VERSION ""

NS_ :

BS_:

BU_: DTCO ICL COO11 SRR6TRightMaster_R_Master SRR6TLeftMaster_L_Master
VAL_TABLE_ ErrorBits 1 "TRUE" 0 "FALSE" ;

BO_ 3221225472 VECTOR__INDEPENDENT_SIG_MSG: 0 Vector__XXX
 SG_ SRR6T_F_Diag_Response : 0|64@1+ (1,0) [0|0] "" Vector__XXX
 SG_ UDS_BASIS : 0|8@1+ (1,0) [0|255] "-" Vector__XXX
 SG_ SRRF_Object_E2E_CRC_09 : 0|16@1+ (1,0) [0|65535] "-" Vector__XXX
 SG_ SRRF_Object_E2E_Counter_09 : 0|8@1+ (1,0) [0|255] "-" Vector__XXX
 SG_ BatchId_SRRObj_F_09 : 0|3@1+ (1,0) [0|5] "-" Vector__XXX
 SG_ LonPosition_F_17 : 0|13@1+ (0.0625,-254.9375) [-254.9375|254.9375] "m" Vector__XXX
 SG_ LonPositionStd_F_17 : 0|10@1+ (0.025,0.025) [0.025|20] "m" Vector__XXX
 SG_ LatPosition_F_17 : 0|13@1+ (0.0625,-254.9375) [-254.9375|254.9375] "m" Vector__XXX
 SG_ LatPositionStd_F_17 : 0|10@1+ (0.025,0.025) [0.025|20] "m" Vector__XXX
 SG_ LonGndVel_F_17 : 0|13@1+ (0.0625,-170) [-170|170] "m/s" Vector__XXX
 SG_ LonGndVelStd_F_17 : 0|10@1+ (0.025,0.025) [0.025|14] "m/s" Vector__XXX
 SG_ LatGndVel_F_17 : 0|13@1+ (0.0625,-170) [-170|170] "m/s" Vector__XXX
 SG_ LatGndVelStd_F_17 : 0|10@1+ (0.025,0.025) [0.025|14] "m/s" Vector__XXX
 SG_ ExistenceProbability_F_17 : 0|8@1+ (0.4,0) [0|100] "%" Vector__XXX
 SG_ Width_F_17 : 0|8@1+ (0.1,0) [0|4] "m" Vector__XXX
 SG_ Length_F_17 : 0|10@1+ (0.1,0) [0|60] "m" Vector__XXX
 SG_ HeadingAngle_F_17 : 0|8@1+ (0.02618,-3.1416) [-3.1416|3.1416] "rad" Vector__XXX
 SG_ DynamicProperty_F_17 : 0|3@1+ (1,0) [0|5] "-" Vector__XXX
 SG_ ClassMostProb_F_17 : 0|3@1+ (1,0) [0|5] "-" Vector__XXX
 SG_ ClassMostProbConf_F_17 : 0|8@1+ (0.4,0) [0|100] "%" Vector__XXX
 SG_ ClassSecMostProb_F_17 : 0|3@1+ (1,0) [0|5] "-" Vector__XXX
 SG_ ClassSecMostProbConf_F_17 : 0|8@1+ (0.4,0) [0|100] "%" Vector__XXX
 SG_ MaintenanceState_F_17 : 0|3@1+ (1,0) [0|3] "-" Vector__XXX
 SG_ YawRate_F_17 : 0|16@1+ (0.0001220703125,-3) [-3|3] "rad/s" Vector__XXX
 SG_ Occlusion_F_17 : 0|3@1+ (1,0) [0|3] "-" Vector__XXX
 SG_ TrackingId_F_17 : 0|8@1+ (1,0) [0|250] "-" Vector__XXX
 SG_ ReferencePoint_F_17 : 0|4@1+ (1,0) [0|8] "-" Vector__XXX
 SG_ RadarCrossSection_F_17 : 0|11@1+ (0.1,0) [-100|100] "dBm²" Vector__XXX
 SG_ AgeSinceCreated_F_17 : 0|10@1+ (0.01,0) [0|10] "s" Vector__XXX
 SG_ LonPosition_F_18 : 0|13@1+ (0.0625,-254.9375) [-254.9375|254.9375] "m" Vector__XXX
 SG_ LonPositionStd_F_18 : 0|10@1+ (0.025,0.025) [0.025|20] "m" Vector__XXX
 SG_ LatPosition_F_18 : 0|13@1+ (0.0625,-254.9375) [-254.9375|254.9375] "m" Vector__XXX
 SG_ LatPositionStd_F_18 : 0|10@1+ (0.025,0.025) [0.025|20] "m" Vector__XXX
 SG_ LonGndVel_F_18 : 0|13@1+ (0.0625,-170) [-170|170] "m/s" Vector__XXX
 SG_ LonGndVelStd_F_18 : 0|10@1+ (0.025,0.025) [0.025|14] "m/s" Vector__XXX
 SG_ LatGndVel_F_18 : 0|13@1+ (0.0625,-170) [-170|170] "m/s" Vector__XXX
 SG_ LatGndVelStd_F_18 : 0|10@1+ (0.025,0.025) [0.025|14] "m/s" Vector__XXX
 SG_ ExistenceProbability_F_18 : 0|8@1+ (0.4,0) [0|100] "%" Vector__XXX
 SG_ Width_F_18 : 0|8@1+ (0.1,0) [0|4] "m" Vector__XXX
 SG_ Length_F_18 : 0|10@1+ (0.1,0) [0|60] "m" Vector__XXX
 SG_ HeadingAngle_F_18 : 0|8@1+ (0.02618,-3.1416) [-3.1416|3.1416] "rad" Vector__XXX
 SG_ DynamicProperty_F_18 : 0|3@1+ (1,0) [0|5] "-" Vector__XXX
 SG_ ClassMostProb_F_18 : 0|3@1+ (1,0) [0|5] "-" Vector__XXX
 SG_ ClassMostProbConf_F_18 : 0|8@1+ (0.4,0) [0|100] "%" Vector__XXX
 SG_ ClassSecMostProb_F_18 : 0|3@1+ (1,0) [0|5] "-" Vector__XXX
 SG_ ClassSecMostProbConf_F_18 : 0|8@1+ (0.4,0) [0|100] "%" Vector__XXX
 SG_ MaintenanceState_F_18 : 0|3@1+ (1,0) [0|3] "-" Vector__XXX
 SG_ YawRate_F_18 : 0|16@1+ (0.0001220703125,-3) [-3|3] "rad/s" Vector__XXX
 SG_ Occlusion_F_18 : 0|3@1+ (1,0) [0|3] "-" Vector__XXX
 SG_ TrackingId_F_18 : 0|8@1+ (1,0) [0|250] "-" Vector__XXX
 SG_ ReferencePoint_F_18 : 0|4@1+ (1,0) [0|8] "-" Vector__XXX
 SG_ RadarCrossSection_F_18 : 0|11@1+ (0.1,0) [-100|100] "dbm²" Vector__XXX
 SG_ AgeSinceCreated_F_18 : 0|10@1+ (0.01,0) [0|10] "s" Vector__XXX

BO_ 2631566074 GW_UDSreq_FA_2SRR_FR: 8 COO11
 SG_ SRR6T_Diag_Request : 0|64@1+ (1,0) [0|0] ""  SRR6TRightMaster_R_Master,SRR6TLeftMaster_L_Master

BO_ 2564460274 GW_UDSreq_SRR_FR_UUDT: 8 COO11
 SG_ SRR6T_R_Diag_Request : 0|64@1+ (1,0) [0|0] ""  SRR6TRightMaster_R_Master

BO_ 2564485773 UDSresp_SRR2_UUDT: 8 SRR6TLeftMaster_L_Master
 SG_ UDS_BASIS : 0|8@1+ (1,0) [0|255] "-" Vector__XXX

BO_ 2631596677 UDSresp_FA_2SRR_RL: 8 SRR6TLeftMaster_L_Master
 SG_ SRR6T_R_Diag_Response : 0|64@1+ (1,0) [0|0] "" Vector__XXX

BO_ 2564485774 GW_UDSresp_SRR_UUDT_FR: 8 SRR6TRightMaster_R_Master
 SG_ SRR6T_R_Diag_Response : 0|8@1+ (1,0) [0|0] "" Vector__XXX

BO_ 2631596674 GW_UDSresp_FA_2SRR_FR: 8 SRR6TRightMaster_R_Master
 SG_ SRR6T_R_Diag_Response : 0|64@1+ (1,0) [0|0] ""  COO11

BO_ 2564460530 UDSreq_SRR_RR_UUDT: 8 COO11
 SG_ SRR6T_Diag_Request : 0|64@1+ (1,0) [0|0] ""  SRR6TRightMaster_R_Master

BO_ 2564459762 GW_UDSreq_SRR_UUDT: 8 COO11
 SG_ SRR6T_Diag_Request : 0|64@1+ (1,0) [0|0] ""  SRR6TLeftMaster_L_Master,SRR6TRightMaster_R_Master

BO_ 2565603215 SRR6T_DM1_DT_RR: 8 SRR6TRightMaster_R_Master
 SG_ DM1_DT_placeholder : 0|64@1+ (1,0) [0|1.84467440737096E+019] "" Vector__XXX

BO_ 2565603214 SRR6T_DM1_DT_FR: 8 SRR6TRightMaster_R_Master
 SG_ DM1_DT_placeholder : 0|64@1+ (1,0) [0|1.84467440737096E+019] "" Vector__XXX

BO_ 2564460018 UDSreq_SRR_RL_UUDT: 8 COO11
 SG_ SRR6T_Diag_Request : 0|64@1+ (1,0) [0|0] ""  SRR6TLeftMaster_L_Master

BO_ 2631663610 UDSreq_FCN_FA_2SRR: 8 COO11
 SG_ SRR6T_Diag_Request : 0|64@1+ (1,0) [0|0] ""  SRR6TRightMaster_R_Master,SRR6TLeftMaster_L_Master

BO_ 2564554737 UDSreq_FCN_F12SRR: 8 COO11
 SG_ SRR6T_Diag_Request : 0|64@1+ (1,0) [0|0] ""  SRR6TRightMaster_R_Master,SRR6TLeftMaster_L_Master

BO_ 2631566842 UDSreq_FA_2SRR: 8 COO11
 SG_ SRR6T_Diag_Request : 0|64@1+ (1,0) [0|0] ""  SRR6TLeftMaster_L_Master

BO_ 2631566330 UDSreq_FA_2SRR_RR: 8 COO11
 SG_ SRR6T_Diag_Request : 0|64@1+ (1,0) [0|0] ""  SRR6TRightMaster_R_Master

BO_ 2631566586 GW_UDSreq_FA_2SRR: 8 COO11
 SG_ SRR6T_Diag_Request : 0|64@1+ (1,0) [0|0] ""  SRR6TRightMaster_R_Master,SRR6TLeftMaster_L_Master

BO_ 2631596675 UDSresp_FA_2SRR_RR: 8 SRR6TRightMaster_R_Master
 SG_ SRR6T_R_Diag_Response : 0|64@1+ (1,0) [0|0] ""  COO11

BO_ 2564485772 GW_UDSresp_SRR_UUDT: 8 SRR6TLeftMaster_L_Master
 SG_ SRR6T_R_Diag_Response : 0|8@1+ (1,0) [0|0] ""  COO11

BO_ 2631596676 GW_UDSresp_FA_2SRR: 8 SRR6TLeftMaster_L_Master
 SG_ SRR6T_R_Diag_Response : 0|64@1+ (1,0) [0|0] ""  COO11

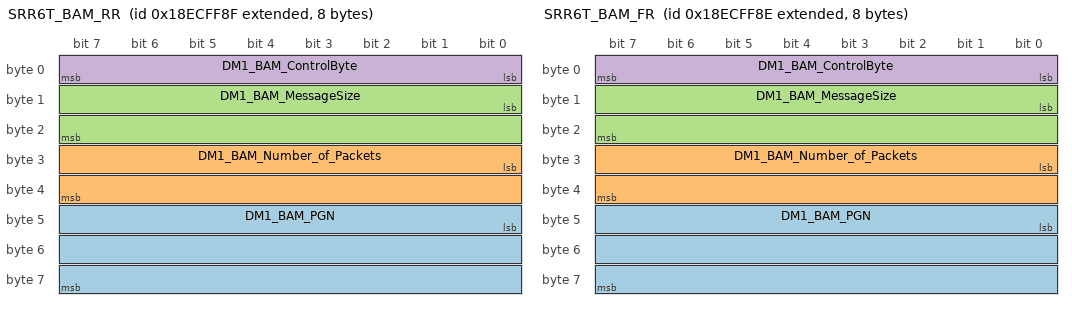
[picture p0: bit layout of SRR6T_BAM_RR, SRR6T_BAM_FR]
BO_ 2565668751 SRR6T_BAM_RR: 8 SRR6TRightMaster_R_Master
 SG_ DM1_BAM_PGN : 40|24@1+ (1,0) [0|16777215] "" Vector__XXX
 SG_ DM1_BAM_Number_of_Packets : 24|16@1+ (1,0) [0|65535] "" Vector__XXX
 SG_ DM1_BAM_MessageSize : 8|16@1+ (1,0) [0|65535] "" Vector__XXX
 SG_ DM1_BAM_ControlByte : 0|8@1+ (1,0) [0|255] "" Vector__XXX

BO_ 2565668750 SRR6T_BAM_FR: 8 SRR6TRightMaster_R_Master
 SG_ DM1_BAM_PGN : 40|24@1+ (1,0) [0|16777215] "" Vector__XXX
 SG_ DM1_BAM_Number_of_Packets : 24|16@1+ (1,0) [0|65535] "" Vector__XXX
 SG_ DM1_BAM_MessageSize : 8|16@1+ (1,0) [0|65535] "" Vector__XXX
 SG_ DM1_BAM_ControlByte : 0|8@1+ (1,0) [0|255] "" Vector__XXX

BO_ 2565603213 SRR6T_DM1_DT_RL: 8 SRR6TLeftMaster_L_Master
 SG_ DM1_DT_placeholder : 0|64@1+ (1,0) [0|1.84467440737096E+019] "" Vector__XXX

BO_ 2565603212 SRR6T_DM1_DT_FL: 8 SRR6TLeftMaster_L_Master
 SG_ DM1_DT_placeholder : 0|64@1+ (1,0) [0|1.84467440737096E+019] "" Vector__XXX

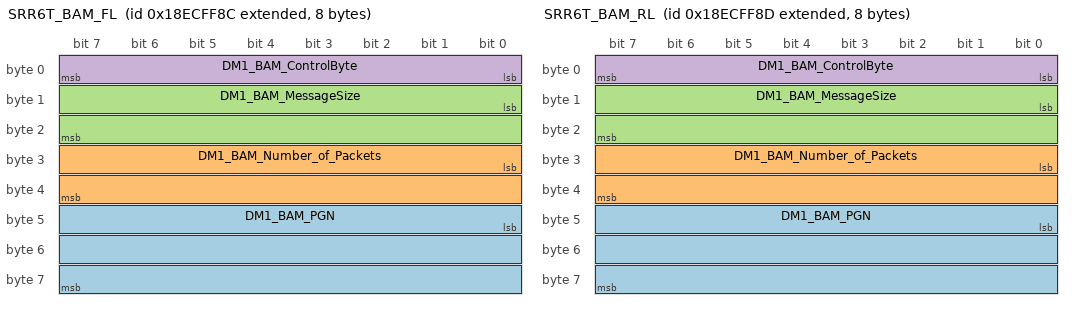
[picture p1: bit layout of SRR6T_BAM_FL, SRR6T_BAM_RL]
BO_ 2565668748 SRR6T_BAM_FL: 8 SRR6TLeftMaster_L_Master
 SG_ DM1_BAM_PGN : 40|24@1+ (1,0) [0|16777215] "" Vector__XXX
 SG_ DM1_BAM_Number_of_Packets : 24|16@1+ (1,0) [0|65535] "" Vector__XXX
 SG_ DM1_BAM_MessageSize : 8|16@1+ (1,0) [0|65535] "" Vector__XXX
 SG_ DM1_BAM_ControlByte : 0|8@1+ (1,0) [0|255] "" Vector__XXX

BO_ 2565668749 SRR6T_BAM_RL: 8 SRR6TLeftMaster_L_Master
 SG_ DM1_BAM_PGN : 40|24@1+ (1,0) [0|16777215] "" Vector__XXX
 SG_ DM1_BAM_Number_of_Packets : 24|16@1+ (1,0) [0|65535] "" Vector__XXX
 SG_ DM1_BAM_MessageSize : 8|16@1+ (1,0) [0|65535] "" Vector__XXX
 SG_ DM1_BAM_ControlByte : 0|8@1+ (1,0) [0|255] "" Vector__XXX

BO_ 2564485775 UDSresp_SRR4_UUDT: 8 SRR6TRightMaster_R_Master
 SG_ UDS_BASIS : 0|8@1+ (1,0) [0|255] "-"  COO11

BO_ 2566834829 DM1_SRR2D: 48 SRR6TLeftMaster_L_Master
 SG_ DM1_placeholder_BASE : 0|8@1+ (1,0) [0|255] "-"  COO11

BO_ 2566834831 DM1_SRR2B: 48 SRR6TRightMaster_R_Master
 SG_ DM1_placeholder_BASE : 0|8@1+ (1,0) [0|255] "-"  COO11

BO_ 2566834828 DM1_SRR2C: 48 SRR6TLeftMaster_L_Master
 SG_ DM1_placeholder_BASE : 0|8@1+ (1,0) [0|255] "-"  COO11

BO_ 2566834830 DM1_SRR2A: 48 SRR6TRightMaster_R_Master
 SG_ DM1_placeholder_BASE : 0|8@1+ (1,0) [0|255] "-"  COO11

BO_ 2564485262 UDSresp_SRR32F0: 8 SRR6TRightMaster_R_Master
 SG_ UDS_BASIS : 0|8@1+ (1,0) [0|255] "-"  COO11

BO_ 2564485374 UDSresp_SRR52F0: 8 Vector__XXX
 SG_ UDS_BASIS : 0|8@1+ (1,0) [0|255] "-"  COO11

BO_ 2564485260 UDSresp_SRR12F0: 8 SRR6TLeftMaster_L_Master
 SG_ UDS_BASIS : 0|8@1+ (1,0) [0|255] "-"  COO11

BO_ 2564485263 UDSresp_SRR42F0: 8 SRR6TRightMaster_R_Master
 SG_ UDS_BASIS : 0|8@1+ (1,0) [0|255] "-"  COO11

BO_ 2564485261 UDSresp_SRR22F0: 8 SRR6TLeftMaster_L_Master
 SG_ UDS_BASIS : 0|8@1+ (1,0) [0|255] "-"  COO11

BO_ 2564485518 UDSresp_SRR32F1: 8 SRR6TRightMaster_R_Master
 SG_ UDS_BASIS : 0|8@1+ (1,0) [0|255] "-"  COO11

BO_ 2564485630 UDSresp_SRR52F1: 8 Vector__XXX
 SG_ UDS_BASIS : 0|8@1+ (1,0) [0|255] "-"  COO11

BO_ 2564485519 UDSresp_SRR42F1: 8 SRR6TRightMaster_R_Master
 SG_ UDS_BASIS : 0|8@1+ (1,0) [0|255] "-"  COO11

BO_ 2564485517 UDSresp_SRR22F1: 8 SRR6TLeftMaster_L_Master
 SG_ UDS_BASIS : 0|8@1+ (1,0) [0|255] "-"  COO11

BO_ 2564485516 UDSresp_SRR12F1: 8 SRR6TLeftMaster_L_Master
 SG_ UDS_BASIS : 0|8@1+ (1,0) [0|255] "-"  COO11

BO_ 2564460273 UDSreq_F12SRR3: 8 COO11
 SG_ UDS_BASIS : 0|8@1+ (1,0) [0|255] "-"  SRR6TRightMaster_R_Master

BO_ 2564471025 UDSreq_F12SRR5: 8 COO11
 SG_ UDS_BASIS : 0|8@1+ (1,0) [0|255] "-" Vector__XXX

BO_ 2564460017 UDSreq_F12SRR2: 8 COO11
 SG_ UDS_BASIS : 0|8@1+ (1,0) [0|255] "-"  SRR6TLeftMaster_L_Master

BO_ 2564460529 UDSreq_F12SRR4: 8 COO11
 SG_ UDS_BASIS : 0|8@1+ (1,0) [0|255] "-"  SRR6TRightMaster_R_Master

BO_ 2564459761 UDSreq_F12SRR1: 8 COO11
 SG_ UDS_BASIS : 0|8@1+ (1,0) [0|255] "-"  SRR6TLeftMaster_L_Master

BO_ 2564460016 UDSreq_F02SRR2: 8 COO11
 SG_ UDS_BASIS : 0|8@1+ (1,0) [0|255] "-"  SRR6TLeftMaster_L_Master

BO_ 2564460272 UDSreq_F02SRR3: 8 COO11
 SG_ UDS_BASIS : 0|8@1+ (1,0) [0|255] "-"  SRR6TRightMaster_R_Master

BO_ 2564460528 UDSreq_F02SRR4: 8 COO11
 SG_ UDS_BASIS : 0|8@1+ (1,0) [0|255] "-"  SRR6TRightMaster_R_Master

BO_ 2564488944 UDSreq_F02SRR5: 8 COO11
 SG_ UDS_BASIS : 0|8@1+ (1,0) [0|255] "-" Vector__XXX

BO_ 2564459760 UDSreq_F02SRR1: 8 COO11
 SG_ UDS_BASIS : 0|8@1+ (1,0) [0|255] "-"  SRR6TLeftMaster_L_Master

BO_ 2564554736 UDSreqFCN_F0_TO_ALL: 8 COO11
 SG_ UDS_FCNF0_TO_ALL : 0|8@1+ (1,0) [0|255] "-"  SRR6TRightMaster_R_Master,SRR6TLeftMaster_L_Master

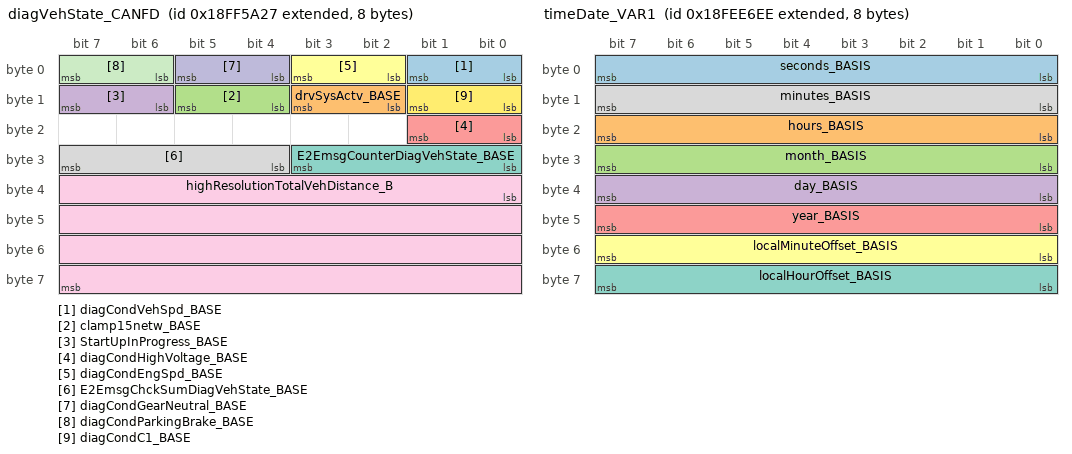
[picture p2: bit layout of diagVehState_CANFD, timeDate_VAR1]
BO_ 2566871591 diagVehState_CANFD: 8 COO11
 SG_ diagCondVehSpd_BASE : 0|2@1+ (1,0) [0|0] "-"  SRR6TLeftMaster_L_Master,SRR6TRightMaster_R_Master
 SG_ drvSysActv_BASE : 10|2@1+ (1,0) [0|0] "-"  SRR6TLeftMaster_L_Master,SRR6TRightMaster_R_Master
 SG_ clamp15netw_BASE : 12|2@1+ (1,0) [0|0] "-"  SRR6TLeftMaster_L_Master,SRR6TRightMaster_R_Master
 SG_ StartUpInProgress_BASE : 14|2@1+ (1,0) [0|3] "-"  SRR6TLeftMaster_L_Master,SRR6TRightMaster_R_Master
 SG_ diagCondHighVoltage_BASE : 16|2@1+ (1,0) [0|0] "-"  SRR6TLeftMaster_L_Master,SRR6TRightMaster_R_Master
 SG_ diagCondEngSpd_BASE : 2|2@1+ (1,0) [0|0] "-"  SRR6TLeftMaster_L_Master,SRR6TRightMaster_R_Master
 SG_ E2EmsgCounterDiagVehState_BASE : 24|4@1+ (1,0) [0|15] "count"  SRR6TLeftMaster_L_Master,SRR6TRightMaster_R_Master
 SG_ E2EmsgChckSumDiagVehState_BASE : 28|4@1+ (1,0) [0|15] "count"  SRR6TLeftMaster_L_Master,SRR6TRightMaster_R_Master
 SG_ highResolutionTotalVehDistance_B : 32|32@1+ (0.005,0) [0|21055406] "km"  SRR6TLeftMaster_L_Master,SRR6TRightMaster_R_Master
 SG_ diagCondGearNeutral_BASE : 4|2@1+ (1,0) [0|0] "-"  SRR6TLeftMaster_L_Master,SRR6TRightMaster_R_Master
 SG_ diagCondParkingBrake_BASE : 6|2@1+ (1,0) [0|0] "-"  SRR6TLeftMaster_L_Master,SRR6TRightMaster_R_Master
 SG_ diagCondC1_BASE : 8|2@1+ (1,0) [0|3] "-"  SRR6TLeftMaster_L_Master,SRR6TRightMaster_R_Master

BO_ 2566842094 timeDate_VAR1: 8 DTCO
 SG_ seconds_BASIS : 0|8@1+ (0.25,0) [0|62.5] "s"  SRR6TLeftMaster_L_Master,SRR6TRightMaster_R_Master
 SG_ hours_BASIS : 16|8@1+ (1,0) [0|250] "h"  SRR6TLeftMaster_L_Master,SRR6TRightMaster_R_Master
 SG_ month_BASIS : 24|8@1+ (1,0) [0|250] "month"  SRR6TLeftMaster_L_Master,SRR6TRightMaster_R_Master
 SG_ day_BASIS : 32|8@1+ (0.25,0) [0|62.5] "day"  SRR6TLeftMaster_L_Master,SRR6TRightMaster_R_Master
 SG_ year_BASIS : 40|8@1+ (1,1985) [1985|2235] "year"  SRR6TLeftMaster_L_Master,SRR6TRightMaster_R_Master
 SG_ localMinuteOffset_BASIS : 48|8@1+ (1,-125) [-125|125] "min"  SRR6TLeftMaster_L_Master,SRR6TRightMaster_R_Master
 SG_ localHourOffset_BASIS : 56|8@1+ (1,-125) [-125|125] "h"  SRR6TLeftMaster_L_Master,SRR6TRightMaster_R_Master
 SG_ minutes_BASIS : 8|8@1+ (1,0) [0|250] "min"  SRR6TLeftMaster_L_Master,SRR6TRightMaster_R_Master

BO_ 2600402983 NM: 8 COO11
 SG_ NM_SNI : 0|8@1+ (1,0) [0|255] "-" Vector__XXX
 SG_ NM_CBV_Res2 : 10|1@1+ (1,0) [0|1] "-"  SRR6TRightMaster_R_Master,SRR6TLeftMaster_L_Master
 SG_ NM_CBV_Res3 : 11|1@1+ (1,0) [0|1] "-"  SRR6TRightMaster_R_Master,SRR6TLeftMaster_L_Master
 SG_ NM_ActiveWakeupBit : 12|1@1+ (1,0) [0|0] "-"  SRR6TRightMaster_R_Master,SRR6TLeftMaster_L_Master
 SG_ NM_CBV_Res5 : 13|1@1+ (1,0) [0|1] "-"  SRR6TRightMaster_R_Master,SRR6TLeftMaster_L_Master
 SG_ NM_CRI : 14|1@1+ (1,0) [0|0] "-"  SRR6TRightMaster_R_Master,SRR6TLeftMaster_L_Master
 SG_ NM_CBV_Res7 : 15|1@1+ (1,0) [0|1] "-"  SRR6TRightMaster_R_Master,SRR6TLeftMaster_L_Master
 SG_ NM_State : 16|6@1+ (1,0) [0|0] "-"  SRR6TRightMaster_R_Master,SRR6TLeftMaster_L_Master
 SG_ NM_CarWakeup : 22|1@1+ (1,0) [0|0] "-"  SRR6TRightMaster_R_Master,SRR6TLeftMaster_L_Master
 SG_ NM_CC : 23|1@1+ (1,0) [0|0] "-"  SRR6TRightMaster_R_Master,SRR6TLeftMaster_L_Master
 SG_ NM_activeClamp15 : 24|1@1+ (1,0) [0|1] "-"  SRR6TRightMaster_R_Master,SRR6TLeftMaster_L_Master
 SG_ NM_activeDiag : 25|1@1+ (1,0) [0|0] "-"  SRR6TRightMaster_R_Master,SRR6TLeftMaster_L_Master
 SG_ NM_activeTmin : 26|1@1+ (1,0) [0|0] "-"  SRR6TRightMaster_R_Master,SRR6TLeftMaster_L_Master
 SG_ NM_activeCWU : 27|1@1+ (1,0) [0|0] "-"  SRR6TRightMaster_R_Master,SRR6TLeftMaster_L_Master
 SG_ NM_activeFC : 28|1@1+ (1,0) [0|0] "-"  SRR6TRightMaster_R_Master,SRR6TLeftMaster_L_Master
 SG_ NM_Res29 : 29|7@1+ (1,0) [0|127] "-"  SRR6TRightMaster_R_Master,SRR6TLeftMaster_L_Master
 SG_ NM_Res36 : 36|4@1+ (1,0) [0|15] "-"  SRR6TRightMaster_R_Master,SRR6TLeftMaster_L_Master
 SG_ nmClusterActive00 : 40|1@1+ (1,0) [0|0] "-"  SRR6TRightMaster_R_Master,SRR6TLeftMaster_L_Master
 SG_ nmClusterActive01 : 41|1@1+ (1,0) [0|0] "-"  SRR6TRightMaster_R_Master,SRR6TLeftMaster_L_Master
 SG_ nmClusterActive02 : 42|1@1+ (1,0) [0|0] "-"  SRR6TRightMaster_R_Master,SRR6TLeftMaster_L_Master
 SG_ nmClusterActive03 : 43|1@1+ (1,0) [0|0] "-"  SRR6TRightMaster_R_Master,SRR6TLeftMaster_L_Master
 SG_ nmClusterActive04 : 44|1@1+ (1,0) [0|0] "-"  SRR6TRightMaster_R_Master,SRR6TLeftMaster_L_Master
 SG_ nmClusterActive05 : 45|1@1+ (1,0) [0|0] "-"  SRR6TRightMaster_R_Master,SRR6TLeftMaster_L_Master
 SG_ nmClusterActive06 : 46|1@1+ (1,0) [0|0] "-"  SRR6TRightMaster_R_Master,SRR6TLeftMaster_L_Master
 SG_ nmClusterActive07 : 47|1@1+ (1,0) [0|0] "-"  SRR6TRightMaster_R_Master,SRR6TLeftMaster_L_Master
 SG_ nmClusterActive08 : 48|1@1+ (1,0) [0|0] "-"  SRR6TRightMaster_R_Master,SRR6TLeftMaster_L_Master
 SG_ nmClusterActive09 : 49|1@1+ (1,0) [0|0] "-"  SRR6TRightMaster_R_Master,SRR6TLeftMaster_L_Master
 SG_ nmClusterActive10 : 50|1@1+ (1,0) [0|0] "-"  SRR6TRightMaster_R_Master,SRR6TLeftMaster_L_Master
 SG_ nmClusterActive11 : 51|1@1+ (1,0) [0|0] "-"  SRR6TRightMaster_R_Master,SRR6TLeftMaster_L_Master
 SG_ nmClusterActive12 : 52|1@1+ (1,0) [0|0] "-"  SRR6TRightMaster_R_Master,SRR6TLeftMaster_L_Master
 SG_ nmClusterActive13 : 53|1@1+ (1,0) [0|0] "-"  SRR6TRightMaster_R_Master,SRR6TLeftMaster_L_Master
 SG_ nmClusterActive14 : 54|1@1+ (1,0) [0|0] "-"  SRR6TRightMaster_R_Master,SRR6TLeftMaster_L_Master
 SG_ nmClusterActive15 : 55|1@1+ (1,0) [0|0] "-"  SRR6TRightMaster_R_Master,SRR6TLeftMaster_L_Master
 SG_ nmClusterActive16 : 56|1@1+ (1,0) [0|0] "-"  SRR6TRightMaster_R_Master,SRR6TLeftMaster_L_Master
 SG_ nmClusterActive17 : 57|1@1+ (1,0) [0|0] "-"  SRR6TRightMaster_R_Master,SRR6TLeftMaster_L_Master
 SG_ nmClusterActive18 : 58|1@1+ (1,0) [0|0] "-"  SRR6TRightMaster_R_Master,SRR6TLeftMaster_L_Master
 SG_ nmClusterActive19 : 59|1@1+ (1,0) [0|0] "-"  SRR6TRightMaster_R_Master,SRR6TLeftMaster_L_Master
 SG_ nmClusterActive20 : 60|1@1+ (1,0) [0|0] "-"  SRR6TRightMaster_R_Master,SRR6TLeftMaster_L_Master
 SG_ nmClusterActive21 : 61|1@1+ (1,0) [0|0] "-"  SRR6TRightMaster_R_Master,SRR6TLeftMaster_L_Master
 SG_ nmClusterActive22 : 62|1@1+ (1,0) [0|0] "-"  SRR6TRightMaster_R_Master,SRR6TLeftMaster_L_Master
 SG_ nmClusterActive23 : 63|1@1+ (1,0) [0|0] "-"  SRR6TRightMaster_R_Master,SRR6TLeftMaster_L_Master
 SG_ NM_CBV_Res0 : 8|1@1+ (1,0) [0|1] "-"  SRR6TRightMaster_R_Master,SRR6TLeftMaster_L_Master
 SG_ NM_CBV_Res1 : 9|1@1+ (1,0) [0|1] "-"  SRR6TRightMaster_R_Master,SRR6TLeftMaster_L_Master

BO_ 2566566695 CanTSyn_CANFD_K: 8 COO11
 SG_ Type M : 0|8@1+ (1,0) [0|0] "-"  SRR6TRightMaster_R_Master,SRR6TLeftMaster_L_Master
 SG_ CRC_Sync m32 : 8|8@1+ (1,0) [0|255] "-"  SRR6TRightMaster_R_Master,SRR6TLeftMaster_L_Master
 SG_ CRC_Fup m40 : 8|8@1+ (1,0) [0|255] "-"  SRR6TRightMaster_R_Master,SRR6TLeftMaster_L_Master
 SG_ SequenceCounter_Sync m32 : 16|4@1+ (1,0) [0|15] "-"  SRR6TRightMaster_R_Master,SRR6TLeftMaster_L_Master
 SG_ SequenceCounter_Fup m40 : 16|4@1+ (1,0) [0|15] "-"  SRR6TRightMaster_R_Master,SRR6TLeftMaster_L_Master
 SG_ TimeDomain_Sync m32 : 20|4@1+ (1,0) [0|15] "-"  SRR6TRightMaster_R_Master,SRR6TLeftMaster_L_Master
 SG_ TimeDomain_Fup m40 : 20|4@1+ (1,0) [0|15] "-"  SRR6TRightMaster_R_Master,SRR6TLeftMaster_L_Master
 SG_ UserByte0_Sync m32 : 24|8@1+ (1,0) [0|255] "-"  SRR6TRightMaster_R_Master,SRR6TLeftMaster_L_Master
 SG_ OVS_Fup m40 : 24|2@1+ (1,0) [0|3] "-"  SRR6TRightMaster_R_Master,SRR6TLeftMaster_L_Master
 SG_ SGW_Fup m40 : 26|1@1+ (1,0) [0|1] "-"  SRR6TRightMaster_R_Master,SRR6TLeftMaster_L_Master
 SG_ Reserved_Fup m40 : 27|5@1+ (1,0) [0|31] "-"  SRR6TRightMaster_R_Master,SRR6TLeftMaster_L_Master
 SG_ SyncTimeSec_Sync m32 : 39|32@0+ (1,0) [0|4294967295] "s"  SRR6TRightMaster_R_Master,SRR6TLeftMaster_L_Master
 SG_ SyncTimeNSec_Fup m40 : 39|32@0+ (1,0) [0|4294967295] ""  SRR6TRightMaster_R_Master,SRR6TLeftMaster_L_Master

BO_ 2566843533 VI_5000_L_SRR2: 8 SRR6TLeftMaster_L_Master
 SG_ VehicleID_7digits_L_SRR2 : 0|56@1+ (1,0) [0|0] ""  COO11
 SG_ Delimiter_L_SRR2 : 56|8@1+ (1,0) [0|250] "ASCII '*'"  COO11

BO_ 2566843535 VI_5000_R_SRR2: 8 SRR6TRightMaster_R_Master
 SG_ VehicleID_7digits_R_SRR2 : 0|56@1+ (1,0) [0|0] ""  COO11
 SG_ Delimiter_R_SRR2 : 56|8@1+ (1,0) [0|250] "ASCII '*'"  COO11

BO_ 2399091597 SRRL_Header_SRR2: 64 SRR6TLeftMaster_L_Master
 SG_ Scan_Index_L : 304|16@1+ (1,0) [0|65535] "" Vector__XXX
 SG_ SlaveDetectionTimestampSeconds_L : 272|32@1+ (1,0) [0|4294967295] "s" Vector__XXX
 SG_ SlaveDetTimestampNanosec_L : 240|32@1+ (1,0) [0|999999999] "ns" Vector__XXX
 SG_ MasterDetectionTimestampSeconds_ : 208|32@1+ (1,0) [0|4294967295] "s" Vector__XXX
 SG_ MasterDetTimestampNanosec_L : 176|32@1+ (1,0) [0|999999999] "ns" Vector__XXX
 SG_ SRRL_Header_E2E_CRC : 0|16@1+ (1,0) [0|65535] "-"  COO11
 SG_ SRRL_Header_E2E_Counter : 16|8@1+ (1,0) [0|255] "-"  COO11
 SG_ BatchId_SRRHead_L : 24|3@1+ (1,0) [0|5] "-"  COO11
 SG_ StateMachineStatus_L : 27|4@1+ (1,0) [0|4] "-"  COO11
 SG_ BlockageMaster_L : 31|2@1+ (1,0) [0|1] "-"  COO11
 SG_ BlockageSlave_L : 33|2@1+ (1,0) [0|1] "-"  COO11
 SG_ TemperatureMaster_L : 35|8@1+ (1,-50) [-50|200] "deg celsius"  COO11
 SG_ TemperatureSlave_L : 43|8@1+ (1,-50) [-50|200] "deg celsius"  COO11
 SG_ AlignmentAngleMaster_L : 51|8@1+ (0.00136353847,-0.17180584722) [-0.17180584722|0.17180584722] "rad"  COO11
 SG_ AlignmentAngleSlave_L : 59|8@1+ (0.00136353847,-0.17180584722) [-0.17180584722|0.17180584722] "rad"  COO11
 SG_ AlignmentStatusMaster_L : 67|3@1+ (1,0) [0|3] "-"  COO11
 SG_ AlignmentStatusSlave_L : 70|3@1+ (1,0) [0|3] "-"  COO11
 SG_ AutoAlignmentActiveMaster_L : 73|2@1+ (1,0) [0|1] "-"  COO11
 SG_ AutoAlignmentActiveSlave_L : 75|2@1+ (1,0) [0|1] "-"  COO11
 SG_ ErrorBits_L : 77|32@1+ (1,0) [0|1] "-"  COO11
 SG_ ObjectTimestampSeconds_L : 109|32@1+ (1,0) [0|4294967295] "s"  COO11
 SG_ ObjectTimestampNanoseconds_L : 141|32@1+ (1,0) [0|999999999] "ns"  COO11
 SG_ CanTSynState_L : 173|3@1+ (1,0) [0|7] "-"  COO11

BO_ 2399091599 SRRR_Header_SRR2: 64 SRR6TRightMaster_R_Master
 SG_ Scan_Index_R : 304|16@1+ (1,0) [0|65535] "" Vector__XXX
 SG_ SlaveDetectionTimestampSeconds_R : 272|32@1+ (1,0) [0|4294967295] "s" Vector__XXX
 SG_ SlaveDetTimestampNanosec_R : 240|32@1+ (1,0) [0|999999999] "ns" Vector__XXX
 SG_ MasterDetectionTimestampSec_0000 : 208|32@1+ (1,0) [0|4294967295] "s" Vector__XXX
 SG_ MasterDetTimestampNanosec_R : 176|32@1+ (1,0) [0|999999999] "ns" Vector__XXX
 SG_ SRRR_Header_E2E_CRC : 0|16@1+ (1,0) [0|65535] "-"  COO11
 SG_ SRRR_Header_E2E_Counter : 16|8@1+ (1,0) [0|255] "-"  COO11
 SG_ BatchId_SRRHead_R : 24|3@1+ (1,0) [0|5] "-"  COO11
 SG_ StateMachineStatus_R : 27|4@1+ (1,0) [0|4] "-"  COO11
 SG_ BlockageMaster_R : 31|2@1+ (1,0) [0|1] "-"  COO11
 SG_ BlockageSlave_R : 33|2@1+ (1,0) [0|1] "-"  COO11
 SG_ TemperatureMaster_R : 35|8@1+ (1,-50) [-50|200] "deg celsius"  COO11
 SG_ TemperatureSlave_R : 43|8@1+ (1,-50) [-50|200] "deg celsius"  COO11
 SG_ AlignmentAngleMaster_R : 51|8@1+ (0.00136353847,-0.17180584722) [-0.17180584722|0.17180584722] "rad"  COO11
 SG_ AlignmentAngleSlave_R : 59|8@1+ (0.00136353847,-0.17180584722) [-0.17180584722|0.17180584722] "rad"  COO11
 SG_ AlignmentStatusMaster_R : 67|3@1+ (1,0) [0|3] "-"  COO11
 SG_ AlignmentStatusSlave_R : 70|3@1+ (1,0) [0|3] "-"  COO11
 SG_ AutoAlignmentActiveMaster_R : 73|2@1+ (1,0) [0|1] "-"  COO11
 SG_ AutoAlignmentActiveSlave_R : 75|2@1+ (1,0) [0|1] "-"  COO11
 SG_ ErrorBits_R : 77|32@1+ (1,0) [0|1] "-"  COO11
 SG_ ObjectTimestampSeconds_R : 109|32@1+ (1,0) [0|4294967295] "s"  COO11
 SG_ ObjectTimestampNanoseconds_R : 141|32@1+ (1,0) [0|999999999] "ns"  COO11
 SG_ CanTSynState_R : 173|3@1+ (1,0) [0|7] "-"  COO11

BO_ 2399092621 SRRL_TrailerInfo_SRR2: 20 SRR6TLeftMaster_L_Master
 SG_ SRRL_TrailerInfo_E2E_CRC : 0|16@1+ (1,0) [0|65535] "-"  COO11
 SG_ SRRL_TrailerInfo_E2E_Counter : 16|8@1+ (1,0) [0|255] "-"  COO11
 SG_ BatchId_SRRTrai_L : 24|3@1+ (1,0) [0|5] "-"  COO11
 SG_ TrailerFilterState_L : 27|3@1+ (1,0) [0|3] "-"  COO11
 SG_ Trailer1Present_L : 30|2@1+ (1,0) [0|3] "-"  COO11
 SG_ Trailer1Length_L : 32|8@1+ (0.1,0) [0|25] "m"  COO11
 SG_ Trailer1Width_L : 40|6@1+ (0.1,0) [0|6] "m"  COO11
 SG_ Trailer1Angle_L : 46|12@1+ (0.001953125,-3.142578125) [-3.142578125|3.142578125] "rad"  COO11
 SG_ Trailer1AngleConf_L : 58|4@1+ (1,0) [0|3] "-"  COO11
 SG_ Trailer1CentOfRotToCentDist_L : 62|7@1+ (0.1,0) [0|12.5] "m"  COO11
 SG_ Trailer1CentOfRotToWheelDist_L : 69|9@1+ (0.1,0) [0|50] "m"  COO11
 SG_ Trailer1CentOfRotVCSLon_L : 78|8@1+ (0.1,-24.5) [-24.5|0.5] "m"  COO11
 SG_ Trailer1CentOfRotVCSLat_L : 86|9@1+ (0.1,-24.5) [-24.5|26.4] "m"  COO11
 SG_ Trailer2Present_L : 95|2@1+ (1,0) [0|3] "-"  COO11
 SG_ Trailer2Length_L : 97|8@1+ (0.1,0) [0|25] "m"  COO11
 SG_ Trailer2Width_L : 105|6@1+ (0.1,0) [0|6] "m"  COO11
 SG_ Trailer2Angle_L : 111|12@1+ (0.001953125,-3.142578125) [-3.142578125|3.142578125] "rad"  COO11
 SG_ Trailer2AngleConf_L : 123|4@1+ (1,0) [0|3] "-"  COO11
 SG_ Trailer2CentOfRotToCentDist_L : 127|7@1+ (0.1,0) [0|12.5] "m"  COO11
 SG_ Trailer2CentOfRotToWheelDist_L : 134|9@1+ (0.1,0) [0|50] "m"  COO11
 SG_ Trailer2CentOfRotVCSLon_L : 143|8@1+ (0.1,-24.5) [-24.5|0.5] "m"  COO11
 SG_ Trailer2CentOfRotVCSLat_L : 151|9@1+ (0.1,-24.5) [-24.5|26.4] "m"  COO11

BO_ 2399092623 SRRR_TrailerInfo_SRR2: 20 SRR6TRightMaster_R_Master
 SG_ SRRR_TrailerInfo_E2E_CRC : 0|16@1+ (1,0) [0|65535] "-"  COO11
 SG_ SRRR_TrailerInfo_E2E_Counter : 16|8@1+ (1,0) [0|255] "-"  COO11
 SG_ BatchId_SRRTrai_R : 24|3@1+ (1,0) [0|5] "-"  COO11
 SG_ TrailerFilterState_R : 27|3@1+ (1,0) [0|3] "-"  COO11
 SG_ Trailer1Present_R : 30|2@1+ (1,0) [0|3] "-"  COO11
 SG_ Trailer1Length_R : 32|8@1+ (0.1,0) [0|25] "m"  COO11
 SG_ Trailer1Width_R : 40|6@1+ (0.1,0) [0|6] "m"  COO11
 SG_ Trailer1Angle_R : 46|12@1+ (0.001953125,-3.142578125) [-3.142578125|3.142578125] "rad"  COO11
 SG_ Trailer1AngleConf_R : 58|4@1+ (1,0) [0|3] "-"  COO11
 SG_ Trailer1CentOfRotToCentDist_R : 62|7@1+ (0.1,0) [0|12.5] "m"  COO11
 SG_ Trailer1CentOfRotToWheelDist_R : 69|9@1+ (0.1,0) [0|50] "m"  COO11
 SG_ Trailer1CentOfRotVCSLon_R : 78|8@1+ (0.1,-24.5) [-24.5|0.5] "m"  COO11
 SG_ Trailer1CentOfRotVCSLat_R : 86|9@1+ (0.1,-24.5) [-24.5|26.4] "m"  COO11
 SG_ Trailer2Present_R : 95|2@1+ (1,0) [0|3] "-"  COO11
 SG_ Trailer2Length_R : 97|8@1+ (0.1,0) [0|25] "m"  COO11
 SG_ Trailer2Width_R : 105|6@1+ (0.1,0) [0|6] "m"  COO11
 SG_ Trailer2Angle_R : 111|12@1+ (0.001953125,-3.142578125) [-3.142578125|3.142578125] "rad"  COO11
 SG_ Trailer2AngleConf_R : 123|4@1+ (1,0) [0|3] "-"  COO11
 SG_ Trailer2CentOfRotToCentDist_R : 127|7@1+ (0.1,0) [0|12.5] "m"  COO11
 SG_ Trailer2CentOfRotToWheelDist_R : 134|9@1+ (0.1,0) [0|50] "m"  COO11
 SG_ Trailer2CentOfRotVCSLon_R : 143|8@1+ (0.1,-24.5) [-24.5|0.5] "m"  COO11
 SG_ Trailer2CentOfRotVCSLat_R : 151|9@1+ (0.1,-24.5) [-24.5|26.4] "m"  COO11

BO_ 2399091853 SRRL_RoadBoundaryHeader_SRR2: 16 SRR6TLeftMaster_L_Master
 SG_ SRRL_RoadBoundaryHeader_E2E_CRC : 0|16@1+ (1,0) [0|65535] "-"  COO11
 SG_ SRRL_RoadBoundaryHeader_E2E_Cntr : 16|8@1+ (1,0) [0|255] "-"  COO11
 SG_ BatchId_SRRBoundHdr_L : 24|3@1+ (1,0) [0|5] "-"  COO11
 SG_ NumCountours_L : 27|4@1+ (1,0) [0|6] "-"  COO11
 SG_ CountourId_L_01 : 31|6@1+ (1,0) [0|61] "-"  COO11
 SG_ NumCountourVertices_L_01 : 37|6@1+ (1,0) [0|32] "-"  COO11
 SG_ CountourId_L_02 : 43|6@1+ (1,0) [0|61] "-"  COO11
 SG_ NumCountourVertices_L_02 : 49|6@1+ (1,0) [0|32] "-"  COO11
 SG_ CountourId_L_03 : 55|6@1+ (1,0) [0|61] "-"  COO11
 SG_ NumCountourVertices_L_03 : 61|6@1+ (1,0) [0|32] "-"  COO11
 SG_ CountourId_L_04 : 67|6@1+ (1,0) [0|61] "-"  COO11
 SG_ NumCountourVertices_L_04 : 73|6@1+ (1,0) [0|32] "-"  COO11
 SG_ CountourId_L_05 : 79|6@1+ (1,0) [0|61] "-"  COO11
 SG_ NumCountourVertices_L_05 : 85|6@1+ (1,0) [0|32] "-"  COO11
 SG_ CountourId_L_06 : 91|6@1+ (1,0) [0|61] "-"  COO11
 SG_ NumCountourVertices_L_06 : 97|6@1+ (1,0) [0|32] "-"  COO11

BO_ 2399092109 SRRL_RoadBndrySegs_01_SRR2: 64 SRR6TLeftMaster_L_Master
 SG_ SRRL_RoadBndrySegs_E2E_CRC_01 : 0|16@1+ (1,0) [0|65535] "-"  COO11
 SG_ SRRL_RoadBndrySegs_E2E_Cntr_01 : 16|8@1+ (1,0) [0|255] "-"  COO11
 SG_ BatchId_SRRBoundSegs_L_01 : 24|3@1+ (1,0) [0|5] "-"  COO11
 SG_ VertexAge_L_01 : 27|6@1+ (1,0) [0|61] "-"  COO11
 SG_ VertexPosX_L_01 : 33|12@1+ (0.0625,-50) [-50|150] "m"  COO11
 SG_ VertexPosY_L_01 : 45|11@1+ (0.03125,-30) [-30|30] "m"  COO11
 SG_ VertexAge_L_02 : 56|6@1+ (1,0) [0|61] "-"  COO11
 SG_ VertexPosX_L_02 : 62|12@1+ (0.0625,-50) [-50|150] "m"  COO11
 SG_ VertexPosY_L_02 : 74|11@1+ (0.03125,-30) [-30|30] "m"  COO11
 SG_ VertexAge_L_03 : 85|6@1+ (1,0) [0|61] "-"  COO11
 SG_ VertexPosX_L_03 : 91|12@1+ (0.0625,-50) [-50|150] "m"  COO11
 SG_ VertexPosY_L_03 : 103|11@1+ (0.03125,-30) [-30|30] "m"  COO11
 SG_ VertexAge_L_04 : 114|6@1+ (1,0) [0|61] "-"  COO11
 SG_ VertexPosX_L_04 : 120|12@1+ (0.0625,-50) [-50|150] "m"  COO11
 SG_ VertexPosY_L_04 : 132|11@1+ (0.03125,-30) [-30|30] "m"  COO11
 SG_ VertexAge_L_05 : 143|6@1+ (1,0) [0|61] "-"  COO11
 SG_ VertexPosX_L_05 : 149|12@1+ (0.0625,-50) [-50|150] "m"  COO11
 SG_ VertexPosY_L_05 : 161|11@1+ (0.03125,-30) [-30|30] "m"  COO11
 SG_ VertexAge_L_06 : 172|6@1+ (1,0) [0|61] "-"  COO11
 SG_ VertexPosX_L_06 : 178|12@1+ (0.0625,-50) [-50|150] "m"  COO11
 SG_ VertexPosY_L_06 : 190|11@1+ (0.03125,-30) [-30|30] "m"  COO11
 SG_ VertexAge_L_07 : 201|6@1+ (1,0) [0|61] "-"  COO11
 SG_ VertexPosX_L_07 : 207|12@1+ (0.0625,-50) [-50|150] "m"  COO11
 SG_ VertexPosY_L_07 : 219|11@1+ (0.03125,-30) [-30|30] "m"  COO11
 SG_ VertexAge_L_08 : 230|6@1+ (1,0) [0|61] "-"  COO11
 SG_ VertexPosX_L_08 : 236|12@1+ (0.0625,-50) [-50|150] "m"  COO11
 SG_ VertexPosY_L_08 : 248|11@1+ (0.03125,-30) [-30|30] "m"  COO11
 SG_ VertexAge_L_09 : 259|6@1+ (1,0) [0|61] "-"  COO11
 SG_ VertexPosX_L_09 : 265|12@1+ (0.0625,-50) [-50|150] "m"  COO11
 SG_ VertexPosY_L_09 : 277|11@1+ (0.03125,-30) [-30|30] "m"  COO11
 SG_ VertexAge_L_10 : 288|6@1+ (1,0) [0|61] "-"  COO11
 SG_ VertexPosX_L_10 : 294|12@1+ (0.0625,-50) [-50|150] "m"  COO11
 SG_ VertexPosY_L_10 : 306|11@1+ (0.03125,-30) [-30|30] "m"  COO11
 SG_ VertexAge_L_11 : 317|6@1+ (1,0) [0|61] "-"  COO11
 SG_ VertexPosX_L_11 : 323|12@1+ (0.0625,-50) [-50|150] "m"  COO11
 SG_ VertexPosY_L_11 : 335|11@1+ (0.03125,-30) [-30|30] "m"  COO11
 SG_ VertexAge_L_12 : 346|6@1+ (1,0) [0|61] "-"  COO11
 SG_ VertexPosX_L_12 : 352|12@1+ (0.0625,-50) [-50|150] "m"  COO11
 SG_ VertexPosY_L_12 : 364|11@1+ (0.03125,-30) [-30|30] "m"  COO11
 SG_ VertexAge_L_13 : 375|6@1+ (1,0) [0|61] "-"  COO11
 SG_ VertexPosX_L_13 : 381|12@1+ (0.0625,-50) [-50|150] "m"  COO11
 SG_ VertexPosY_L_13 : 393|11@1+ (0.03125,-30) [-30|30] "m"  COO11
 SG_ VertexAge_L_14 : 404|6@1+ (1,0) [0|61] "-"  COO11
 SG_ VertexPosX_L_14 : 410|12@1+ (0.0625,-50) [-50|150] "m"  COO11
 SG_ VertexPosY_L_14 : 422|11@1+ (0.03125,-30) [-30|30] "m"  COO11
 SG_ VertexAge_L_15 : 433|6@1+ (1,0) [0|61] "-"  COO11
 SG_ VertexPosX_L_15 : 439|12@1+ (0.0625,-50) [-50|150] "m"  COO11
 SG_ VertexPosY_L_15 : 451|11@1+ (0.03125,-30) [-30|30] "m"  COO11
 SG_ VertexAge_L_16 : 462|6@1+ (1,0) [0|61] "-"  COO11
 SG_ VertexPosX_L_16 : 468|12@1+ (0.0625,-50) [-50|150] "m"  COO11
 SG_ VertexPosY_L_16 : 480|11@1+ (0.03125,-30) [-30|30] "m"  COO11

BO_ 2399092365 SRRL_RoadBndrySegs_02_SRR2: 64 SRR6TLeftMaster_L_Master
 SG_ SRRL_RoadBndrySegs_E2E_CRC_02 : 0|16@1+ (1,0) [0|65535] "-"  COO11
 SG_ SRRL_RoadBndrySegs_E2E_Cntr_02 : 16|8@1+ (1,0) [0|255] "-"  COO11
 SG_ BatchId_SRRBoundSegs_L_02 : 24|3@1+ (1,0) [0|5] "-"  COO11
 SG_ VertexAge_L_17 : 27|6@1+ (1,0) [0|61] "-"  COO11
 SG_ VertexPosX_L_17 : 33|12@1+ (0.0625,-50) [-50|150] "m"  COO11
 SG_ VertexPosY_L_17 : 45|11@1+ (0.03125,-30) [-30|30] "m"  COO11
 SG_ VertexAge_L_18 : 56|6@1+ (1,0) [0|61] "-"  COO11
 SG_ VertexPosX_L_18 : 62|12@1+ (0.0625,-50) [-50|150] "m"  COO11
 SG_ VertexPosY_L_18 : 74|11@1+ (0.03125,-30) [-30|30] "m"  COO11
 SG_ VertexAge_L_19 : 85|6@1+ (1,0) [0|61] "-"  COO11
 SG_ VertexPosX_L_19 : 91|12@1+ (0.0625,-50) [-50|150] "m"  COO11
 SG_ VertexPosY_L_19 : 103|11@1+ (0.03125,-30) [-30|30] "m"  COO11
 SG_ VertexAge_L_20 : 114|6@1+ (1,0) [0|61] "-"  COO11
 SG_ VertexPosX_L_20 : 120|12@1+ (0.0625,-50) [-50|150] "m"  COO11
 SG_ VertexPosY_L_20 : 132|11@1+ (0.03125,-30) [-30|30] "m"  COO11
 SG_ VertexAge_L_21 : 143|6@1+ (1,0) [0|61] "-"  COO11
 SG_ VertexPosX_L_21 : 149|12@1+ (0.0625,-50) [-50|150] "m"  COO11
 SG_ VertexPosY_L_21 : 161|11@1+ (0.03125,-30) [-30|30] "m"  COO11
 SG_ VertexAge_L_22 : 172|6@1+ (1,0) [0|61] "-"  COO11
 SG_ VertexPosX_L_22 : 178|12@1+ (0.0625,-50) [-50|150] "m"  COO11
 SG_ VertexPosY_L_22 : 190|11@1+ (0.03125,-30) [-30|30] "m"  COO11
 SG_ VertexAge_L_23 : 201|6@1+ (1,0) [0|61] "-"  COO11
 SG_ VertexPosX_L_23 : 207|12@1+ (0.0625,-50) [-50|150] "m"  COO11
 SG_ VertexPosY_L_23 : 219|11@1+ (0.03125,-30) [-30|30] "m"  COO11
 SG_ VertexAge_L_24 : 230|6@1+ (1,0) [0|61] "-"  COO11
 SG_ VertexPosX_L_24 : 236|12@1+ (0.0625,-50) [-50|150] "m"  COO11
 SG_ VertexPosY_L_24 : 248|11@1+ (0.03125,-30) [-30|30] "m"  COO11
 SG_ VertexAge_L_25 : 259|6@1+ (1,0) [0|61] "-"  COO11
 SG_ VertexPosX_L_25 : 265|12@1+ (0.0625,-50) [-50|150] "m"  COO11
 SG_ VertexPosY_L_25 : 277|11@1+ (0.03125,-30) [-30|30] "m"  COO11
 SG_ VertexAge_L_26 : 288|6@1+ (1,0) [0|61] "-"  COO11
 SG_ VertexPosX_L_26 : 294|12@1+ (0.0625,-50) [-50|150] "m"  COO11
 SG_ VertexPosY_L_26 : 306|11@1+ (0.03125,-30) [-30|30] "m"  COO11
 SG_ VertexAge_L_27 : 317|6@1+ (1,0) [0|61] "-"  COO11
 SG_ VertexPosX_L_27 : 323|12@1+ (0.0625,-50) [-50|150] "m"  COO11
 SG_ VertexPosY_L_27 : 335|11@1+ (0.03125,-30) [-30|30] "m"  COO11
 SG_ VertexAge_L_28 : 346|6@1+ (1,0) [0|61] "-"  COO11
 SG_ VertexPosX_L_28 : 352|12@1+ (0.0625,-50) [-50|150] "m"  COO11
 SG_ VertexPosY_L_28 : 364|11@1+ (0.03125,-30) [-30|30] "m"  COO11
 SG_ VertexAge_L_29 : 375|6@1+ (1,0) [0|61] "-"  COO11
 SG_ VertexPosX_L_29 : 381|12@1+ (0.0625,-50) [-50|150] "m"  COO11
 SG_ VertexPosY_L_29 : 393|11@1+ (0.03125,-30) [-30|30] "m"  COO11
 SG_ VertexAge_L_30 : 404|6@1+ (1,0) [0|61] "-"  COO11
 SG_ VertexPosX_L_30 : 410|12@1+ (0.0625,-50) [-50|150] "m"  COO11
 SG_ VertexPosY_L_30 : 422|11@1+ (0.03125,-30) [-30|30] "m"  COO11
 SG_ VertexAge_L_31 : 433|6@1+ (1,0) [0|61] "-"  COO11
 SG_ VertexPosX_L_31 : 439|12@1+ (0.0625,-50) [-50|150] "m"  COO11
 SG_ VertexPosY_L_31 : 451|11@1+ (0.03125,-30) [-30|30] "m"  COO11
 SG_ VertexAge_L_32 : 462|6@1+ (1,0) [0|61] "-"  COO11
 SG_ VertexPosX_L_32 : 468|12@1+ (0.0625,-50) [-50|150] "m"  COO11
 SG_ VertexPosY_L_32 : 480|11@1+ (0.03125,-30) [-30|30] "m"  COO11

BO_ 2399092111 SRRR_RoadBndrySegs_01_SRR2: 64 SRR6TRightMaster_R_Master
 SG_ SRRR_RoadBndrySegs_E2E_CRC_01 : 0|16@1+ (1,0) [0|65535] "-"  COO11
 SG_ SRRR_RoadBndrySegs_E2E_Cntr_01 : 16|8@1+ (1,0) [0|255] "-"  COO11
 SG_ BatchId_SRRBoundSegs_R_01 : 24|3@1+ (1,0) [0|5] "-"  COO11
 SG_ VertexAge_R_01 : 27|6@1+ (1,0) [0|61] "-"  COO11
 SG_ VertexPosX_R_01 : 33|12@1+ (0.0625,-50) [-50|150] "m"  COO11
 SG_ VertexPosY_R_01 : 45|11@1+ (0.03125,-30) [-30|30] "m"  COO11
 SG_ VertexAge_R_02 : 56|6@1+ (1,0) [0|61] "-"  COO11
 SG_ VertexPosX_R_02 : 62|12@1+ (0.0625,-50) [-50|150] "m"  COO11
 SG_ VertexPosY_R_02 : 74|11@1+ (0.03125,-30) [-30|30] "m"  COO11
 SG_ VertexAge_R_03 : 85|6@1+ (1,0) [0|61] "-"  COO11
 SG_ VertexPosX_R_03 : 91|12@1+ (0.0625,-50) [-50|150] "m"  COO11
 SG_ VertexPosY_R_03 : 103|11@1+ (0.03125,-30) [-30|30] "m"  COO11
 SG_ VertexAge_R_04 : 114|6@1+ (1,0) [0|61] "-"  COO11
 SG_ VertexPosX_R_04 : 120|12@1+ (0.0625,-50) [-50|150] "m"  COO11
 SG_ VertexPosY_R_04 : 132|11@1+ (0.03125,-30) [-30|30] "m"  COO11
 SG_ VertexAge_R_05 : 143|6@1+ (1,0) [0|61] "-"  COO11
 SG_ VertexPosX_R_05 : 149|12@1+ (0.0625,-50) [-50|150] "m"  COO11
 SG_ VertexPosY_R_05 : 161|11@1+ (0.03125,-30) [-30|30] "m"  COO11
 SG_ VertexAge_R_06 : 172|6@1+ (1,0) [0|61] "-"  COO11
 SG_ VertexPosX_R_06 : 178|12@1+ (0.0625,-50) [-50|150] "m"  COO11
 SG_ VertexPosY_R_06 : 190|11@1+ (0.03125,-30) [-30|30] "m"  COO11
 SG_ VertexAge_R_07 : 201|6@1+ (1,0) [0|61] "-"  COO11
 SG_ VertexPosX_R_07 : 207|12@1+ (0.0625,-50) [-50|150] "m"  COO11
 SG_ VertexPosY_R_07 : 219|11@1+ (0.03125,-30) [-30|30] "m"  COO11
 SG_ VertexAge_R_08 : 230|6@1+ (1,0) [0|61] "-"  COO11
 SG_ VertexPosX_R_08 : 236|12@1+ (0.0625,-50) [-50|150] "m"  COO11
 SG_ VertexPosY_R_08 : 248|11@1+ (0.03125,-30) [-30|30] "m"  COO11
 SG_ VertexAge_R_09 : 259|6@1+ (1,0) [0|61] "-"  COO11
 SG_ VertexPosX_R_09 : 265|12@1+ (0.0625,-50) [-50|150] "m"  COO11
 SG_ VertexPosY_R_09 : 277|11@1+ (0.03125,-30) [-30|30] "m"  COO11
 SG_ VertexAge_R_10 : 288|6@1+ (1,0) [0|61] "-"  COO11
 SG_ VertexPosX_R_10 : 294|12@1+ (0.0625,-50) [-50|150] "m"  COO11
 SG_ VertexPosY_R_10 : 306|11@1+ (0.03125,-30) [-30|30] "m"  COO11
 SG_ VertexAge_R_11 : 317|6@1+ (1,0) [0|61] "-"  COO11
 SG_ VertexPosX_R_11 : 323|12@1+ (0.0625,-50) [-50|150] "m"  COO11
 SG_ VertexPosY_R_11 : 335|11@1+ (0.03125,-30) [-30|30] "m"  COO11
 SG_ VertexAge_R_12 : 346|6@1+ (1,0) [0|61] "-"  COO11
 SG_ VertexPosX_R_12 : 352|12@1+ (0.0625,-50) [-50|150] "m"  COO11
 SG_ VertexPosY_R_12 : 364|11@1+ (0.03125,-30) [-30|30] "m"  COO11
 SG_ VertexAge_R_13 : 375|6@1+ (1,0) [0|61] "-"  COO11
 SG_ VertexPosX_R_13 : 381|12@1+ (0.0625,-50) [-50|150] "m"  COO11
 SG_ VertexPosY_R_13 : 393|11@1+ (0.03125,-30) [-30|30] "m"  COO11
 SG_ VertexAge_R_14 : 404|6@1+ (1,0) [0|61] "-"  COO11
 SG_ VertexPosX_R_14 : 410|12@1+ (0.0625,-50) [-50|150] "m"  COO11
 SG_ VertexPosY_R_14 : 422|11@1+ (0.03125,-30) [-30|30] "m"  COO11
 SG_ VertexAge_R_15 : 433|6@1+ (1,0) [0|61] "-"  COO11
 SG_ VertexPosX_R_15 : 439|12@1+ (0.0625,-50) [-50|150] "m"  COO11
 SG_ VertexPosY_R_15 : 451|11@1+ (0.03125,-30) [-30|30] "m"  COO11
 SG_ VertexAge_R_16 : 462|6@1+ (1,0) [0|61] "-"  COO11
 SG_ VertexPosX_R_16 : 468|12@1+ (0.0625,-50) [-50|150] "m"  COO11
 SG_ VertexPosY_R_16 : 480|11@1+ (0.03125,-30) [-30|30] "m"  COO11

BO_ 2399092367 SRRR_RoadBndrySegs_02_SRR2: 64 SRR6TRightMaster_R_Master
 SG_ SRRR_RoadBndrySegs_E2E_CRC_02 : 0|16@1+ (1,0) [0|65535] "-"  COO11
 SG_ SRRR_RoadBndrySegs_E2E_Cntr_02 : 16|8@1+ (1,0) [0|255] "-"  COO11
 SG_ BatchId_SRRBoundSegs_R_02 : 24|3@1+ (1,0) [0|5] "-"  COO11
 SG_ VertexAge_R_17 : 27|6@1+ (1,0) [0|61] "-"  COO11
 SG_ VertexPosX_R_17 : 33|12@1+ (0.0625,-50) [-50|150] "m"  COO11
 SG_ VertexPosY_R_17 : 45|11@1+ (0.03125,-30) [-30|30] "m"  COO11
 SG_ VertexAge_R_18 : 56|6@1+ (1,0) [0|61] "-"  COO11
 SG_ VertexPosX_R_18 : 62|12@1+ (0.0625,-50) [-50|150] "m"  COO11
 SG_ VertexPosY_R_18 : 74|11@1+ (0.03125,-30) [-30|30] "m"  COO11
 SG_ VertexAge_R_19 : 85|6@1+ (1,0) [0|61] "-"  COO11
 SG_ VertexPosX_R_19 : 91|12@1+ (0.0625,-50) [-50|150] "m"  COO11
 SG_ VertexPosY_R_19 : 103|11@1+ (0.03125,-30) [-30|30] "m"  COO11
 SG_ VertexAge_R_20 : 114|6@1+ (1,0) [0|61] "-"  COO11
 SG_ VertexPosX_R_20 : 120|12@1+ (0.0625,-50) [-50|150] "m"  COO11
 SG_ VertexPosY_R_20 : 132|11@1+ (0.03125,-30) [-30|30] "m"  COO11
 SG_ VertexAge_R_21 : 143|6@1+ (1,0) [0|61] "-"  COO11
 SG_ VertexPosX_R_21 : 149|12@1+ (0.0625,-50) [-50|150] "m"  COO11
 SG_ VertexPosY_R_21 : 161|11@1+ (0.03125,-30) [-30|30] "m"  COO11
 SG_ VertexAge_R_22 : 172|6@1+ (1,0) [0|61] "-"  COO11
 SG_ VertexPosX_R_22 : 178|12@1+ (0.0625,-50) [-50|150] "m"  COO11
 SG_ VertexPosY_R_22 : 190|11@1+ (0.03125,-30) [-30|30] "m"  COO11
 SG_ VertexAge_R_23 : 201|6@1+ (1,0) [0|61] "-"  COO11
 SG_ VertexPosX_R_23 : 207|12@1+ (0.0625,-50) [-50|150] "m"  COO11
 SG_ VertexPosY_R_23 : 219|11@1+ (0.03125,-30) [-30|30] "m"  COO11
 SG_ VertexAge_R_24 : 230|6@1+ (1,0) [0|61] "-"  COO11
 SG_ VertexPosX_R_24 : 236|12@1+ (0.0625,-50) [-50|150] "m"  COO11
 SG_ VertexPosY_R_24 : 248|11@1+ (0.03125,-30) [-30|30] "m"  COO11
 SG_ VertexAge_R_25 : 259|6@1+ (1,0) [0|61] "-"  COO11
 SG_ VertexPosX_R_25 : 265|12@1+ (0.0625,-50) [-50|150] "m"  COO11
 SG_ VertexPosY_R_25 : 277|11@1+ (0.03125,-30) [-30|30] "m"  COO11
 SG_ VertexAge_R_26 : 288|6@1+ (1,0) [0|61] "-"  COO11
 SG_ VertexPosX_R_26 : 294|12@1+ (0.0625,-50) [-50|150] "m"  COO11
 SG_ VertexPosY_R_26 : 306|11@1+ (0.03125,-30) [-30|30] "m"  COO11
 SG_ VertexAge_R_27 : 317|6@1+ (1,0) [0|61] "-"  COO11
 SG_ VertexPosX_R_27 : 323|12@1+ (0.0625,-50) [-50|150] "m"  COO11
 SG_ VertexPosY_R_27 : 335|11@1+ (0.03125,-30) [-30|30] "m"  COO11
 SG_ VertexAge_R_28 : 346|6@1+ (1,0) [0|61] "-"  COO11
 SG_ VertexPosX_R_28 : 352|12@1+ (0.0625,-50) [-50|150] "m"  COO11
 SG_ VertexPosY_R_28 : 364|11@1+ (0.03125,-30) [-30|30] "m"  COO11
 SG_ VertexAge_R_29 : 375|6@1+ (1,0) [0|61] "-"  COO11
 SG_ VertexPosX_R_29 : 381|12@1+ (0.0625,-50) [-50|150] "m"  COO11
 SG_ VertexPosY_R_29 : 393|11@1+ (0.03125,-30) [-30|30] "m"  COO11
 SG_ VertexAge_R_30 : 404|6@1+ (1,0) [0|61] "-"  COO11
 SG_ VertexPosX_R_30 : 410|12@1+ (0.0625,-50) [-50|150] "m"  COO11
 SG_ VertexPosY_R_30 : 422|11@1+ (0.03125,-30) [-30|30] "m"  COO11
 SG_ VertexAge_R_31 : 433|6@1+ (1,0) [0|61] "-"  COO11
 SG_ VertexPosX_R_31 : 439|12@1+ (0.0625,-50) [-50|150] "m"  COO11
 SG_ VertexPosY_R_31 : 451|11@1+ (0.03125,-30) [-30|30] "m"  COO11
 SG_ VertexAge_R_32 : 462|6@1+ (1,0) [0|61] "-"  COO11
 SG_ VertexPosX_R_32 : 468|12@1+ (0.0625,-50) [-50|150] "m"  COO11
 SG_ VertexPosY_R_32 : 480|11@1+ (0.03125,-30) [-30|30] "m"  COO11

BO_ 2399091855 SRRR_RoadBoundaryHeader_SRR2: 16 SRR6TRightMaster_R_Master
 SG_ SRRR_RoadBoundaryHeader_E2E_CRC : 0|16@1+ (1,0) [0|65535] "-"  COO11
 SG_ SRRR_RoadBoundaryHeader_E2E_Cntr : 16|8@1+ (1,0) [0|255] "-"  COO11
 SG_ BatchId_SRRBoundHdr_R : 24|3@1+ (1,0) [0|5] "-"  COO11
 SG_ NumCountours_R : 27|4@1+ (1,0) [0|6] "-"  COO11
 SG_ CountourId_R_01 : 31|6@1+ (1,0) [0|61] "-"  COO11
 SG_ NumCountourVertices_R_01 : 37|6@1+ (1,0) [0|32] "-"  COO11
 SG_ CountourId_R_02 : 43|6@1+ (1,0) [0|61] "-"  COO11
 SG_ NumCountourVertices_R_02 : 49|6@1+ (1,0) [0|32] "-"  COO11
 SG_ CountourId_R_03 : 55|6@1+ (1,0) [0|61] "-"  COO11
 SG_ NumCountourVertices_R_03 : 61|6@1+ (1,0) [0|32] "-"  COO11
 SG_ CountourId_R_04 : 67|6@1+ (1,0) [0|61] "-"  COO11
 SG_ NumCountourVertices_R_04 : 73|6@1+ (1,0) [0|32] "-"  COO11
 SG_ CountourId_R_05 : 79|6@1+ (1,0) [0|61] "-"  COO11
 SG_ NumCountourVertices_R_05 : 85|6@1+ (1,0) [0|32] "-"  COO11
 SG_ CountourId_R_06 : 91|6@1+ (1,0) [0|61] "-"  COO11
 SG_ NumCountourVertices_R_06 : 97|6@1+ (1,0) [0|32] "-"  COO11

BO_ 2399089037 SRRL_Objects_01_SRR2: 64 SRR6TLeftMaster_L_Master
 SG_ SRRL_Object_E2E_CRC_01 : 0|16@1+ (1,0) [0|65535] "-"  COO11
 SG_ SRRL_Object_E2E_Counter_01 : 16|8@1+ (1,0) [0|255] "-"  COO11
 SG_ BatchId_SRRObj_L_01 : 24|3@1+ (1,0) [0|5] "-"  COO11
 SG_ LonPosition_L_01 : 28|13@1+ (0.0625,-254.9375) [-254.9375|254.9375] "m"  COO11
 SG_ LonPositionStd_L_01 : 41|10@1+ (0.025,0.025) [0.025|20] "m"  COO11
 SG_ LatPosition_L_01 : 51|13@1+ (0.0625,-254.9375) [-254.9375|254.9375] "m"  COO11
 SG_ LatPositionStd_L_01 : 64|10@1+ (0.025,0.025) [0.025|20] "m"  COO11
 SG_ LonGndVel_L_01 : 74|13@1+ (0.0625,-170) [-170|170] "m/s"  COO11
 SG_ LonGndVelStd_L_01 : 87|10@1+ (0.025,0.025) [0.025|14] "m/s"  COO11
 SG_ LatGndVel_L_01 : 97|13@1+ (0.0625,-170) [-170|170] "m/s"  COO11
 SG_ LatGndVelStd_L_01 : 110|10@1+ (0.025,0.025) [0.025|14] "m/s"  COO11
 SG_ ExistenceProbability_L_01 : 120|8@1+ (0.4,0) [0|100] "%"  COO11
 SG_ Width_L_01 : 128|8@1+ (0.1,0) [0|4] "m"  COO11
 SG_ Length_L_01 : 136|10@1+ (0.1,0) [0|60] "m"  COO11
 SG_ HeadingAngle_L_01 : 146|8@1+ (0.02618,-3.1416) [-3.1416|3.1416] "rad"  COO11
 SG_ DynamicProperty_L_01 : 154|3@1+ (1,0) [0|5] "-"  COO11
 SG_ ClassMostProb_L_01 : 157|3@1+ (1,0) [0|5] "-"  COO11
 SG_ ClassMostProbConf_L_01 : 160|8@1+ (0.4,0) [0|100] "%"  COO11
 SG_ ClassSecMostProb_L_01 : 168|3@1+ (1,0) [0|5] "-"  COO11
 SG_ ClassSecMostProbConf_L_01 : 171|8@1+ (0.4,0) [0|100] "%"  COO11
 SG_ MaintenanceState_L_01 : 179|3@1+ (1,0) [0|3] "-"  COO11
 SG_ YawRate_L_01 : 182|16@1+ (0.0001220703125,-3) [-3|3] "rad/s"  COO11
 SG_ Occlusion_L_01 : 198|3@1+ (1,0) [0|3] "-"  COO11
 SG_ TrackingId_L_01 : 201|8@1+ (1,0) [0|250] "-"  COO11
 SG_ ReferencePoint_L_01 : 209|4@1+ (1,0) [0|8] "-"  COO11
 SG_ RadarCrossSection_L_01 : 213|11@1+ (0.1,-100) [-100|100] "dBm²"  COO11
 SG_ AgeSinceCreated_L_01 : 224|10@1+ (0.01,0) [0|10] "s"  COO11
 SG_ LonPosition_L_02 : 268|13@1+ (0.0625,-254.9375) [-254.9375|254.9375] "m"  COO11
 SG_ LonPositionStd_L_02 : 281|10@1+ (0.025,0.025) [0.025|20] "m"  COO11
 SG_ LatPosition_L_02 : 291|13@1+ (0.0625,-254.9375) [-254.9375|254.9375] "m"  COO11
 SG_ LatPositionStd_L_02 : 304|10@1+ (0.025,0.025) [0.025|20] "m"  COO11
 SG_ LonGndVel_L_02 : 314|13@1+ (0.0625,-170) [-170|170] "m/s"  COO11
 SG_ LonGndVelStd_L_02 : 327|10@1+ (0.025,0.025) [0.025|14] "m/s"  COO11
 SG_ LatGndVel_L_02 : 337|13@1+ (0.0625,-170) [-170|170] "m/s"  COO11
 SG_ LatGndVelStd_L_02 : 350|10@1+ (0.025,0.025) [0.025|14] "m/s"  COO11
 SG_ ExistenceProbability_L_02 : 360|8@1+ (0.4,0) [0|100] "%"  COO11
 SG_ Width_L_02 : 368|8@1+ (0.1,0) [0|4] "m"  COO11
 SG_ Length_L_02 : 376|10@1+ (0.1,0) [0|60] "m"  COO11
 SG_ HeadingAngle_L_02 : 386|8@1+ (0.02618,-3.1416) [-3.1416|3.1416] "rad"  COO11
 SG_ DynamicProperty_L_02 : 394|3@1+ (1,0) [0|5] "-"  COO11
 SG_ ClassMostProb_L_02 : 397|3@1+ (1,0) [0|5] "-"  COO11
 SG_ ClassMostProbConf_L_02 : 400|8@1+ (0.4,0) [0|100] "%"  COO11
 SG_ ClassSecMostProb_L_02 : 408|3@1+ (1,0) [0|5] "-"  COO11
 SG_ ClassSecMostProbConf_L_02 : 411|8@1+ (0.4,0) [0|100] "%"  COO11
 SG_ MaintenanceState_L_02 : 419|3@1+ (1,0) [0|3] "-"  COO11
 SG_ YawRate_L_02 : 422|16@1+ (0.0001220703125,-3) [-3|3] "rad/s"  COO11
 SG_ Occlusion_L_02 : 438|3@1+ (1,0) [0|3] "-"  COO11
 SG_ TrackingId_L_02 : 441|8@1+ (1,0) [0|250] "-"  COO11
 SG_ ReferencePoint_L_02 : 449|4@1+ (1,0) [0|8] "-"  COO11
 SG_ RadarCrossSection_L_02 : 453|11@1+ (0.1,-100) [-100|100] "dbm²"  COO11
 SG_ AgeSinceCreated_L_02 : 464|10@1+ (0.01,0) [0|10] "s"  COO11

BO_ 2399089293 SRRL_Objects_02_SRR2: 64 SRR6TLeftMaster_L_Master
 SG_ SRRL_Object_E2E_CRC_02 : 0|16@1+ (1,0) [0|65535] "-"  COO11
 SG_ SRRL_Object_E2E_Counter_02 : 16|8@1+ (1,0) [0|255] "-"  COO11
 SG_ BatchId_SRRObj_L_02 : 24|3@1+ (1,0) [0|5] "-"  COO11
 SG_ LonPosition_L_03 : 28|13@1+ (0.0625,-254.9375) [-254.9375|254.9375] "m"  COO11
 SG_ LonPositionStd_L_03 : 41|10@1+ (0.025,0.025) [0.025|20] "m"  COO11
 SG_ LatPosition_L_03 : 51|13@1+ (0.0625,-254.9375) [-254.9375|254.9375] "m"  COO11
 SG_ LatPositionStd_L_03 : 64|10@1+ (0.025,0.025) [0.025|20] "m"  COO11
 SG_ LonGndVel_L_03 : 74|13@1+ (0.0625,-170) [-170|170] "m/s"  COO11
 SG_ LonGndVelStd_L_03 : 87|10@1+ (0.025,0.025) [0.025|14] "m/s"  COO11
 SG_ LatGndVel_L_03 : 97|13@1+ (0.0625,-170) [-170|170] "m/s"  COO11
 SG_ LatGndVelStd_L_03 : 110|10@1+ (0.025,0.025) [0.025|14] "m/s"  COO11
 SG_ ExistenceProbability_L_03 : 120|8@1+ (0.4,0) [0|100] "%"  COO11
 SG_ Width_L_03 : 128|8@1+ (0.1,0) [0|4] "m"  COO11
 SG_ Length_L_03 : 136|10@1+ (0.1,0) [0|60] "m"  COO11
 SG_ HeadingAngle_L_03 : 146|8@1+ (0.02618,-3.1416) [-3.1416|3.1416] "rad"  COO11
 SG_ DynamicProperty_L_03 : 154|3@1+ (1,0) [0|5] "-"  COO11
 SG_ ClassMostProb_L_03 : 157|3@1+ (1,0) [0|5] "-"  COO11
 SG_ ClassMostProbConf_L_03 : 160|8@1+ (0.4,0) [0|100] "%"  COO11
 SG_ ClassSecMostProb_L_03 : 168|3@1+ (1,0) [0|5] "-"  COO11
 SG_ ClassSecMostProbConf_L_03 : 171|8@1+ (0.4,0) [0|100] "%"  COO11
 SG_ MaintenanceState_L_03 : 179|3@1+ (1,0) [0|3] "-"  COO11
 SG_ YawRate_L_03 : 182|16@1+ (0.0001220703125,-3) [-3|3] "rad/s"  COO11
 SG_ Occlusion_L_03 : 198|3@1+ (1,0) [0|3] "-"  COO11
 SG_ TrackingId_L_03 : 201|8@1+ (1,0) [0|250] "-"  COO11
 SG_ ReferencePoint_L_03 : 209|4@1+ (1,0) [0|8] "-"  COO11
 SG_ RadarCrossSection_L_03 : 213|11@1+ (0.1,-100) [-100|100] "dBm²"  COO11
 SG_ AgeSinceCreated_L_03 : 224|10@1+ (0.01,0) [0|10] "s"  COO11
 SG_ LonPosition_L_04 : 268|13@1+ (0.0625,-254.9375) [-254.9375|254.9375] "m"  COO11
 SG_ LonPositionStd_L_04 : 281|10@1+ (0.025,0.025) [0.025|20] "m"  COO11
 SG_ LatPosition_L_04 : 291|13@1+ (0.0625,-254.9375) [-254.9375|254.9375] "m"  COO11
 SG_ LatPositionStd_L_04 : 304|10@1+ (0.025,0.025) [0.025|20] "m"  COO11
 SG_ LonGndVel_L_04 : 314|13@1+ (0.0625,-170) [-170|170] "m/s"  COO11
 SG_ LonGndVelStd_L_04 : 327|10@1+ (0.025,0.025) [0.025|14] "m/s"  COO11
 SG_ LatGndVel_L_04 : 337|13@1+ (0.0625,-170) [-170|170] "m/s"  COO11
 SG_ LatGndVelStd_L_04 : 350|10@1+ (0.025,0.025) [0.025|14] "m/s"  COO11
 SG_ ExistenceProbability_L_04 : 360|8@1+ (0.4,0) [0|100] "%"  COO11
 SG_ Width_L_04 : 368|8@1+ (0.1,0) [0|4] "m"  COO11
 SG_ Length_L_04 : 376|10@1+ (0.1,0) [0|60] "m"  COO11
 SG_ HeadingAngle_L_04 : 386|8@1+ (0.02618,-3.1416) [-3.1416|3.1416] "rad"  COO11
 SG_ DynamicProperty_L_04 : 394|3@1+ (1,0) [0|5] "-"  COO11
 SG_ ClassMostProb_L_04 : 397|3@1+ (1,0) [0|5] "-"  COO11
 SG_ ClassMostProbConf_L_04 : 400|8@1+ (0.4,0) [0|100] "%"  COO11
 SG_ ClassSecMostProb_L_04 : 408|3@1+ (1,0) [0|5] "-"  COO11
 SG_ ClassSecMostProbConf_L_04 : 411|8@1+ (0.4,0) [0|100] "%"  COO11
 SG_ MaintenanceState_L_04 : 419|3@1+ (1,0) [0|3] "-"  COO11
 SG_ YawRate_L_04 : 422|16@1+ (0.0001220703125,-3) [-3|3] "rad/s"  COO11
 SG_ Occlusion_L_04 : 438|3@1+ (1,0) [0|3] "-"  COO11
 SG_ TrackingId_L_04 : 441|8@1+ (1,0) [0|250] "-"  COO11
 SG_ ReferencePoint_L_04 : 449|4@1+ (1,0) [0|8] "-"  COO11
 SG_ RadarCrossSection_L_04 : 453|11@1+ (0.1,-100) [-100|100] "dbm²"  COO11
 SG_ AgeSinceCreated_L_04 : 464|10@1+ (0.01,0) [0|10] "s"  COO11

BO_ 2399089549 SRRL_Objects_03_SRR2: 64 SRR6TLeftMaster_L_Master
 SG_ SRRL_Object_E2E_CRC_03 : 0|16@1+ (1,0) [0|65535] "-"  COO11
 SG_ SRRL_Object_E2E_Counter_03 : 16|8@1+ (1,0) [0|255] "-"  COO11
 SG_ BatchId_SRRObj_L_03 : 24|3@1+ (1,0) [0|5] "-"  COO11
 SG_ LonPosition_L_05 : 28|13@1+ (0.0625,-254.9375) [-254.9375|254.9375] "m"  COO11
 SG_ LonPositionStd_L_05 : 41|10@1+ (0.025,0.025) [0.025|20] "m"  COO11
 SG_ LatPosition_L_05 : 51|13@1+ (0.0625,-254.9375) [-254.9375|254.9375] "m"  COO11
 SG_ LatPositionStd_L_05 : 64|10@1+ (0.025,0.025) [0.025|20] "m"  COO11
 SG_ LonGndVel_L_05 : 74|13@1+ (0.0625,-170) [-170|170] "m/s"  COO11
 SG_ LonGndVelStd_L_05 : 87|10@1+ (0.025,0.025) [0.025|14] "m/s"  COO11
 SG_ LatGndVel_L_05 : 97|13@1+ (0.0625,-170) [-170|170] "m/s"  COO11
 SG_ LatGndVelStd_L_05 : 110|10@1+ (0.025,0.025) [0.025|14] "m/s"  COO11
 SG_ ExistenceProbability_L_05 : 120|8@1+ (0.4,0) [0|100] "%"  COO11
 SG_ Width_L_05 : 128|8@1+ (0.1,0) [0|4] "m"  COO11
 SG_ Length_L_05 : 136|10@1+ (0.1,0) [0|60] "m"  COO11
 SG_ HeadingAngle_L_05 : 146|8@1+ (0.02618,-3.1416) [-3.1416|3.1416] "rad"  COO11
 SG_ DynamicProperty_L_05 : 154|3@1+ (1,0) [0|5] "-"  COO11
 SG_ ClassMostProb_L_05 : 157|3@1+ (1,0) [0|5] "-"  COO11
 SG_ ClassMostProbConf_L_05 : 160|8@1+ (0.4,0) [0|100] "%"  COO11
 SG_ ClassSecMostProb_L_05 : 168|3@1+ (1,0) [0|5] "-"  COO11
 SG_ ClassSecMostProbConf_L_05 : 171|8@1+ (0.4,0) [0|100] "%"  COO11
 SG_ MaintenanceState_L_05 : 179|3@1+ (1,0) [0|3] "-"  COO11
 SG_ YawRate_L_05 : 182|16@1+ (0.0001220703125,-3) [-3|3] "rad/s"  COO11
 SG_ Occlusion_L_05 : 198|3@1+ (1,0) [0|3] "-"  COO11
 SG_ TrackingId_L_05 : 201|8@1+ (1,0) [0|250] "-"  COO11
 SG_ ReferencePoint_L_05 : 209|4@1+ (1,0) [0|8] "-"  COO11
 SG_ RadarCrossSection_L_05 : 213|11@1+ (0.1,-100) [-100|100] "dBm²"  COO11
 SG_ AgeSinceCreated_L_05 : 224|10@1+ (0.01,0) [0|10] "s"  COO11
 SG_ LonPosition_L_06 : 268|13@1+ (0.0625,-254.9375) [-254.9375|254.9375] "m"  COO11
 SG_ LonPositionStd_L_06 : 281|10@1+ (0.025,0.025) [0.025|20] "m"  COO11
 SG_ LatPosition_L_06 : 291|13@1+ (0.0625,-254.9375) [-254.9375|254.9375] "m"  COO11
 SG_ LatPositionStd_L_06 : 304|10@1+ (0.025,0.025) [0.025|20] "m"  COO11
 SG_ LonGndVel_L_06 : 314|13@1+ (0.0625,-170) [-170|170] "m/s"  COO11
 SG_ LonGndVelStd_L_06 : 327|10@1+ (0.025,0.025) [0.025|14] "m/s"  COO11
 SG_ LatGndVel_L_06 : 337|13@1+ (0.0625,-170) [-170|170] "m/s"  COO11
 SG_ LatGndVelStd_L_06 : 350|10@1+ (0.025,0.025) [0.025|14] "m/s"  COO11
 SG_ ExistenceProbability_L_06 : 360|8@1+ (0.4,0) [0|100] "%"  COO11
 SG_ Width_L_06 : 368|8@1+ (0.1,0) [0|4] "m"  COO11
 SG_ Length_L_06 : 376|10@1+ (0.1,0) [0|60] "m"  COO11
 SG_ HeadingAngle_L_06 : 386|8@1+ (0.02618,-3.1416) [-3.1416|3.1416] "rad"  COO11
 SG_ DynamicProperty_L_06 : 394|3@1+ (1,0) [0|5] "-"  COO11
 SG_ ClassMostProb_L_06 : 397|3@1+ (1,0) [0|5] "-"  COO11
 SG_ ClassMostProbConf_L_06 : 400|8@1+ (0.4,0) [0|100] "%"  COO11
 SG_ ClassSecMostProb_L_06 : 408|3@1+ (1,0) [0|5] "-"  COO11
 SG_ ClassSecMostProbConf_L_06 : 411|8@1+ (0.4,0) [0|100] "%"  COO11
 SG_ MaintenanceState_L_06 : 419|3@1+ (1,0) [0|3] "-"  COO11
 SG_ YawRate_L_06 : 422|16@1+ (0.0001220703125,-3) [-3|3] "rad/s"  COO11
 SG_ Occlusion_L_06 : 438|3@1+ (1,0) [0|3] "-"  COO11
 SG_ TrackingId_L_06 : 441|8@1+ (1,0) [0|250] "-"  COO11
 SG_ ReferencePoint_L_06 : 449|4@1+ (1,0) [0|8] "-"  COO11
 SG_ RadarCrossSection_L_06 : 453|11@1+ (0.1,-100) [-100|100] "dbm²"  COO11
 SG_ AgeSinceCreated_L_06 : 464|10@1+ (0.01,0) [0|10] "s"  COO11

BO_ 2399089805 SRRL_Objects_04_SRR2: 64 SRR6TLeftMaster_L_Master
 SG_ SRRL_Object_E2E_CRC_04 : 0|16@1+ (1,0) [0|65535] "-"  COO11
 SG_ SRRL_Object_E2E_Counter_04 : 16|8@1+ (1,0) [0|255] "-"  COO11
 SG_ BatchId_SRRObj_L_04 : 24|3@1+ (1,0) [0|5] "-"  COO11
 SG_ LonPosition_L_07 : 28|13@1+ (0.0625,-254.9375) [-254.9375|254.9375] "m"  COO11
 SG_ LonPositionStd_L_07 : 41|10@1+ (0.025,0.025) [0.025|20] "m"  COO11
 SG_ LatPosition_L_07 : 51|13@1+ (0.0625,-254.9375) [-254.9375|254.9375] "m"  COO11
 SG_ LatPositionStd_L_07 : 64|10@1+ (0.025,0.025) [0.025|20] "m"  COO11
 SG_ LonGndVel_L_07 : 74|13@1+ (0.0625,-170) [-170|170] "m/s"  COO11
 SG_ LonGndVelStd_L_07 : 87|10@1+ (0.025,0.025) [0.025|14] "m/s"  COO11
 SG_ LatGndVel_L_07 : 97|13@1+ (0.0625,-170) [-170|170] "m/s"  COO11
 SG_ LatGndVelStd_L_07 : 110|10@1+ (0.025,0.025) [0.025|14] "m/s"  COO11
 SG_ ExistenceProbability_L_07 : 120|8@1+ (0.4,0) [0|100] "%"  COO11
 SG_ Width_L_07 : 128|8@1+ (0.1,0) [0|4] "m"  COO11
 SG_ Length_L_07 : 136|10@1+ (0.1,0) [0|60] "m"  COO11
 SG_ HeadingAngle_L_07 : 146|8@1+ (0.02618,-3.1416) [-3.1416|3.1416] "rad"  COO11
 SG_ DynamicProperty_L_07 : 154|3@1+ (1,0) [0|5] "-"  COO11
 SG_ ClassMostProb_L_07 : 157|3@1+ (1,0) [0|5] "-"  COO11
 SG_ ClassMostProbConf_L_07 : 160|8@1+ (0.4,0) [0|100] "%"  COO11
 SG_ ClassSecMostProb_L_07 : 168|3@1+ (1,0) [0|5] "-"  COO11
 SG_ ClassSecMostProbConf_L_07 : 171|8@1+ (0.4,0) [0|100] "%"  COO11
 SG_ MaintenanceState_L_07 : 179|3@1+ (1,0) [0|3] "-"  COO11
 SG_ YawRate_L_07 : 182|16@1+ (0.0001220703125,-3) [-3|3] "rad/s"  COO11
 SG_ Occlusion_L_07 : 198|3@1+ (1,0) [0|3] "-"  COO11
 SG_ TrackingId_L_07 : 201|8@1+ (1,0) [0|250] "-"  COO11
 SG_ ReferencePoint_L_07 : 209|4@1+ (1,0) [0|8] "-"  COO11
 SG_ RadarCrossSection_L_07 : 213|11@1+ (0.1,-100) [-100|100] "dBm²"  COO11
 SG_ AgeSinceCreated_L_07 : 224|10@1+ (0.01,0) [0|10] "s"  COO11
 SG_ LonPosition_L_08 : 268|13@1+ (0.0625,-254.9375) [-254.9375|254.9375] "m"  COO11
 SG_ LonPositionStd_L_08 : 281|10@1+ (0.025,0.025) [0.025|20] "m"  COO11
 SG_ LatPosition_L_08 : 291|13@1+ (0.0625,-254.9375) [-254.9375|254.9375] "m"  COO11
 SG_ LatPositionStd_L_08 : 304|10@1+ (0.025,0.025) [0.025|20] "m"  COO11
 SG_ LonGndVel_L_08 : 314|13@1+ (0.0625,-170) [-170|170] "m/s"  COO11
 SG_ LonGndVelStd_L_08 : 327|10@1+ (0.025,0.025) [0.025|14] "m/s"  COO11
 SG_ LatGndVel_L_08 : 337|13@1+ (0.0625,-170) [-170|170] "m/s"  COO11
 SG_ LatGndVelStd_L_08 : 350|10@1+ (0.025,0.025) [0.025|14] "m/s"  COO11
 SG_ ExistenceProbability_L_08 : 360|8@1+ (0.4,0) [0|100] "%"  COO11
 SG_ Width_L_08 : 368|8@1+ (0.1,0) [0|4] "m"  COO11
 SG_ Length_L_08 : 376|10@1+ (0.1,0) [0|60] "m"  COO11
 SG_ HeadingAngle_L_08 : 386|8@1+ (0.02618,-3.1416) [-3.1416|3.1416] "rad"  COO11
 SG_ DynamicProperty_L_08 : 394|3@1+ (1,0) [0|5] "-"  COO11
 SG_ ClassMostProb_L_08 : 397|3@1+ (1,0) [0|5] "-"  COO11
 SG_ ClassMostProbConf_L_08 : 400|8@1+ (0.4,0) [0|100] "%"  COO11
 SG_ ClassSecMostProb_L_08 : 408|3@1+ (1,0) [0|5] "-"  COO11
 SG_ ClassSecMostProbConf_L_08 : 411|8@1+ (0.4,0) [0|100] "%"  COO11
 SG_ MaintenanceState_L_08 : 419|3@1+ (1,0) [0|3] "-"  COO11
 SG_ YawRate_L_08 : 422|16@1+ (0.0001220703125,-3) [-3|3] "rad/s"  COO11
 SG_ Occlusion_L_08 : 438|3@1+ (1,0) [0|3] "-"  COO11
 SG_ TrackingId_L_08 : 441|8@1+ (1,0) [0|250] "-"  COO11
 SG_ ReferencePoint_L_08 : 449|4@1+ (1,0) [0|8] "-"  COO11
 SG_ RadarCrossSection_L_08 : 453|11@1+ (0.1,-100) [-100|100] "dbm²"  COO11
 SG_ AgeSinceCreated_L_08 : 464|10@1+ (0.01,0) [0|10] "s"  COO11

BO_ 2399090061 SRRL_Objects_05_SRR2: 64 SRR6TLeftMaster_L_Master
 SG_ SRRL_Object_E2E_CRC_05 : 0|16@1+ (1,0) [0|65535] "-"  COO11
 SG_ SRRL_Object_E2E_Counter_05 : 16|8@1+ (1,0) [0|255] "-"  COO11
 SG_ BatchId_SRRObj_L_05 : 24|3@1+ (1,0) [0|5] "-"  COO11
 SG_ LonPosition_L_09 : 28|13@1+ (0.0625,-254.9375) [-254.9375|254.9375] "m"  COO11
 SG_ LonPositionStd_L_09 : 41|10@1+ (0.025,0.025) [0.025|20] "m"  COO11
 SG_ LatPosition_L_09 : 51|13@1+ (0.0625,-254.9375) [-254.9375|254.9375] "m"  COO11
 SG_ LatPositionStd_L_09 : 64|10@1+ (0.025,0.025) [0.025|20] "m"  COO11
 SG_ LonGndVel_L_09 : 74|13@1+ (0.0625,-170) [-170|170] "m/s"  COO11
 SG_ LonGndVelStd_L_09 : 87|10@1+ (0.025,0.025) [0.025|14] "m/s"  COO11
 SG_ LatGndVel_L_09 : 97|13@1+ (0.0625,-170) [-170|170] "m/s"  COO11
 SG_ LatGndVelStd_L_09 : 110|10@1+ (0.025,0.025) [0.025|14] "m/s"  COO11
 SG_ ExistenceProbability_L_09 : 120|8@1+ (0.4,0) [0|100] "%"  COO11
 SG_ Width_L_09 : 128|8@1+ (0.1,0) [0|4] "m"  COO11
 SG_ Length_L_09 : 136|10@1+ (0.1,0) [0|60] "m"  COO11
 SG_ HeadingAngle_L_09 : 146|8@1+ (0.02618,-3.1416) [-3.1416|3.1416] "rad"  COO11
 SG_ DynamicProperty_L_09 : 154|3@1+ (1,0) [0|5] "-"  COO11
 SG_ ClassMostProb_L_09 : 157|3@1+ (1,0) [0|5] "-"  COO11
 SG_ ClassMostProbConf_L_09 : 160|8@1+ (0.4,0) [0|100] "%"  COO11
 SG_ ClassSecMostProb_L_09 : 168|3@1+ (1,0) [0|5] "-"  COO11
 SG_ ClassSecMostProbConf_L_09 : 171|8@1+ (0.4,0) [0|100] "%"  COO11
 SG_ MaintenanceState_L_09 : 179|3@1+ (1,0) [0|3] "-"  COO11
 SG_ YawRate_L_09 : 182|16@1+ (0.0001220703125,-3) [-3|3] "rad/s"  COO11
 SG_ Occlusion_L_09 : 198|3@1+ (1,0) [0|3] "-"  COO11
 SG_ TrackingId_L_09 : 201|8@1+ (1,0) [0|250] "-"  COO11
 SG_ ReferencePoint_L_09 : 209|4@1+ (1,0) [0|8] "-"  COO11
 SG_ RadarCrossSection_L_09 : 213|11@1+ (0.1,-100) [-100|100] "dBm²"  COO11
 SG_ AgeSinceCreated_L_09 : 224|10@1+ (0.01,0) [0|10] "s"  COO11
 SG_ LonPosition_L_10 : 268|13@1+ (0.0625,-254.9375) [-254.9375|254.9375] "m"  COO11
 SG_ LonPositionStd_L_10 : 281|10@1+ (0.025,0.025) [0.025|20] "m"  COO11
 SG_ LatPosition_L_10 : 291|13@1+ (0.0625,-254.9375) [-254.9375|254.9375] "m"  COO11
 SG_ LatPositionStd_L_10 : 304|10@1+ (0.025,0.025) [0.025|20] "m"  COO11
 SG_ LonGndVel_L_10 : 314|13@1+ (0.0625,-170) [-170|170] "m/s"  COO11
 SG_ LonGndVelStd_L_10 : 327|10@1+ (0.025,0.025) [0.025|14] "m/s"  COO11
 SG_ LatGndVel_L_10 : 337|13@1+ (0.0625,-170) [-170|170] "m/s"  COO11
 SG_ LatGndVelStd_L_10 : 350|10@1+ (0.025,0.025) [0.025|14] "m/s"  COO11
 SG_ ExistenceProbability_L_10 : 360|8@1+ (0.4,0) [0|100] "%"  COO11
 SG_ Width_L_10 : 368|8@1+ (0.1,0) [0|4] "m"  COO11
 SG_ Length_L_10 : 376|10@1+ (0.1,0) [0|60] "m"  COO11
 SG_ HeadingAngle_L_10 : 386|8@1+ (0.02618,-3.1416) [-3.1416|3.1416] "rad"  COO11
 SG_ DynamicProperty_L_10 : 394|3@1+ (1,0) [0|5] "-"  COO11
 SG_ ClassMostProb_L_10 : 397|3@1+ (1,0) [0|5] "-"  COO11
 SG_ ClassMostProbConf_L_10 : 400|8@1+ (0.4,0) [0|100] "%"  COO11
 SG_ ClassSecMostProb_L_10 : 408|3@1+ (1,0) [0|5] "-"  COO11
 SG_ ClassSecMostProbConf_L_10 : 411|8@1+ (0.4,0) [0|100] "%"  COO11
 SG_ MaintenanceState_L_10 : 419|3@1+ (1,0) [0|3] "-"  COO11
 SG_ YawRate_L_10 : 422|16@1+ (0.0001220703125,-3) [-3|3] "rad/s"  COO11
 SG_ Occlusion_L_10 : 438|3@1+ (1,0) [0|3] "-"  COO11
 SG_ TrackingId_L_10 : 441|8@1+ (1,0) [0|250] "-"  COO11
 SG_ ReferencePoint_L_10 : 449|4@1+ (1,0) [0|8] "-"  COO11
 SG_ RadarCrossSection_L_10 : 453|11@1+ (0.1,-100) [-100|100] "dbm²"  COO11
 SG_ AgeSinceCreated_L_10 : 464|10@1+ (0.01,0) [0|10] "s"  COO11

BO_ 2399090317 SRRL_Objects_06_SRR2: 64 SRR6TLeftMaster_L_Master
 SG_ SRRL_Object_E2E_CRC_06 : 0|16@1+ (1,0) [0|65535] "-"  COO11
 SG_ SRRL_Object_E2E_Counter_06 : 16|8@1+ (1,0) [0|255] "-"  COO11
 SG_ BatchId_SRRObj_L_06 : 24|3@1+ (1,0) [0|5] "-"  COO11
 SG_ LonPosition_L_11 : 28|13@1+ (0.0625,-254.9375) [-254.9375|254.9375] "m"  COO11
 SG_ LonPositionStd_L_11 : 41|10@1+ (0.025,0.025) [0.025|20] "m"  COO11
 SG_ LatPosition_L_11 : 51|13@1+ (0.0625,-254.9375) [-254.9375|254.9375] "m"  COO11
 SG_ LatPositionStd_L_11 : 64|10@1+ (0.025,0.025) [0.025|20] "m"  COO11
 SG_ LonGndVel_L_11 : 74|13@1+ (0.0625,-170) [-170|170] "m/s"  COO11
 SG_ LonGndVelStd_L_11 : 87|10@1+ (0.025,0.025) [0.025|14] "m/s"  COO11
 SG_ LatGndVel_L_11 : 97|13@1+ (0.0625,-170) [-170|170] "m/s"  COO11
 SG_ LatGndVelStd_L_11 : 110|10@1+ (0.025,0.025) [0.025|14] "m/s"  COO11
 SG_ ExistenceProbability_L_11 : 120|8@1+ (0.4,0) [0|100] "%"  COO11
 SG_ Width_L_11 : 128|8@1+ (0.1,0) [0|4] "m"  COO11
 SG_ Length_L_11 : 136|10@1+ (0.1,0) [0|60] "m"  COO11
 SG_ HeadingAngle_L_11 : 146|8@1+ (0.02618,-3.1416) [-3.1416|3.1416] "rad"  COO11
 SG_ DynamicProperty_L_11 : 154|3@1+ (1,0) [0|5] "-"  COO11
 SG_ ClassMostProb_L_11 : 157|3@1+ (1,0) [0|5] "-"  COO11
 SG_ ClassMostProbConf_L_11 : 160|8@1+ (0.4,0) [0|100] "%"  COO11
 SG_ ClassSecMostProb_L_11 : 168|3@1+ (1,0) [0|5] "-"  COO11
 SG_ ClassSecMostProbConf_L_11 : 171|8@1+ (0.4,0) [0|100] "%"  COO11
 SG_ MaintenanceState_L_11 : 179|3@1+ (1,0) [0|3] "-"  COO11
 SG_ YawRate_L_11 : 182|16@1+ (0.0001220703125,-3) [-3|3] "rad/s"  COO11
 SG_ Occlusion_L_11 : 198|3@1+ (1,0) [0|3] "-"  COO11
 SG_ TrackingId_L_11 : 201|8@1+ (1,0) [0|250] "-"  COO11
 SG_ ReferencePoint_L_11 : 209|4@1+ (1,0) [0|8] "-"  COO11
 SG_ RadarCrossSection_L_11 : 213|11@1+ (0.1,-100) [-100|100] "dBm²"  COO11
 SG_ AgeSinceCreated_L_11 : 224|10@1+ (0.01,0) [0|10] "s"  COO11
 SG_ LonPosition_L_12 : 268|13@1+ (0.0625,-254.9375) [-254.9375|254.9375] "m"  COO11
 SG_ LonPositionStd_L_12 : 281|10@1+ (0.025,0.025) [0.025|20] "m"  COO11
 SG_ LatPosition_L_12 : 291|13@1+ (0.0625,-254.9375) [-254.9375|254.9375] "m"  COO11
 SG_ LatPositionStd_L_12 : 304|10@1+ (0.025,0.025) [0.025|20] "m"  COO11
 SG_ LonGndVel_L_12 : 314|13@1+ (0.0625,-170) [-170|170] "m/s"  COO11
 SG_ LonGndVelStd_L_12 : 327|10@1+ (0.025,0.025) [0.025|14] "m/s"  COO11
 SG_ LatGndVel_L_12 : 337|13@1+ (0.0625,-170) [-170|170] "m/s"  COO11
 SG_ LatGndVelStd_L_12 : 350|10@1+ (0.025,0.025) [0.025|14] "m/s"  COO11
 SG_ ExistenceProbability_L_12 : 360|8@1+ (0.4,0) [0|100] "%"  COO11
 SG_ Width_L_12 : 368|8@1+ (0.1,0) [0|4] "m"  COO11
 SG_ Length_L_12 : 376|10@1+ (0.1,0) [0|60] "m"  COO11
 SG_ HeadingAngle_L_12 : 386|8@1+ (0.02618,-3.1416) [-3.1416|3.1416] "rad"  COO11
 SG_ DynamicProperty_L_12 : 394|3@1+ (1,0) [0|5] "-"  COO11
 SG_ ClassMostProb_L_12 : 397|3@1+ (1,0) [0|5] "-"  COO11
 SG_ ClassMostProbConf_L_12 : 400|8@1+ (0.4,0) [0|100] "%"  COO11
 SG_ ClassSecMostProb_L_12 : 408|3@1+ (1,0) [0|5] "-"  COO11
 SG_ ClassSecMostProbConf_L_12 : 411|8@1+ (0.4,0) [0|100] "%"  COO11
 SG_ MaintenanceState_L_12 : 419|3@1+ (1,0) [0|3] "-"  COO11
 SG_ YawRate_L_12 : 422|16@1+ (0.0001220703125,-3) [-3|3] "rad/s"  COO11
 SG_ Occlusion_L_12 : 438|3@1+ (1,0) [0|3] "-"  COO11
 SG_ TrackingId_L_12 : 441|8@1+ (1,0) [0|250] "-"  COO11
 SG_ ReferencePoint_L_12 : 449|4@1+ (1,0) [0|8] "-"  COO11
 SG_ RadarCrossSection_L_12 : 453|11@1+ (0.1,-100) [-100|100] "dbm²"  COO11
 SG_ AgeSinceCreated_L_12 : 464|10@1+ (0.01,0) [0|10] "s"  COO11

BO_ 2399090573 SRRL_Objects_07_SRR2: 64 SRR6TLeftMaster_L_Master
 SG_ SRRL_Object_E2E_CRC_07 : 0|16@1+ (1,0) [0|65535] "-"  COO11
 SG_ SRRL_Object_E2E_Counter_07 : 16|8@1+ (1,0) [0|255] "-"  COO11
 SG_ BatchId_SRRObj_L_07 : 24|3@1+ (1,0) [0|5] "-"  COO11
 SG_ LonPosition_L_13 : 28|13@1+ (0.0625,-254.9375) [-254.9375|254.9375] "m"  COO11
 SG_ LonPositionStd_L_13 : 41|10@1+ (0.025,0.025) [0.025|20] "m"  COO11
 SG_ LatPosition_L_13 : 51|13@1+ (0.0625,-254.9375) [-254.9375|254.9375] "m"  COO11
 SG_ LatPositionStd_L_13 : 64|10@1+ (0.025,0.025) [0.025|20] "m"  COO11
 SG_ LonGndVel_L_13 : 74|13@1+ (0.0625,-170) [-170|170] "m/s"  COO11
 SG_ LonGndVelStd_L_13 : 87|10@1+ (0.025,0.025) [0.025|14] "m/s"  COO11
 SG_ LatGndVel_L_13 : 97|13@1+ (0.0625,-170) [-170|170] "m/s"  COO11
 SG_ LatGndVelStd_L_13 : 110|10@1+ (0.025,0.025) [0.025|14] "m/s"  COO11
 SG_ ExistenceProbability_L_13 : 120|8@1+ (0.4,0) [0|100] "%"  COO11
 SG_ Width_L_13 : 128|8@1+ (0.1,0) [0|4] "m"  COO11
 SG_ Length_L_13 : 136|10@1+ (0.1,0) [0|60] "m"  COO11
 SG_ HeadingAngle_L_13 : 146|8@1+ (0.02618,-3.1416) [-3.1416|3.1416] "rad"  COO11
 SG_ DynamicProperty_L_13 : 154|3@1+ (1,0) [0|5] "-"  COO11
 SG_ ClassMostProb_L_13 : 157|3@1+ (1,0) [0|5] "-"  COO11
 SG_ ClassMostProbConf_L_13 : 160|8@1+ (0.4,0) [0|100] "%"  COO11
 SG_ ClassSecMostProb_L_13 : 168|3@1+ (1,0) [0|5] "-"  COO11
 SG_ ClassSecMostProbConf_L_13 : 171|8@1+ (0.4,0) [0|100] "%"  COO11
 SG_ MaintenanceState_L_13 : 179|3@1+ (1,0) [0|3] "-"  COO11
 SG_ YawRate_L_13 : 182|16@1+ (0.0001220703125,-3) [-3|3] "rad/s"  COO11
 SG_ Occlusion_L_13 : 198|3@1+ (1,0) [0|3] "-"  COO11
 SG_ TrackingId_L_13 : 201|8@1+ (1,0) [0|250] "-"  COO11
 SG_ ReferencePoint_L_13 : 209|4@1+ (1,0) [0|8] "-"  COO11
 SG_ RadarCrossSection_L_13 : 213|11@1+ (0.1,-100) [-100|100] "dBm²"  COO11
 SG_ AgeSinceCreated_L_13 : 224|10@1+ (0.01,0) [0|10] "s"  COO11
 SG_ LonPosition_L_14 : 268|13@1+ (0.0625,-254.9375) [-254.9375|254.9375] "m"  COO11
 SG_ LonPositionStd_L_14 : 281|10@1+ (0.025,0.025) [0.025|20] "m"  COO11
 SG_ LatPosition_L_14 : 291|13@1+ (0.0625,-254.9375) [-254.9375|254.9375] "m"  COO11
 SG_ LatPositionStd_L_14 : 304|10@1+ (0.025,0.025) [0.025|20] "m"  COO11
 SG_ LonGndVel_L_14 : 314|13@1+ (0.0625,-170) [-170|170] "m/s"  COO11
 SG_ LonGndVelStd_L_14 : 327|10@1+ (0.025,0.025) [0.025|14] "m/s"  COO11
 SG_ LatGndVel_L_14 : 337|13@1+ (0.0625,-170) [-170|170] "m/s"  COO11
 SG_ LatGndVelStd_L_14 : 350|10@1+ (0.025,0.025) [0.025|14] "m/s"  COO11
 SG_ ExistenceProbability_L_14 : 360|8@1+ (0.4,0) [0|100] "%"  COO11
 SG_ Width_L_14 : 368|8@1+ (0.1,0) [0|4] "m"  COO11
 SG_ Length_L_14 : 376|10@1+ (0.1,0) [0|60] "m"  COO11
 SG_ HeadingAngle_L_14 : 386|8@1+ (0.02618,-3.1416) [-3.1416|3.1416] "rad"  COO11
 SG_ DynamicProperty_L_14 : 394|3@1+ (1,0) [0|5] "-"  COO11
 SG_ ClassMostProb_L_14 : 397|3@1+ (1,0) [0|5] "-"  COO11
 SG_ ClassMostProbConf_L_14 : 400|8@1+ (0.4,0) [0|100] "%"  COO11
 SG_ ClassSecMostProb_L_14 : 408|3@1+ (1,0) [0|5] "-"  COO11
 SG_ ClassSecMostProbConf_L_14 : 411|8@1+ (0.4,0) [0|100] "%"  COO11
 SG_ MaintenanceState_L_14 : 419|3@1+ (1,0) [0|3] "-"  COO11
 SG_ YawRate_L_14 : 422|16@1+ (0.0001220703125,-3) [-3|3] "rad/s"  COO11
 SG_ Occlusion_L_14 : 438|3@1+ (1,0) [0|3] "-"  COO11
 SG_ TrackingId_L_14 : 441|8@1+ (1,0) [0|250] "-"  COO11
 SG_ ReferencePoint_L_14 : 449|4@1+ (1,0) [0|8] "-"  COO11
 SG_ RadarCrossSection_L_14 : 453|11@1+ (0.1,-100) [-100|100] "dbm²"  COO11
 SG_ AgeSinceCreated_L_14 : 464|10@1+ (0.01,0) [0|10] "s"  COO11

BO_ 2399090829 SRRL_Objects_08_SRR2: 64 SRR6TLeftMaster_L_Master
 SG_ SRRL_Object_E2E_CRC_08 : 0|16@1+ (1,0) [0|65535] "-"  COO11
 SG_ SRRL_Object_E2E_Counter_08 : 16|8@1+ (1,0) [0|255] "-"  COO11
 SG_ BatchId_SRRObj_L_08 : 24|3@1+ (1,0) [0|5] "-"  COO11
 SG_ LonPosition_L_15 : 28|13@1+ (0.0625,-254.9375) [-254.9375|254.9375] "m"  COO11
 SG_ LonPositionStd_L_15 : 41|10@1+ (0.025,0.025) [0.025|20] "m"  COO11
 SG_ LatPosition_L_15 : 51|13@1+ (0.0625,-254.9375) [-254.9375|254.9375] "m"  COO11
 SG_ LatPositionStd_L_15 : 64|10@1+ (0.025,0.025) [0.025|20] "m"  COO11
 SG_ LonGndVel_L_15 : 74|13@1+ (0.0625,-170) [-170|170] "m/s"  COO11
 SG_ LonGndVelStd_L_15 : 87|10@1+ (0.025,0.025) [0.025|14] "m/s"  COO11
 SG_ LatGndVel_L_15 : 97|13@1+ (0.0625,-170) [-170|170] "m/s"  COO11
 SG_ LatGndVelStd_L_15 : 110|10@1+ (0.025,0.025) [0.025|14] "m/s"  COO11
 SG_ ExistenceProbability_L_15 : 120|8@1+ (0.4,0) [0|100] "%"  COO11
 SG_ Width_L_15 : 128|8@1+ (0.1,0) [0|4] "m"  COO11
 SG_ Length_L_15 : 136|10@1+ (0.1,0) [0|60] "m"  COO11
 SG_ HeadingAngle_L_15 : 146|8@1+ (0.02618,-3.1416) [-3.1416|3.1416] "rad"  COO11
 SG_ DynamicProperty_L_15 : 154|3@1+ (1,0) [0|5] "-"  COO11
 SG_ ClassMostProb_L_15 : 157|3@1+ (1,0) [0|5] "-"  COO11
 SG_ ClassMostProbConf_L_15 : 160|8@1+ (0.4,0) [0|100] "%"  COO11
 SG_ ClassSecMostProb_L_15 : 168|3@1+ (1,0) [0|5] "-"  COO11
 SG_ ClassSecMostProbConf_L_15 : 171|8@1+ (0.4,0) [0|100] "%"  COO11
 SG_ MaintenanceState_L_15 : 179|3@1+ (1,0) [0|3] "-"  COO11
 SG_ YawRate_L_15 : 182|16@1+ (0.0001220703125,-3) [-3|3] "rad/s"  COO11
 SG_ Occlusion_L_15 : 198|3@1+ (1,0) [0|3] "-"  COO11
 SG_ TrackingId_L_15 : 201|8@1+ (1,0) [0|250] "-"  COO11
 SG_ ReferencePoint_L_15 : 209|4@1+ (1,0) [0|8] "-"  COO11
 SG_ RadarCrossSection_L_15 : 213|11@1+ (0.1,-100) [-100|100] "dBm²"  COO11
 SG_ AgeSinceCreated_L_15 : 224|10@1+ (0.01,0) [0|10] "s"  COO11
 SG_ LonPosition_L_16 : 268|13@1+ (0.0625,-254.9375) [-254.9375|254.9375] "m"  COO11
 SG_ LonPositionStd_L_16 : 281|10@1+ (0.025,0.025) [0.025|20] "m"  COO11
 SG_ LatPosition_L_16 : 291|13@1+ (0.0625,-254.9375) [-254.9375|254.9375] "m"  COO11
 SG_ LatPositionStd_L_16 : 304|10@1+ (0.025,0.025) [0.025|20] "m"  COO11
 SG_ LonGndVel_L_16 : 314|13@1+ (0.0625,-170) [-170|170] "m/s"  COO11
 SG_ LonGndVelStd_L_16 : 327|10@1+ (0.025,0.025) [0.025|14] "m/s"  COO11
 SG_ LatGndVel_L_16 : 337|13@1+ (0.0625,-170) [-170|170] "m/s"  COO11
 SG_ LatGndVelStd_L_16 : 350|10@1+ (0.025,0.025) [0.025|14] "m/s"  COO11
 SG_ ExistenceProbability_L_16 : 360|8@1+ (0.4,0) [0|100] "%"  COO11
 SG_ Width_L_16 : 368|8@1+ (0.1,0) [0|4] "m"  COO11
 SG_ Length_L_16 : 376|10@1+ (0.1,0) [0|60] "m"  COO11
 SG_ HeadingAngle_L_16 : 386|8@1+ (0.02618,-3.1416) [-3.1416|3.1416] "rad"  COO11
 SG_ DynamicProperty_L_16 : 394|3@1+ (1,0) [0|5] "-"  COO11
 SG_ ClassMostProb_L_16 : 397|3@1+ (1,0) [0|5] "-"  COO11
 SG_ ClassMostProbConf_L_16 : 400|8@1+ (0.4,0) [0|100] "%"  COO11
 SG_ ClassSecMostProb_L_16 : 408|3@1+ (1,0) [0|5] "-"  COO11
 SG_ ClassSecMostProbConf_L_16 : 411|8@1+ (0.4,0) [0|100] "%"  COO11
 SG_ MaintenanceState_L_16 : 419|3@1+ (1,0) [0|3] "-"  COO11
 SG_ YawRate_L_16 : 422|16@1+ (0.0001220703125,-3) [-3|3] "rad/s"  COO11
 SG_ Occlusion_L_16 : 438|3@1+ (1,0) [0|3] "-"  COO11
 SG_ TrackingId_L_16 : 441|8@1+ (1,0) [0|250] "-"  COO11
 SG_ ReferencePoint_L_16 : 449|4@1+ (1,0) [0|8] "-"  COO11
 SG_ RadarCrossSection_L_16 : 453|11@1+ (0.1,-100) [-100|100] "dbm²"  COO11
 SG_ AgeSinceCreated_L_16 : 464|10@1+ (0.01,0) [0|10] "s"  COO11

CM_ BO_ 3221225472 "This is a message for not used signals, created by Vector CANdb++ DBC OLE DB Provider.";
CM_ SG_ 3221225472 UDS_BASIS "base signals for UDS";
CM_ SG_ 2564485773 UDS_BASIS "base signals for UDS";
CM_ SG_ 2564485775 UDS_BASIS "base signals for UDS";
CM_ BO_ 2566834829 "DM1 version 4 according to SAE J 1939-73.  -> see also SAE J 1939-21.";
CM_ SG_ 2566834829 DM1_placeholder_BASE "DM1 - SAE J 1939: DM1 version 4 according to SAE J 1939-73. -> see also SAE J 1939-21.";
CM_ BO_ 2566834831 "DM1 version 4 according to SAE J 1939-73.  -> see also SAE J 1939-21.";
CM_ SG_ 2566834831 DM1_placeholder_BASE "DM1 - SAE J 1939: DM1 version 4 according to SAE J 1939-73. -> see also SAE J 1939-21.";
CM_ SG_ 2566834828 DM1_placeholder_BASE "DM1 - SAE J 1939: DM1 version 4 according to SAE J 1939-73. -> see also SAE J 1939-21.";
CM_ SG_ 2566834830 DM1_placeholder_BASE "DM1 - SAE J 1939: DM1 version 4 according to SAE J 1939-73. -> see also SAE J 1939-21.";
CM_ SG_ 2564485262 UDS_BASIS "base signals for UDS";
CM_ SG_ 2564485374 UDS_BASIS "base signals for UDS";
CM_ SG_ 2564485260 UDS_BASIS "base signals for UDS";
CM_ SG_ 2564485263 UDS_BASIS "base signals for UDS";
CM_ SG_ 2564485261 UDS_BASIS "base signals for UDS";
CM_ SG_ 2564485518 UDS_BASIS "base signals for UDS";
CM_ SG_ 2564485630 UDS_BASIS "base signals for UDS";
CM_ SG_ 2564485519 UDS_BASIS "base signals for UDS";
CM_ SG_ 2564485517 UDS_BASIS "base signals for UDS";
CM_ SG_ 2564485516 UDS_BASIS "base signals for UDS";
CM_ SG_ 2564460273 UDS_BASIS "base signals for UDS";
CM_ SG_ 2564471025 UDS_BASIS "base signals for UDS";
CM_ SG_ 2564460017 UDS_BASIS "base signals for UDS";
CM_ SG_ 2564460529 UDS_BASIS "base signals for UDS";
CM_ SG_ 2564459761 UDS_BASIS "base signals for UDS";
CM_ SG_ 2564460016 UDS_BASIS "base signals for UDS";
CM_ SG_ 2564460272 UDS_BASIS "base signals for UDS";
CM_ SG_ 2564460528 UDS_BASIS "base signals for UDS";
CM_ SG_ 2564488944 UDS_BASIS "base signals for UDS";
CM_ SG_ 2564459760 UDS_BASIS "base signals for UDS";
CM_ BO_ 2564554736 "UDS req FCN";
CM_ SG_ 2564554736 UDS_FCNF0_TO_ALL "Base signals for UDS";
CM_ BO_ 2566871591 "Proprietary CAN message diagVehState which provides relevant information about the vehicle needed for diagnostic purposes.  Remark for checksum:  Checksum = (Byte1 + Byte2 + Byte3 + Byte5 + Byte6 + Byte7 + Byte8 + (message counter & 0x0F) + message ID low";
CM_ SG_ 2566871591 diagCondVehSpd_BASE "vehicle condition for diagnosis: vehicle is standing still";
CM_ SG_ 2566871591 drvSysActv_BASE "The signal describes whether the drive system is ready for operation.";
CM_ SG_ 2566871591 clamp15netw_BASE "CAN signal to communicate the state of clamp 15";
CM_ SG_ 2566871591 diagCondHighVoltage_BASE "vehicle condition for diagnosis: high voltage isolated";
CM_ SG_ 2566871591 diagCondEngSpd_BASE "vehicle condition for diagnosis: engine is stopped";
CM_ SG_ 2566871591 E2EmsgCounterDiagVehState_BASE "The message counter is used to detect situations where the transmitting ECU malfunction repeats the same frame all the time. range 0 to 15 , then 0";
CM_ SG_ 2566871591 E2EmsgChckSumDiagVehState_BASE "The message checksum is used to verify the signal path from the transmitting device to the receiving device. range 0 to 15";
CM_ SG_ 2566871591 highResolutionTotalVehDistance_B "Accumulated distance traveled by the vehicle during its operation.";
CM_ SG_ 2566871591 diagCondGearNeutral_BASE "vehicle condition for diagnosis: gearbox in neutral gear";
CM_ SG_ 2566871591 diagCondParkingBrake_BASE "vehicle condition for diagnosis: parking brake is engaged";
CM_ SG_ 2566871591 diagCondC1_BASE "vehicle condition for diagnosis: UDS C1- condition";
CM_ BO_ 2566842094 "Time/Date
Error bit : 
TRUE  : 0x00000001
FALSE : 0x00000000";
CM_ SG_ 2566842094 seconds_BASIS "The seconds component of the current time of day.";
CM_ SG_ 2566842094 hours_BASIS "The hour component of the current time of day.";
CM_ SG_ 2566842094 month_BASIS "The month component of the current calendar date.";
CM_ SG_ 2566842094 day_BASIS "The day component of the current calendar date.";
CM_ SG_ 2566842094 year_BASIS "The year component of the current calendar date.";
CM_ SG_ 2566842094 localMinuteOffset_BASIS "The minute component of the offset between the UTC time and date and a local time zone time and date.";
CM_ SG_ 2566842094 localHourOffset_BASIS "The hour component of the offset between the UTC (Universal Time Coordinate) time and date and a local time zone time and date.";
CM_ SG_ 2566842094 minutes_BASIS "The minutes component of the current time of day.";
CM_ BO_ 2566566695 "CanTSyn (Type = SYNC)	120 216 202 12 74 34 104 243 196 126 213 207 58 14 27 94
CanTSyn (Type = FUP)	232 64 96 222 194 172 227 164 61 136 209 238 81 22 173 73";
CM_ SG_ 2566566695 Type "The Multiplexer is located at Byte 0, named as ¿Type¿.";
CM_ SG_ 2566566695 CRC_Sync "CRC of Sync message";
CM_ SG_ 2566566695 CRC_Fup "CRC of Follow Up message";
CM_ SG_ 2566566695 SequenceCounter_Sync "SC = Sequence Counter (Bit 3 to Bit 0) for Sync  message";
CM_ SG_ 2566566695 SequenceCounter_Fup "SC = Sequence Counter (Bit 3 to Bit 0) for Follow Up message";
CM_ SG_ 2566566695 TimeDomain_Sync "D = Time Domain 0 to 15 (Bit 7 to Bit 4)";
CM_ SG_ 2566566695 TimeDomain_Fup "D = Time Domain 0 to 15 (Bit 7 to Bit 4)";
CM_ SG_ 2566566695 UserByte0_Sync "User Byte 0, default: 0";
CM_ SG_ 2566566695 OVS_Fup "Overflow of seconds (Bit 1 to Bit 0)";
CM_ SG_ 2566566695 SGW_Fup "SGW (Bit 2) -> SyncToGTM = 0, SyncToSubDomain = 1";
CM_ SG_ 2566566695 Reserved_Fup "reserved (Bit 7 to Bit 3), default: 0";
CM_ SG_ 2566566695 SyncTimeSec_Sync "SyncTimeSec = 32 bit LSB of the 48 bits seconds part of the time";
CM_ SG_ 2566566695 SyncTimeNSec_Fup "SyncTimeNSec = 32 Bit time value in nanoseconds";
CM_ SG_ 2399091597 SlaveDetTimestampNanosec_L "Error bit : 
TRUE  : 0x00000001
FALSE : 0x00000000";
CM_ SG_ 2399091597 MasterDetTimestampNanosec_L "Error bit : 
TRUE  : 0x00000001
FALSE : 0x00000000";
CM_ SG_ 2399091597 ErrorBits_L "Error bit :�


TRUE� : 0x00000001


FALSE : 0x00000000";
CM_ SG_ 2399091597 ObjectTimestampNanoseconds_L "Error bit : 
TRUE  : 0x00000001
FALSE : 0x00000000";
CM_ SG_ 2399091597 CanTSynState_L "Current state of time synchronization to global time master for left side radar";
CM_ SG_ 2399091599 SlaveDetTimestampNanosec_R "Error bit : 
TRUE  : 0x00000001
FALSE : 0x00000000";
CM_ SG_ 2399091599 MasterDetTimestampNanosec_R "Error bit : 
TRUE  : 0x00000001
FALSE : 0x00000000";
CM_ SG_ 2399091599 ErrorBits_R "�
Error bit :�
 

TRUE� : 0x00000001


FALSE : 0x00000000";
CM_ SG_ 2399091599 ObjectTimestampNanoseconds_R "Error bit : 
TRUE  : 0x00000001
FALSE : 0x00000000";
CM_ SG_ 2399091599 CanTSynState_R "Current state of time synchronization to global time master for right side radar";
BA_DEF_  "BusType" STRING ;
BA_DEF_ BO_  "N_Ar" INT 0 0;
BA_DEF_ BO_  "DiagFdOnly" ENUM  "No","Yes";
BA_DEF_ BO_  "DiagConnection" INT 0 0;
BA_DEF_ BO_  "DiagResponse" ENUM  "No","Yes";
BA_DEF_ BO_  "DiagRequest" ENUM  "No","Yes";
BA_DEF_ BO_  "DiagState" ENUM  "No","Yes";
BA_DEF_ BO_  "GenMsgILSupport" ENUM  "No","Yes","vector_leerstring";
BA_DEF_ BO_  "GenMsgSendType" ENUM  "cyclic","reserved","cyclicIfActive","reserved","reserved","reserved","reserved","reserved","noMsgSendType","vector_leerstring";
BA_DEF_ BO_  "GenMsgCycleTime" INT 0 3600000;
BA_DEF_ BO_  "GenMsgStartDelayTime" INT 0 0;
BA_DEF_ BO_  "VFrameFormat" ENUM  "StandardCAN","ExtendedCAN","reserved","reserved","reserved","reserved","reserved","reserved","reserved","reserved","reserved","reserved","reserved","reserved","StandardCAN_FD","ExtendedCAN_FD";
BA_DEF_ BO_  "E2EProfile" STRING ;
BA_DEF_ BO_  "E2EDataLength" INT 0 512;
BA_DEF_ BO_  "E2EDataId" INT 0 0;
BA_DEF_ SG_  "SystemSignalLongSymbol" STRING ;
BA_DEF_DEF_  "BusType" "";
BA_DEF_DEF_  "N_Ar" 1000;
BA_DEF_DEF_  "DiagFdOnly" "Yes";
BA_DEF_DEF_  "DiagConnection" 0;
BA_DEF_DEF_  "DiagResponse" "No";
BA_DEF_DEF_  "DiagRequest" "No";
BA_DEF_DEF_  "DiagState" "No";
BA_DEF_DEF_  "GenMsgILSupport" "Yes";
BA_DEF_DEF_  "GenMsgSendType" "noMsgSendType";
BA_DEF_DEF_  "GenMsgCycleTime" 1000;
BA_DEF_DEF_  "GenMsgStartDelayTime" 0;
BA_DEF_DEF_  "VFrameFormat" "";
BA_DEF_DEF_  "E2EProfile" "";
BA_DEF_DEF_  "E2EDataLength" 0;
BA_DEF_DEF_  "E2EDataId" 0;
BA_DEF_DEF_  "SystemSignalLongSymbol" "";
BA_ "BusType" "CAN";
BA_ "VFrameFormat" BO_ 2631566074 1;
BA_ "GenMsgCycleTime" BO_ 2631566074 0;
BA_ "VFrameFormat" BO_ 2564460274 1;
BA_ "GenMsgCycleTime" BO_ 2564460274 0;
BA_ "VFrameFormat" BO_ 2564485773 1;
BA_ "GenMsgCycleTime" BO_ 2564485773 0;
BA_ "VFrameFormat" BO_ 2631596677 1;
BA_ "GenMsgCycleTime" BO_ 2631596677 0;
BA_ "GenMsgCycleTime" BO_ 2564485774 0;
BA_ "VFrameFormat" BO_ 2564485774 1;
BA_ "GenMsgCycleTime" BO_ 2631596674 0;
BA_ "VFrameFormat" BO_ 2631596674 1;
BA_ "VFrameFormat" BO_ 2564460530 1;
BA_ "GenMsgCycleTime" BO_ 2564460530 0;
BA_ "GenMsgCycleTime" BO_ 2564459762 0;
BA_ "VFrameFormat" BO_ 2564459762 1;
BA_ "VFrameFormat" BO_ 2565603215 1;
BA_ "VFrameFormat" BO_ 2565603214 1;
BA_ "VFrameFormat" BO_ 2564460018 1;
BA_ "GenMsgCycleTime" BO_ 2564460018 0;
BA_ "VFrameFormat" BO_ 2631663610 1;
BA_ "GenMsgCycleTime" BO_ 2631663610 0;
BA_ "GenMsgCycleTime" BO_ 2564554737 0;
BA_ "VFrameFormat" BO_ 2564554737 1;
BA_ "VFrameFormat" BO_ 2631566842 1;
BA_ "GenMsgCycleTime" BO_ 2631566842 0;
BA_ "VFrameFormat" BO_ 2631566330 1;
BA_ "GenMsgCycleTime" BO_ 2631566330 0;
BA_ "GenMsgCycleTime" BO_ 2631566586 0;
BA_ "VFrameFormat" BO_ 2631566586 1;
BA_ "VFrameFormat" BO_ 2631596675 1;
BA_ "GenMsgCycleTime" BO_ 2631596675 0;
BA_ "VFrameFormat" BO_ 2564485772 1;
BA_ "GenMsgCycleTime" BO_ 2564485772 0;
BA_ "VFrameFormat" BO_ 2631596676 1;
BA_ "GenMsgCycleTime" BO_ 2631596676 0;
BA_ "VFrameFormat" BO_ 2565668751 1;
BA_ "GenMsgCycleTime" BO_ 2565668751 0;
BA_ "VFrameFormat" BO_ 2565668750 1;
BA_ "VFrameFormat" BO_ 2565603213 1;
BA_ "VFrameFormat" BO_ 2565603212 1;
BA_ "VFrameFormat" BO_ 2565668748 1;
BA_ "VFrameFormat" BO_ 2565668749 1;
BA_ "GenMsgCycleTime" BO_ 2564485775 0;
BA_ "VFrameFormat" BO_ 2564485775 1;
BA_ "VFrameFormat" BO_ 2566834829 3;
BA_ "VFrameFormat" BO_ 2566834831 3;
BA_ "VFrameFormat" BO_ 2566834828 3;
BA_ "VFrameFormat" BO_ 2566834830 3;
BA_ "GenMsgCycleTime" BO_ 2564485262 0;
BA_ "VFrameFormat" BO_ 2564485262 3;
BA_ "DiagConnection" BO_ 2564485374 62;
BA_ "DiagResponse" BO_ 2564485374 1;
BA_ "GenMsgILSupport" BO_ 2564485374 0;
BA_ "GenMsgCycleTime" BO_ 2564485374 0;
BA_ "VFrameFormat" BO_ 2564485374 3;
BA_ "GenMsgCycleTime" BO_ 2564485260 0;
BA_ "VFrameFormat" BO_ 2564485260 3;
BA_ "GenMsgCycleTime" BO_ 2564485263 0;
BA_ "VFrameFormat" BO_ 2564485263 3;
BA_ "GenMsgCycleTime" BO_ 2564485261 0;
BA_ "VFrameFormat" BO_ 2564485261 3;
BA_ "GenMsgCycleTime" BO_ 2564485518 0;
BA_ "VFrameFormat" BO_ 2564485518 3;
BA_ "DiagConnection" BO_ 2564485630 60;
BA_ "DiagResponse" BO_ 2564485630 1;
BA_ "GenMsgCycleTime" BO_ 2564485630 0;
BA_ "VFrameFormat" BO_ 2564485630 3;
BA_ "GenMsgCycleTime" BO_ 2564485519 0;
BA_ "VFrameFormat" BO_ 2564485519 3;
BA_ "GenMsgCycleTime" BO_ 2564485517 0;
BA_ "VFrameFormat" BO_ 2564485517 3;
BA_ "GenMsgCycleTime" BO_ 2564485516 0;
BA_ "VFrameFormat" BO_ 2564485516 3;
BA_ "GenMsgCycleTime" BO_ 2564460273 0;
BA_ "VFrameFormat" BO_ 2564460273 1;
BA_ "DiagConnection" BO_ 2564471025 60;
BA_ "DiagState" BO_ 2564471025 1;
BA_ "GenMsgCycleTime" BO_ 2564471025 0;
BA_ "VFrameFormat" BO_ 2564471025 1;
BA_ "GenMsgCycleTime" BO_ 2564460017 0;
BA_ "VFrameFormat" BO_ 2564460017 1;
BA_ "GenMsgCycleTime" BO_ 2564460529 0;
BA_ "VFrameFormat" BO_ 2564460529 1;
BA_ "GenMsgCycleTime" BO_ 2564459761 0;
BA_ "VFrameFormat" BO_ 2564459761 1;
BA_ "GenMsgCycleTime" BO_ 2564460016 0;
BA_ "VFrameFormat" BO_ 2564460016 3;
BA_ "GenMsgCycleTime" BO_ 2564460272 0;
BA_ "VFrameFormat" BO_ 2564460272 3;
BA_ "GenMsgCycleTime" BO_ 2564460528 0;
BA_ "VFrameFormat" BO_ 2564460528 3;
BA_ "DiagConnection" BO_ 2564488944 62;
BA_ "DiagState" BO_ 2564488944 1;
BA_ "GenMsgILSupport" BO_ 2564488944 0;
BA_ "GenMsgCycleTime" BO_ 2564488944 0;
BA_ "VFrameFormat" BO_ 2564488944 3;
BA_ "GenMsgCycleTime" BO_ 2564459760 0;
BA_ "VFrameFormat" BO_ 2564459760 3;
BA_ "GenMsgCycleTime" BO_ 2564554736 0;
BA_ "VFrameFormat" BO_ 2564554736 1;
BA_ "GenMsgCycleTime" BO_ 2566871591 100;
BA_ "GenMsgSendType" BO_ 2566871591 0;
BA_ "VFrameFormat" BO_ 2566871591 15;
BA_ "GenMsgSendType" BO_ 2566842094 0;
BA_ "VFrameFormat" BO_ 2566842094 1;
BA_ "GenMsgCycleTime" BO_ 2600402983 200;
BA_ "VFrameFormat" BO_ 2600402983 15;
BA_ "GenMsgSendType" BO_ 2566566695 0;
BA_ "VFrameFormat" BO_ 2566566695 15;
BA_ "GenMsgCycleTime" BO_ 2566843533 5000;
BA_ "GenMsgSendType" BO_ 2566843533 0;
BA_ "VFrameFormat" BO_ 2566843533 15;
BA_ "GenMsgCycleTime" BO_ 2566843535 5000;
BA_ "GenMsgSendType" BO_ 2566843535 0;
BA_ "VFrameFormat" BO_ 2566843535 15;
BA_ "GenMsgCycleTime" BO_ 2399091597 50;
BA_ "GenMsgSendType" BO_ 2399091597 0;
BA_ "E2EProfile" BO_ 2399091597 "P05";
BA_ "E2EDataId" BO_ 2399091597 9136;
BA_ "E2EDataLength" BO_ 2399091597 512;
BA_ "VFrameFormat" BO_ 2399091597 15;
BA_ "GenMsgCycleTime" BO_ 2399091599 50;
BA_ "GenMsgSendType" BO_ 2399091599 0;
BA_ "E2EProfile" BO_ 2399091599 "P05";
BA_ "E2EDataId" BO_ 2399091599 9137;
BA_ "E2EDataLength" BO_ 2399091599 512;
BA_ "VFrameFormat" BO_ 2399091599 15;
BA_ "GenMsgCycleTime" BO_ 2399092621 50;
BA_ "GenMsgSendType" BO_ 2399092621 0;
BA_ "E2EProfile" BO_ 2399092621 "P05";
BA_ "E2EDataId" BO_ 2399092621 9200;
BA_ "E2EDataLength" BO_ 2399092621 160;
BA_ "VFrameFormat" BO_ 2399092621 15;
BA_ "GenMsgCycleTime" BO_ 2399092623 50;
BA_ "GenMsgSendType" BO_ 2399092623 0;
BA_ "E2EProfile" BO_ 2399092623 "P05";
BA_ "E2EDataId" BO_ 2399092623 9201;
BA_ "E2EDataLength" BO_ 2399092623 160;
BA_ "VFrameFormat" BO_ 2399092623 15;
BA_ "GenMsgCycleTime" BO_ 2399091853 50;
BA_ "GenMsgSendType" BO_ 2399091853 0;
BA_ "E2EProfile" BO_ 2399091853 "P05";
BA_ "E2EDataId" BO_ 2399091853 9152;
BA_ "E2EDataLength" BO_ 2399091853 128;
BA_ "VFrameFormat" BO_ 2399091853 15;
BA_ "GenMsgCycleTime" BO_ 2399092109 50;
BA_ "GenMsgSendType" BO_ 2399092109 0;
BA_ "E2EProfile" BO_ 2399092109 "P05";
BA_ "E2EDataId" BO_ 2399092109 9168;
BA_ "E2EDataLength" BO_ 2399092109 512;
BA_ "VFrameFormat" BO_ 2399092109 15;
BA_ "GenMsgCycleTime" BO_ 2399092365 50;
BA_ "GenMsgSendType" BO_ 2399092365 0;
BA_ "E2EProfile" BO_ 2399092365 "P05";
BA_ "E2EDataId" BO_ 2399092365 9184;
BA_ "E2EDataLength" BO_ 2399092365 512;
BA_ "VFrameFormat" BO_ 2399092365 15;
BA_ "GenMsgCycleTime" BO_ 2399092111 50;
BA_ "GenMsgSendType" BO_ 2399092111 0;
BA_ "E2EProfile" BO_ 2399092111 "P05";
BA_ "E2EDataId" BO_ 2399092111 9169;
BA_ "E2EDataLength" BO_ 2399092111 512;
BA_ "VFrameFormat" BO_ 2399092111 15;
BA_ "GenMsgCycleTime" BO_ 2399092367 50;
BA_ "GenMsgSendType" BO_ 2399092367 0;
BA_ "E2EProfile" BO_ 2399092367 "P05";
BA_ "E2EDataId" BO_ 2399092367 9185;
BA_ "E2EDataLength" BO_ 2399092367 128;
BA_ "VFrameFormat" BO_ 2399092367 15;
BA_ "GenMsgCycleTime" BO_ 2399091855 50;
BA_ "GenMsgSendType" BO_ 2399091855 0;
BA_ "E2EProfile" BO_ 2399091855 "P05";
BA_ "E2EDataId" BO_ 2399091855 9153;
BA_ "E2EDataLength" BO_ 2399091855 128;
BA_ "VFrameFormat" BO_ 2399091855 15;
BA_ "GenMsgCycleTime" BO_ 2399089037 50;
BA_ "GenMsgSendType" BO_ 2399089037 0;
BA_ "E2EProfile" BO_ 2399089037 "P05";
BA_ "E2EDataId" BO_ 2399089037 8976;
BA_ "E2EDataLength" BO_ 2399089037 512;
BA_ "VFrameFormat" BO_ 2399089037 15;
BA_ "GenMsgCycleTime" BO_ 2399089293 50;
BA_ "GenMsgSendType" BO_ 2399089293 0;
BA_ "E2EProfile" BO_ 2399089293 "P05";
BA_ "E2EDataId" BO_ 2399089293 8992;
BA_ "E2EDataLength" BO_ 2399089293 512;
BA_ "VFrameFormat" BO_ 2399089293 15;
BA_ "GenMsgCycleTime" BO_ 2399089549 50;
BA_ "GenMsgSendType" BO_ 2399089549 0;
BA_ "E2EProfile" BO_ 2399089549 "P05";
BA_ "E2EDataId" BO_ 2399089549 9008;
BA_ "E2EDataLength" BO_ 2399089549 512;
BA_ "VFrameFormat" BO_ 2399089549 15;
BA_ "GenMsgCycleTime" BO_ 2399089805 50;
BA_ "GenMsgSendType" BO_ 2399089805 0;
BA_ "E2EProfile" BO_ 2399089805 "P05";
BA_ "E2EDataId" BO_ 2399089805 9024;
BA_ "E2EDataLength" BO_ 2399089805 512;
BA_ "VFrameFormat" BO_ 2399089805 15;
BA_ "GenMsgCycleTime" BO_ 2399090061 50;
BA_ "GenMsgSendType" BO_ 2399090061 0;
BA_ "E2EProfile" BO_ 2399090061 "P05";
BA_ "E2EDataId" BO_ 2399090061 9040;
BA_ "E2EDataLength" BO_ 2399090061 512;
BA_ "VFrameFormat" BO_ 2399090061 15;
BA_ "GenMsgCycleTime" BO_ 2399090317 50;
BA_ "GenMsgSendType" BO_ 2399090317 0;
BA_ "E2EProfile" BO_ 2399090317 "P05";
BA_ "E2EDataId" BO_ 2399090317 9056;
BA_ "E2EDataLength" BO_ 2399090317 512;
BA_ "VFrameFormat" BO_ 2399090317 15;
BA_ "GenMsgCycleTime" BO_ 2399090573 50;
BA_ "GenMsgSendType" BO_ 2399090573 0;
BA_ "E2EProfile" BO_ 2399090573 "P05";
BA_ "E2EDataId" BO_ 2399090573 9072;
BA_ "E2EDataLength" BO_ 2399090573 512;
BA_ "VFrameFormat" BO_ 2399090573 15;
BA_ "GenMsgCycleTime" BO_ 2399090829 50;
BA_ "GenMsgSendType" BO_ 2399090829 0;
BA_ "E2EProfile" BO_ 2399090829 "P05";
BA_ "E2EDataId" BO_ 2399090829 9088;
BA_ "E2EDataLength" BO_ 2399090829 512;
BA_ "VFrameFormat" BO_ 2399090829 15;
BA_ "SystemSignalLongSymbol" SG_ 2566871591 highResolutionTotalVehDistance_B "highResolutionTotalVehDistance_BASIS";
BA_ "SystemSignalLongSymbol" SG_ 2399091597 MasterDetectionTimestampSeconds_ "MasterDetectionTimestampSeconds_L";
BA_ "SystemSignalLongSymbol" SG_ 2399091599 MasterDetectionTimestampSec_0000 "MasterDetectionTimestampSeconds_R";
VAL_ 3221225472 BatchId_SRRObj_F_09 6 "Error" 7 "Not available" ;
VAL_ 3221225472 LonPosition_F_17 8160 "Error" 8176 "Not available" ;
VAL_ 3221225472 LonPositionStd_F_17 1022 "Error" 1023 "Not available" ;
VAL_ 3221225472 LatPosition_F_17 8160 "Error" 8176 "Not available" ;
VAL_ 3221225472 LatPositionStd_F_17 1022 "Error" 1023 "Not available" ;
VAL_ 3221225472 LonGndVel_F_17 8160 "Error" 8176 "Not available" ;
VAL_ 3221225472 LonGndVelStd_F_17 1022 "Error" 1023 "Not available" ;
VAL_ 3221225472 LatGndVel_F_17 8160 "Error" 8176 "Not available" ;
VAL_ 3221225472 LatGndVelStd_F_17 1022 "Error" 1023 "Not available" ;
VAL_ 3221225472 ExistenceProbability_F_17 254 "Error" 255 "Not available" ;
VAL_ 3221225472 Width_F_17 254 "Error" 255 "Not available" ;
VAL_ 3221225472 Length_F_17 1022 "Error" 1023 "Not available" ;
VAL_ 3221225472 HeadingAngle_F_17 254 "Error" 255 "Not available" ;
VAL_ 3221225472 DynamicProperty_F_17 0 "Invalid object" 1 "Stationary" 2 "Stopped" 3 "Moving" 6 "Error" 7 "Not available" ;
VAL_ 3221225472 ClassMostProb_F_17 0 "Unknown" 1 "Car" 2 "Motorbike" 3 "Truck" 4 "Bicycle" 5 "Pedestrian" 6 "Error" 7 "Not available" ;
VAL_ 3221225472 ClassMostProbConf_F_17 254 "Error" 255 "Not available" ;
VAL_ 3221225472 ClassSecMostProb_F_17 0 "Unknown" 1 "Car" 2 "Motorbike" 3 "Truck" 4 "Bicycle" 5 "Pedestrian" 6 "Error" 7 "Not available" ;
VAL_ 3221225472 ClassSecMostProbConf_F_17 254 "Error" 255 "Not available" ;
VAL_ 3221225472 MaintenanceState_F_17 0 "Not active" 1 "Newly created" 2 "Measured" 3 "Predicted" 6 "Error" 7 "Not available" ;
VAL_ 3221225472 YawRate_F_17 65024 "Error" 65280 "Not available" ;
VAL_ 3221225472 Occlusion_F_17 0 "Undefined" 1 "Occluded" 2 "On edge" 3 "Visible" 6 "Error" 7 "Not available" ;
VAL_ 3221225472 TrackingId_F_17 254 "Error" 255 "Not available" ;
VAL_ 3221225472 ReferencePoint_F_17 0 "Front left" 1 "Front" 2 "Front right" 3 "Right" 4 "Rear right" 5 "Rear" 6 "Rear left" 7 "Left" 8 "Object center" 14 "Error" 15 "Not available" ;
VAL_ 3221225472 RadarCrossSection_F_17 2046 "Error" 2047 "Not available" ;
VAL_ 3221225472 AgeSinceCreated_F_17 1022 "Error" 1023 "Not available" ;
VAL_ 3221225472 LonPosition_F_18 8160 "Error" 8176 "Not available" ;
VAL_ 3221225472 LonPositionStd_F_18 1022 "Error" 1023 "Not available" ;
VAL_ 3221225472 LatPosition_F_18 8160 "Error" 8176 "Not available" ;
VAL_ 3221225472 LatPositionStd_F_18 1022 "Error" 1023 "Not available" ;
VAL_ 3221225472 LonGndVel_F_18 8160 "Error" 8176 "Not available" ;
VAL_ 3221225472 LonGndVelStd_F_18 1022 "Error" 1023 "Not available" ;
VAL_ 3221225472 LatGndVel_F_18 8160 "Error" 8176 "Not available" ;
VAL_ 3221225472 LatGndVelStd_F_18 1022 "Error" 1023 "Not available" ;
VAL_ 3221225472 ExistenceProbability_F_18 254 "Error" 255 "Not available" ;
VAL_ 3221225472 Width_F_18 254 "Error" 255 "Not available" ;
VAL_ 3221225472 Length_F_18 1022 "Error" 1023 "Not available" ;
VAL_ 3221225472 HeadingAngle_F_18 254 "Error" 255 "Not available" ;
VAL_ 3221225472 DynamicProperty_F_18 0 "Invalid object" 1 "Stationary" 2 "Stopped" 3 "Moving" 6 "Error" 7 "Not available" ;
VAL_ 3221225472 ClassMostProb_F_18 0 "Unknown" 1 "Car" 2 "Motorbike" 3 "Truck" 4 "Bicycle" 5 "Pedestrian" 6 "Error" 7 "Not available" ;
VAL_ 3221225472 ClassMostProbConf_F_18 254 "Error" 255 "Not available" ;
VAL_ 3221225472 ClassSecMostProb_F_18 0 "Unknown" 1 "Car" 2 "Motorbike" 3 "Truck" 4 "Bicycle" 5 "Pedestrian" 6 "Error" 7 "Not available" ;
VAL_ 3221225472 ClassSecMostProbConf_F_18 254 "Error" 255 "Not available" ;
VAL_ 3221225472 MaintenanceState_F_18 0 "Not active" 1 "Newly created" 2 "Measured" 3 "Predicted" 6 "Error" 7 "Not available" ;
VAL_ 3221225472 YawRate_F_18 65024 "Error" 65280 "Not available" ;
VAL_ 3221225472 Occlusion_F_18 0 "Undefined" 1 "Occluded" 2 "On edge" 3 "Visible" 6 "Error" 7 "Not available" ;
VAL_ 3221225472 TrackingId_F_18 254 "Error" 255 "Not available" ;
VAL_ 3221225472 ReferencePoint_F_18 0 "Front left" 1 "Front" 2 "Front right" 3 "Right" 4 "Rear right" 5 "Rear" 6 "Rear left" 7 "Left" 8 "Object center" 14 "Error" 15 "Not available" ;
VAL_ 3221225472 RadarCrossSection_F_18 2046 "Error" 2047 "Not available" ;
VAL_ 3221225472 AgeSinceCreated_F_18 1022 "Error" 1023 "Not available" ;
VAL_ 2566871591 diagCondVehSpd_BASE 0 "condition not fullfilled" 1 "condition fullfilled" 2 "error" 3 "not available" ;
VAL_ 2566871591 drvSysActv_BASE 0 "drive system not active" 1 "drive system active" 2 "error" 3 "not available / not installed" ;
VAL_ 2566871591 clamp15netw_BASE 0 "Clamp 15 off" 1 "Clamp 15 on" 2 "error" 3 "not available" ;
VAL_ 2566871591 StartUpInProgress_BASE 0 "System is normal running" 1 "System is in engine start phase" 2 "error" 3 "not available" ;
VAL_ 2566871591 diagCondHighVoltage_BASE 0 "condition not fullfilled" 1 "condition fullfilled" 2 "error" 3 "not available" ;
VAL_ 2566871591 diagCondEngSpd_BASE 0 "condition not fullfilled" 1 "condition fullfilled" 2 "error" 3 "not available" ;
VAL_ 2566871591 highResolutionTotalVehDistance_B -1 "Not Available" -16777217 "ERROR" ;
VAL_ 2566871591 diagCondGearNeutral_BASE 0 "condition not fullfilled" 1 "condition fullfilled" 2 "error" 3 "not available" ;
VAL_ 2566871591 diagCondParkingBrake_BASE 0 "condition not fullfilled" 1 "condition fullfilled" 2 "error" 3 "not available" ;
VAL_ 2566871591 diagCondC1_BASE 0 "condition not fullfilled" 1 "condition fullfilled" 2 "error" 3 "not available" ;
VAL_ 2600402983 NM_ActiveWakeupBit 0 "passive wakeup" 1 "active wakeup" ;
VAL_ 2600402983 NM_CRI 0 "Standard Layout" 1 "TNB Layout" ;
VAL_ 2600402983 NM_State 1 "RM from BSM" 2 "RM from PBSM" 4 "NO from RM" 8 "NO from RS" ;
VAL_ 2600402983 NM_CarWakeup 0 "no Car-Wakeup request" 1 "Car-Wakeup request" ;
VAL_ 2600402983 NM_CC 0 "CC not active" 1 "CC active" ;
VAL_ 2600402983 NM_activeClamp15 0 "inactive" 1 "clamp15 active" ;
VAL_ 2600402983 NM_activeDiag 0 "inactive" 1 "Diagnostics active" ;
VAL_ 2600402983 NM_activeTmin 0 "inactive" 1 "Tmin not expired" ;
VAL_ 2600402983 NM_activeCWU 0 "inactive" 1 "CarWakeUp active" ;
VAL_ 2600402983 NM_activeFC 0 "inactive" 1 "FunctionCluster request active" ;
VAL_ 2600402983 nmClusterActive00 0 "off" 1 "on" ;
VAL_ 2600402983 nmClusterActive01 0 "off" 1 "on" ;
VAL_ 2600402983 nmClusterActive02 0 "off" 1 "on" ;
VAL_ 2600402983 nmClusterActive03 0 "off" 1 "on" ;
VAL_ 2600402983 nmClusterActive04 0 "off" 1 "on" ;
VAL_ 2600402983 nmClusterActive05 0 "off" 1 "on" ;
VAL_ 2600402983 nmClusterActive06 0 "off" 1 "on" ;
VAL_ 2600402983 nmClusterActive07 0 "off" 1 "on" ;
VAL_ 2600402983 nmClusterActive08 0 "off" 1 "on" ;
VAL_ 2600402983 nmClusterActive09 0 "off" 1 "on" ;
VAL_ 2600402983 nmClusterActive10 0 "off" 1 "on" ;
VAL_ 2600402983 nmClusterActive11 0 "off" 1 "on" ;
VAL_ 2600402983 nmClusterActive12 0 "off" 1 "on" ;
VAL_ 2600402983 nmClusterActive13 0 "off" 1 "on" ;
VAL_ 2600402983 nmClusterActive14 0 "off" 1 "on" ;
VAL_ 2600402983 nmClusterActive15 0 "off" 1 "on" ;
VAL_ 2600402983 nmClusterActive16 0 "off" 1 "on" ;
VAL_ 2600402983 nmClusterActive17 0 "off" 1 "on" ;
VAL_ 2600402983 nmClusterActive18 0 "off" 1 "on" ;
VAL_ 2600402983 nmClusterActive19 0 "off" 1 "on" ;
VAL_ 2600402983 nmClusterActive20 0 "off" 1 "on" ;
VAL_ 2600402983 nmClusterActive21 0 "off" 1 "on" ;
VAL_ 2600402983 nmClusterActive22 0 "off" 1 "on" ;
VAL_ 2600402983 nmClusterActive23 0 "off" 1 "on" ;
VAL_ 2399091597 BatchId_SRRHead_L 6 "Error" 7 "Not available" ;
VAL_ 2399091597 StateMachineStatus_L 0 "Wakeup" 1 "Limited function" 2 "Normal function" 3 "Go to power down" 4 "Fail safe" 14 "Error" 15 "Not available" ;
VAL_ 2399091597 BlockageMaster_L 0 "Not blocked" 1 "Blocked" 2 "Error" 3 "Not available" ;
VAL_ 2399091597 BlockageSlave_L 0 "Not blocked" 1 "Blocked" 2 "Error" 3 "Not available" ;
VAL_ 2399091597 TemperatureMaster_L 254 "Error" 255 "Not available" ;
VAL_ 2399091597 TemperatureSlave_L 254 "Error" 255 "Not available" ;
VAL_ 2399091597 AlignmentAngleMaster_L 254 "Error" 255 "Not available" ;
VAL_ 2399091597 AlignmentAngleSlave_L 254 "Error" 255 "Not available" ;
VAL_ 2399091597 AlignmentStatusMaster_L 0 "Not calibrated" 1 "Calibrated" 2 "Calibration failed" 3 "Misalignment angle out of range" 6 "Error" 7 "Not available" ;
VAL_ 2399091597 AlignmentStatusSlave_L 0 "Not calibrated" 1 "Calibrated" 2 "Calibration failed" 3 "Misalignment angle out of range" 6 "Error" 7 "Not available" ;
VAL_ 2399091597 AutoAlignmentActiveMaster_L 0 "Not active" 1 "Active" 2 "Error" 3 "Not available" ;
VAL_ 2399091597 AutoAlignmentActiveSlave_L 0 "Not active" 1 "Active" 2 "Error" 3 "Not available" ;
VAL_ 2399091597 ErrorBits_L 1 "TRUE" 0 "FALSE" ;
VAL_ 2399091597 CanTSynState_L 0 "Not synchronized" 1 "Synchronized without leap" 2 "Synchronized with leap" 6 "Error" 7 "Not Available" ;
VAL_ 2399091599 BatchId_SRRHead_R 6 "Error" 7 "Not available" ;
VAL_ 2399091599 StateMachineStatus_R 0 "Wakeup" 1 "Limited function" 2 "Normal function" 3 "Go to power down" 4 "Fail safe" 14 "Error" 15 "Not available" ;
VAL_ 2399091599 BlockageMaster_R 0 "Not blocked" 1 "Blocked" 2 "Error" 3 "Not available" ;
VAL_ 2399091599 BlockageSlave_R 0 "Not blocked" 1 "Blocked" 2 "Error" 3 "Not available" ;
VAL_ 2399091599 TemperatureMaster_R 254 "Error" 255 "Not available" ;
VAL_ 2399091599 TemperatureSlave_R 254 "Error" 255 "Not available" ;
VAL_ 2399091599 AlignmentAngleMaster_R 254 "Error" 255 "Not available" ;
VAL_ 2399091599 AlignmentAngleSlave_R 254 "Error" 255 "Not available" ;
VAL_ 2399091599 AlignmentStatusMaster_R 0 "Not calibrated" 1 "Calibrated" 2 "Calibration failed" 3 "Misalignment angle out of range" 6 "Error" 7 "Not available" ;
VAL_ 2399091599 AlignmentStatusSlave_R 0 "Not calibrated" 1 "Calibrated" 2 "Calibration failed" 3 "Misalignment angle out of range" 6 "Error" 7 "Not available" ;
VAL_ 2399091599 AutoAlignmentActiveMaster_R 0 "Not active" 1 "Active" 2 "Error" 3 "Not available" ;
VAL_ 2399091599 AutoAlignmentActiveSlave_R 0 "Not active" 1 "Active" 2 "Error" 3 "Not available" ;
VAL_ 2399091599 ErrorBits_R 1 "TRUE" 0 "FALSE" ;
VAL_ 2399091599 CanTSynState_R 0 "Not synchronized" 1 "Synchronized without leap" 2 "Synchronized with leap" 6 "Error" 7 "Not Available" ;
VAL_ 2399092621 BatchId_SRRTrai_L 6 "Error" 7 "Not available" ;
VAL_ 2399092621 TrailerFilterState_L 0 "Not started" 1 "Not active" 2 "Running" 3 "Complete" 6 "Error" 7 "Not available" ;
VAL_ 2399092621 Trailer1Present_L 0 "Not present" 1 "Present" 2 "Error" 3 "Not available" ;
VAL_ 2399092621 Trailer1Length_L 254 "Error" 255 "Not available" ;
VAL_ 2399092621 Trailer1Width_L 62 "Error" 63 "Not available" ;
VAL_ 2399092621 Trailer1Angle_L 4064 "Error" 4080 "Not available" ;
VAL_ 2399092621 Trailer1AngleConf_L 0 "Not ready" 1 "Not reliable" 2 "Reliable" 3 "SNA" 14 "Error" 15 "Not available" ;
VAL_ 2399092621 Trailer1CentOfRotToCentDist_L 126 "Error" 127 "Not available" ;
VAL_ 2399092621 Trailer1CentOfRotToWheelDist_L 510 "Error" 511 "Not available" ;
VAL_ 2399092621 Trailer1CentOfRotVCSLon_L 254 "Error" 255 "Not available" ;
VAL_ 2399092621 Trailer1CentOfRotVCSLat_L 510 "Error" 511 "Not available" ;
VAL_ 2399092621 Trailer2Present_L 0 "Not present" 1 "Present" 2 "Error" 3 "Not available" ;
VAL_ 2399092621 Trailer2Length_L 254 "Error" 255 "Not available" ;
VAL_ 2399092621 Trailer2Width_L 62 "Error" 63 "Not available" ;
VAL_ 2399092621 Trailer2Angle_L 4064 "Error" 4080 "Not available" ;
VAL_ 2399092621 Trailer2AngleConf_L 0 "Not ready" 1 "Not reliable" 2 "Reliable" 3 "SNA" 14 "Error" 15 "Not available" ;
VAL_ 2399092621 Trailer2CentOfRotToCentDist_L 126 "Error" 127 "Not available" ;
VAL_ 2399092621 Trailer2CentOfRotToWheelDist_L 510 "Error" 511 "Not available" ;
VAL_ 2399092621 Trailer2CentOfRotVCSLon_L 254 "Error" 255 "Not available" ;
VAL_ 2399092621 Trailer2CentOfRotVCSLat_L 510 "Error" 511 "Not available" ;
VAL_ 2399092623 BatchId_SRRTrai_R 6 "Error" 7 "Not available" ;
VAL_ 2399092623 TrailerFilterState_R 0 "Not started" 1 "Not active" 2 "Running" 3 "Complete" 6 "Error" 7 "Not available" ;
VAL_ 2399092623 Trailer1Present_R 0 "Not present" 1 "Present" 2 "Error" 3 "Not available" ;
VAL_ 2399092623 Trailer1Length_R 254 "Error" 255 "Not available" ;
VAL_ 2399092623 Trailer1Width_R 62 "Error" 63 "Not available" ;
VAL_ 2399092623 Trailer1Angle_R 4064 "Error" 4080 "Not available" ;
VAL_ 2399092623 Trailer1AngleConf_R 0 "Not ready" 1 "Not reliable" 2 "Reliable" 3 "SNA" 14 "Error" 15 "Not available" ;
VAL_ 2399092623 Trailer1CentOfRotToCentDist_R 126 "Error" 127 "Not available" ;
VAL_ 2399092623 Trailer1CentOfRotToWheelDist_R 510 "Error" 511 "Not available" ;
VAL_ 2399092623 Trailer1CentOfRotVCSLon_R 254 "Error" 255 "Not available" ;
VAL_ 2399092623 Trailer1CentOfRotVCSLat_R 510 "Error" 511 "Not available" ;
VAL_ 2399092623 Trailer2Present_R 0 "Not present" 1 "Present" 2 "Error" 3 "Not available" ;
VAL_ 2399092623 Trailer2Length_R 254 "Error" 255 "Not available" ;
VAL_ 2399092623 Trailer2Width_R 62 "Error" 63 "Not available" ;
VAL_ 2399092623 Trailer2Angle_R 4064 "Error" 4080 "Not available" ;
VAL_ 2399092623 Trailer2AngleConf_R 0 "Not ready" 1 "Not reliable" 2 "Reliable" 3 "SNA" 14 "Error" 15 "Not available" ;
VAL_ 2399092623 Trailer2CentOfRotToCentDist_R 126 "Error" 127 "Not available" ;
VAL_ 2399092623 Trailer2CentOfRotToWheelDist_R 510 "Error" 511 "Not available" ;
VAL_ 2399092623 Trailer2CentOfRotVCSLon_R 254 "Error" 255 "Not available" ;
VAL_ 2399092623 Trailer2CentOfRotVCSLat_R 510 "Error" 511 "Not available" ;
VAL_ 2399091853 BatchId_SRRBoundHdr_L 6 "Error" 7 "Not available" ;
VAL_ 2399091853 NumCountours_L 14 "Error" 15 "Not available" ;
VAL_ 2399091853 CountourId_L_01 62 "Error" 63 "Not available" ;
VAL_ 2399091853 NumCountourVertices_L_01 62 "Error" 63 "Not available" ;
VAL_ 2399091853 CountourId_L_02 62 "Error" 63 "Not available" ;
VAL_ 2399091853 NumCountourVertices_L_02 62 "Error" 63 "Not available" ;
VAL_ 2399091853 CountourId_L_03 62 "Error" 63 "Not available" ;
VAL_ 2399091853 NumCountourVertices_L_03 62 "Error" 63 "Not available" ;
VAL_ 2399091853 CountourId_L_04 62 "Error" 63 "Not available" ;
VAL_ 2399091853 NumCountourVertices_L_04 62 "Error" 63 "Not available" ;
VAL_ 2399091853 CountourId_L_05 62 "Error" 63 "Not available" ;
VAL_ 2399091853 NumCountourVertices_L_05 62 "Error" 63 "Not available" ;
VAL_ 2399091853 CountourId_L_06 62 "Error" 63 "Not available" ;
VAL_ 2399091853 NumCountourVertices_L_06 62 "Error" 63 "Not available" ;
VAL_ 2399092109 BatchId_SRRBoundSegs_L_01 6 "Error" 7 "Not available" ;
VAL_ 2399092109 VertexAge_L_01 62 "Error" 63 "Not available" ;
VAL_ 2399092109 VertexPosX_L_01 4064 "Error" 4080 "Not available" ;
VAL_ 2399092109 VertexPosY_L_01 2046 "Error" 2047 "Not available" ;
VAL_ 2399092109 VertexAge_L_02 62 "Error" 63 "Not available" ;
VAL_ 2399092109 VertexPosX_L_02 4064 "Error" 4080 "Not available" ;
VAL_ 2399092109 VertexPosY_L_02 2046 "Error" 2047 "Not available" ;
VAL_ 2399092109 VertexAge_L_03 62 "Error" 63 "Not available" ;
VAL_ 2399092109 VertexPosX_L_03 4064 "Error" 4080 "Not available" ;
VAL_ 2399092109 VertexPosY_L_03 2046 "Error" 2047 "Not available" ;
VAL_ 2399092109 VertexAge_L_04 62 "Error" 63 "Not available" ;
VAL_ 2399092109 VertexPosX_L_04 4064 "Error" 4080 "Not available" ;
VAL_ 2399092109 VertexPosY_L_04 2046 "Error" 2047 "Not available" ;
VAL_ 2399092109 VertexAge_L_05 62 "Error" 63 "Not available" ;
VAL_ 2399092109 VertexPosX_L_05 4064 "Error" 4080 "Not available" ;
VAL_ 2399092109 VertexPosY_L_05 2046 "Error" 2047 "Not available" ;
VAL_ 2399092109 VertexAge_L_06 62 "Error" 63 "Not available" ;
VAL_ 2399092109 VertexPosX_L_06 4064 "Error" 4080 "Not available" ;
VAL_ 2399092109 VertexPosY_L_06 2046 "Error" 2047 "Not available" ;
VAL_ 2399092109 VertexAge_L_07 62 "Error" 63 "Not available" ;
VAL_ 2399092109 VertexPosX_L_07 4064 "Error" 4080 "Not available" ;
VAL_ 2399092109 VertexPosY_L_07 2046 "Error" 2047 "Not available" ;
VAL_ 2399092109 VertexAge_L_08 62 "Error" 63 "Not available" ;
VAL_ 2399092109 VertexPosX_L_08 4064 "Error" 4080 "Not available" ;
VAL_ 2399092109 VertexPosY_L_08 2046 "Error" 2047 "Not available" ;
VAL_ 2399092109 VertexAge_L_09 62 "Error" 63 "Not available" ;
VAL_ 2399092109 VertexPosX_L_09 4064 "Error" 4080 "Not available" ;
VAL_ 2399092109 VertexPosY_L_09 2046 "Error" 2047 "Not available" ;
VAL_ 2399092109 VertexAge_L_10 62 "Error" 63 "Not available" ;
VAL_ 2399092109 VertexPosX_L_10 4064 "Error" 4080 "Not available" ;
VAL_ 2399092109 VertexPosY_L_10 2046 "Error" 2047 "Not available" ;
VAL_ 2399092109 VertexAge_L_11 62 "Error" 63 "Not available" ;
VAL_ 2399092109 VertexPosX_L_11 4064 "Error" 4080 "Not available" ;
VAL_ 2399092109 VertexPosY_L_11 2046 "Error" 2047 "Not available" ;
VAL_ 2399092109 VertexAge_L_12 62 "Error" 63 "Not available" ;
VAL_ 2399092109 VertexPosX_L_12 4064 "Error" 4080 "Not available" ;
VAL_ 2399092109 VertexPosY_L_12 2046 "Error" 2047 "Not available" ;
VAL_ 2399092109 VertexAge_L_13 62 "Error" 63 "Not available" ;
VAL_ 2399092109 VertexPosX_L_13 4064 "Error" 4080 "Not available" ;
VAL_ 2399092109 VertexPosY_L_13 2046 "Error" 2047 "Not available" ;
VAL_ 2399092109 VertexAge_L_14 62 "Error" 63 "Not available" ;
VAL_ 2399092109 VertexPosX_L_14 4064 "Error" 4080 "Not available" ;
VAL_ 2399092109 VertexPosY_L_14 2046 "Error" 2047 "Not available" ;
VAL_ 2399092109 VertexAge_L_15 62 "Error" 63 "Not available" ;
VAL_ 2399092109 VertexPosX_L_15 4064 "Error" 4080 "Not available" ;
VAL_ 2399092109 VertexPosY_L_15 2046 "Error" 2047 "Not available" ;
VAL_ 2399092109 VertexAge_L_16 62 "Error" 63 "Not available" ;
VAL_ 2399092109 VertexPosX_L_16 4064 "Error" 4080 "Not available" ;
VAL_ 2399092109 VertexPosY_L_16 2046 "Error" 2047 "Not available" ;
VAL_ 2399092365 BatchId_SRRBoundSegs_L_02 6 "Error" 7 "Not available" ;
VAL_ 2399092365 VertexAge_L_17 62 "Error" 63 "Not available" ;
VAL_ 2399092365 VertexPosX_L_17 4064 "Error" 4080 "Not available" ;
VAL_ 2399092365 VertexPosY_L_17 2046 "Error" 2047 "Not available" ;
VAL_ 2399092365 VertexAge_L_18 62 "Error" 63 "Not available" ;
VAL_ 2399092365 VertexPosX_L_18 4064 "Error" 4080 "Not available" ;
VAL_ 2399092365 VertexPosY_L_18 2046 "Error" 2047 "Not available" ;
VAL_ 2399092365 VertexAge_L_19 62 "Error" 63 "Not available" ;
VAL_ 2399092365 VertexPosX_L_19 4064 "Error" 4080 "Not available" ;
VAL_ 2399092365 VertexPosY_L_19 2046 "Error" 2047 "Not available" ;
VAL_ 2399092365 VertexAge_L_20 62 "Error" 63 "Not available" ;
VAL_ 2399092365 VertexPosX_L_20 4064 "Error" 4080 "Not available" ;
VAL_ 2399092365 VertexPosY_L_20 2046 "Error" 2047 "Not available" ;
VAL_ 2399092365 VertexAge_L_21 62 "Error" 63 "Not available" ;
VAL_ 2399092365 VertexPosX_L_21 4064 "Error" 4080 "Not available" ;
VAL_ 2399092365 VertexPosY_L_21 2046 "Error" 2047 "Not available" ;
VAL_ 2399092365 VertexAge_L_22 62 "Error" 63 "Not available" ;
VAL_ 2399092365 VertexPosX_L_22 4064 "Error" 4080 "Not available" ;
VAL_ 2399092365 VertexPosY_L_22 2046 "Error" 2047 "Not available" ;
VAL_ 2399092365 VertexAge_L_23 62 "Error" 63 "Not available" ;
VAL_ 2399092365 VertexPosX_L_23 4064 "Error" 4080 "Not available" ;
VAL_ 2399092365 VertexPosY_L_23 2046 "Error" 2047 "Not available" ;
VAL_ 2399092365 VertexAge_L_24 62 "Error" 63 "Not available" ;
VAL_ 2399092365 VertexPosX_L_24 4064 "Error" 4080 "Not available" ;
VAL_ 2399092365 VertexPosY_L_24 2046 "Error" 2047 "Not available" ;
VAL_ 2399092365 VertexAge_L_25 62 "Error" 63 "Not available" ;
VAL_ 2399092365 VertexPosX_L_25 4064 "Error" 4080 "Not available" ;
VAL_ 2399092365 VertexPosY_L_25 2046 "Error" 2047 "Not available" ;
VAL_ 2399092365 VertexAge_L_26 62 "Error" 63 "Not available" ;
VAL_ 2399092365 VertexPosX_L_26 4064 "Error" 4080 "Not available" ;
VAL_ 2399092365 VertexPosY_L_26 2046 "Error" 2047 "Not available" ;
VAL_ 2399092365 VertexAge_L_27 62 "Error" 63 "Not available" ;
VAL_ 2399092365 VertexPosX_L_27 4064 "Error" 4080 "Not available" ;
VAL_ 2399092365 VertexPosY_L_27 2046 "Error" 2047 "Not available" ;
VAL_ 2399092365 VertexAge_L_28 62 "Error" 63 "Not available" ;
VAL_ 2399092365 VertexPosX_L_28 4064 "Error" 4080 "Not available" ;
VAL_ 2399092365 VertexPosY_L_28 2046 "Error" 2047 "Not available" ;
VAL_ 2399092365 VertexAge_L_29 62 "Error" 63 "Not available" ;
VAL_ 2399092365 VertexPosX_L_29 4064 "Error" 4080 "Not available" ;
VAL_ 2399092365 VertexPosY_L_29 2046 "Error" 2047 "Not available" ;
VAL_ 2399092365 VertexAge_L_30 62 "Error" 63 "Not available" ;
VAL_ 2399092365 VertexPosX_L_30 4064 "Error" 4080 "Not available" ;
VAL_ 2399092365 VertexPosY_L_30 2046 "Error" 2047 "Not available" ;
VAL_ 2399092365 VertexAge_L_31 62 "Error" 63 "Not available" ;
VAL_ 2399092365 VertexPosX_L_31 4064 "Error" 4080 "Not available" ;
VAL_ 2399092365 VertexPosY_L_31 2046 "Error" 2047 "Not available" ;
VAL_ 2399092365 VertexAge_L_32 62 "Error" 63 "Not available" ;
VAL_ 2399092365 VertexPosX_L_32 4064 "Error" 4080 "Not available" ;
VAL_ 2399092365 VertexPosY_L_32 2046 "Error" 2047 "Not available" ;
VAL_ 2399092111 BatchId_SRRBoundSegs_R_01 6 "Error" 7 "Not available" ;
VAL_ 2399092111 VertexAge_R_01 62 "Error" 63 "Not available" ;
VAL_ 2399092111 VertexPosX_R_01 4064 "Error" 4080 "Not available" ;
VAL_ 2399092111 VertexPosY_R_01 2046 "Error" 2047 "Not available" ;
VAL_ 2399092111 VertexAge_R_02 62 "Error" 63 "Not available" ;
VAL_ 2399092111 VertexPosX_R_02 4064 "Error" 4080 "Not available" ;
VAL_ 2399092111 VertexPosY_R_02 2046 "Error" 2047 "Not available" ;
VAL_ 2399092111 VertexAge_R_03 62 "Error" 63 "Not available" ;
VAL_ 2399092111 VertexPosX_R_03 4064 "Error" 4080 "Not available" ;
VAL_ 2399092111 VertexPosY_R_03 2046 "Error" 2047 "Not available" ;
VAL_ 2399092111 VertexAge_R_04 62 "Error" 63 "Not available" ;
VAL_ 2399092111 VertexPosX_R_04 4064 "Error" 4080 "Not available" ;
VAL_ 2399092111 VertexPosY_R_04 2046 "Error" 2047 "Not available" ;
VAL_ 2399092111 VertexAge_R_05 62 "Error" 63 "Not available" ;
VAL_ 2399092111 VertexPosX_R_05 4064 "Error" 4080 "Not available" ;
VAL_ 2399092111 VertexPosY_R_05 2046 "Error" 2047 "Not available" ;
VAL_ 2399092111 VertexAge_R_06 62 "Error" 63 "Not available" ;
VAL_ 2399092111 VertexPosX_R_06 4064 "Error" 4080 "Not available" ;
VAL_ 2399092111 VertexPosY_R_06 2046 "Error" 2047 "Not available" ;
VAL_ 2399092111 VertexAge_R_07 62 "Error" 63 "Not available" ;
VAL_ 2399092111 VertexPosX_R_07 4064 "Error" 4080 "Not available" ;
VAL_ 2399092111 VertexPosY_R_07 2046 "Error" 2047 "Not available" ;
VAL_ 2399092111 VertexAge_R_08 62 "Error" 63 "Not available" ;
VAL_ 2399092111 VertexPosX_R_08 4064 "Error" 4080 "Not available" ;
VAL_ 2399092111 VertexPosY_R_08 2046 "Error" 2047 "Not available" ;
VAL_ 2399092111 VertexAge_R_09 62 "Error" 63 "Not available" ;
VAL_ 2399092111 VertexPosX_R_09 4064 "Error" 4080 "Not available" ;
VAL_ 2399092111 VertexPosY_R_09 2046 "Error" 2047 "Not available" ;
VAL_ 2399092111 VertexAge_R_10 62 "Error" 63 "Not available" ;
VAL_ 2399092111 VertexPosX_R_10 4064 "Error" 4080 "Not available" ;
VAL_ 2399092111 VertexPosY_R_10 2046 "Error" 2047 "Not available" ;
VAL_ 2399092111 VertexAge_R_11 62 "Error" 63 "Not available" ;
VAL_ 2399092111 VertexPosX_R_11 4064 "Error" 4080 "Not available" ;
VAL_ 2399092111 VertexPosY_R_11 2046 "Error" 2047 "Not available" ;
VAL_ 2399092111 VertexAge_R_12 62 "Error" 63 "Not available" ;
VAL_ 2399092111 VertexPosX_R_12 4064 "Error" 4080 "Not available" ;
VAL_ 2399092111 VertexPosY_R_12 2046 "Error" 2047 "Not available" ;
VAL_ 2399092111 VertexAge_R_13 62 "Error" 63 "Not available" ;
VAL_ 2399092111 VertexPosX_R_13 4064 "Error" 4080 "Not available" ;
VAL_ 2399092111 VertexPosY_R_13 2046 "Error" 2047 "Not available" ;
VAL_ 2399092111 VertexAge_R_14 62 "Error" 63 "Not available" ;
VAL_ 2399092111 VertexPosX_R_14 4064 "Error" 4080 "Not available" ;
VAL_ 2399092111 VertexPosY_R_14 2046 "Error" 2047 "Not available" ;
VAL_ 2399092111 VertexAge_R_15 62 "Error" 63 "Not available" ;
VAL_ 2399092111 VertexPosX_R_15 4064 "Error" 4080 "Not available" ;
VAL_ 2399092111 VertexPosY_R_15 2046 "Error" 2047 "Not available" ;
VAL_ 2399092111 VertexAge_R_16 62 "Error" 63 "Not available" ;
VAL_ 2399092111 VertexPosX_R_16 4064 "Error" 4080 "Not available" ;
VAL_ 2399092111 VertexPosY_R_16 2046 "Error" 2047 "Not available" ;
VAL_ 2399092367 BatchId_SRRBoundSegs_R_02 6 "Error" 7 "Not available" ;
VAL_ 2399092367 VertexAge_R_17 62 "Error" 63 "Not available" ;
VAL_ 2399092367 VertexPosX_R_17 4064 "Error" 4080 "Not available" ;
VAL_ 2399092367 VertexPosY_R_17 2046 "Error" 2047 "Not available" ;
VAL_ 2399092367 VertexAge_R_18 62 "Error" 63 "Not available" ;
VAL_ 2399092367 VertexPosX_R_18 4064 "Error" 4080 "Not available" ;
VAL_ 2399092367 VertexPosY_R_18 2046 "Error" 2047 "Not available" ;
VAL_ 2399092367 VertexAge_R_19 62 "Error" 63 "Not available" ;
VAL_ 2399092367 VertexPosX_R_19 4064 "Error" 4080 "Not available" ;
VAL_ 2399092367 VertexPosY_R_19 2046 "Error" 2047 "Not available" ;
VAL_ 2399092367 VertexAge_R_20 62 "Error" 63 "Not available" ;
VAL_ 2399092367 VertexPosX_R_20 4064 "Error" 4080 "Not available" ;
VAL_ 2399092367 VertexPosY_R_20 2046 "Error" 2047 "Not available" ;
VAL_ 2399092367 VertexAge_R_21 62 "Error" 63 "Not available" ;
VAL_ 2399092367 VertexPosX_R_21 4064 "Error" 4080 "Not available" ;
VAL_ 2399092367 VertexPosY_R_21 2046 "Error" 2047 "Not available" ;
VAL_ 2399092367 VertexAge_R_22 62 "Error" 63 "Not available" ;
VAL_ 2399092367 VertexPosX_R_22 4064 "Error" 4080 "Not available" ;
VAL_ 2399092367 VertexPosY_R_22 2046 "Error" 2047 "Not available" ;
VAL_ 2399092367 VertexAge_R_23 62 "Error" 63 "Not available" ;
VAL_ 2399092367 VertexPosX_R_23 4064 "Error" 4080 "Not available" ;
VAL_ 2399092367 VertexPosY_R_23 2046 "Error" 2047 "Not available" ;
VAL_ 2399092367 VertexAge_R_24 62 "Error" 63 "Not available" ;
VAL_ 2399092367 VertexPosX_R_24 4064 "Error" 4080 "Not available" ;
VAL_ 2399092367 VertexPosY_R_24 2046 "Error" 2047 "Not available" ;
VAL_ 2399092367 VertexAge_R_25 62 "Error" 63 "Not available" ;
VAL_ 2399092367 VertexPosX_R_25 4064 "Error" 4080 "Not available" ;
VAL_ 2399092367 VertexPosY_R_25 2046 "Error" 2047 "Not available" ;
VAL_ 2399092367 VertexAge_R_26 62 "Error" 63 "Not available" ;
VAL_ 2399092367 VertexPosX_R_26 4064 "Error" 4080 "Not available" ;
VAL_ 2399092367 VertexPosY_R_26 2046 "Error" 2047 "Not available" ;
VAL_ 2399092367 VertexAge_R_27 62 "Error" 63 "Not available" ;
VAL_ 2399092367 VertexPosX_R_27 4064 "Error" 4080 "Not available" ;
VAL_ 2399092367 VertexPosY_R_27 2046 "Error" 2047 "Not available" ;
VAL_ 2399092367 VertexAge_R_28 62 "Error" 63 "Not available" ;
VAL_ 2399092367 VertexPosX_R_28 4064 "Error" 4080 "Not available" ;
VAL_ 2399092367 VertexPosY_R_28 2046 "Error" 2047 "Not available" ;
VAL_ 2399092367 VertexAge_R_29 62 "Error" 63 "Not available" ;
VAL_ 2399092367 VertexPosX_R_29 4064 "Error" 4080 "Not available" ;
VAL_ 2399092367 VertexPosY_R_29 2046 "Error" 2047 "Not available" ;
VAL_ 2399092367 VertexAge_R_30 62 "Error" 63 "Not available" ;
VAL_ 2399092367 VertexPosX_R_30 4064 "Error" 4080 "Not available" ;
VAL_ 2399092367 VertexPosY_R_30 2046 "Error" 2047 "Not available" ;
VAL_ 2399092367 VertexAge_R_31 62 "Error" 63 "Not available" ;
VAL_ 2399092367 VertexPosX_R_31 4064 "Error" 4080 "Not available" ;
VAL_ 2399092367 VertexPosY_R_31 2046 "Error" 2047 "Not available" ;
VAL_ 2399092367 VertexAge_R_32 62 "Error" 63 "Not available" ;
VAL_ 2399092367 VertexPosX_R_32 4064 "Error" 4080 "Not available" ;
VAL_ 2399092367 VertexPosY_R_32 2046 "Error" 2047 "Not available" ;
VAL_ 2399091855 BatchId_SRRBoundHdr_R 6 "Error" 7 "Not available" ;
VAL_ 2399091855 NumCountours_R 14 "Error" 15 "Not available" ;
VAL_ 2399091855 CountourId_R_01 62 "Error" 63 "Not available" ;
VAL_ 2399091855 NumCountourVertices_R_01 62 "Error" 63 "Not available" ;
VAL_ 2399091855 CountourId_R_02 62 "Error" 63 "Not available" ;
VAL_ 2399091855 NumCountourVertices_R_02 62 "Error" 63 "Not available" ;
VAL_ 2399091855 CountourId_R_03 62 "Error" 63 "Not available" ;
VAL_ 2399091855 NumCountourVertices_R_03 62 "Error" 63 "Not available" ;
VAL_ 2399091855 CountourId_R_04 62 "Error" 63 "Not available" ;
VAL_ 2399091855 NumCountourVertices_R_04 62 "Error" 63 "Not available" ;
VAL_ 2399091855 CountourId_R_05 62 "Error" 63 "Not available" ;
VAL_ 2399091855 NumCountourVertices_R_05 62 "Error" 63 "Not available" ;
VAL_ 2399091855 CountourId_R_06 62 "Error" 63 "Not available" ;
VAL_ 2399091855 NumCountourVertices_R_06 62 "Error" 63 "Not available" ;
VAL_ 2399089037 BatchId_SRRObj_L_01 6 "Error" 7 "Not available" ;
VAL_ 2399089037 LonPosition_L_01 8160 "Error" 8176 "Not available" ;
VAL_ 2399089037 LonPositionStd_L_01 1022 "Error" 1023 "Not available" ;
VAL_ 2399089037 LatPosition_L_01 8160 "Error" 8176 "Not available" ;
VAL_ 2399089037 LatPositionStd_L_01 1022 "Error" 1023 "Not available" ;
VAL_ 2399089037 LonGndVel_L_01 8160 "Error" 8176 "Not available" ;
VAL_ 2399089037 LonGndVelStd_L_01 1022 "Error" 1023 "Not available" ;
VAL_ 2399089037 LatGndVel_L_01 8160 "Error" 8176 "Not available" ;
VAL_ 2399089037 LatGndVelStd_L_01 1022 "Error" 1023 "Not available" ;
VAL_ 2399089037 ExistenceProbability_L_01 254 "Error" 255 "Not available" ;
VAL_ 2399089037 Width_L_01 254 "Error" 255 "Not available" ;
VAL_ 2399089037 Length_L_01 1022 "Error" 1023 "Not available" ;
VAL_ 2399089037 HeadingAngle_L_01 254 "Error" 255 "Not available" ;
VAL_ 2399089037 DynamicProperty_L_01 0 "Invalid object" 1 "Stationary" 2 "Stopped" 3 "Moving" 6 "Error" 7 "Not available" ;
VAL_ 2399089037 ClassMostProb_L_01 0 "Unknown" 1 "Car" 2 "Motorbike" 3 "Truck" 4 "Bicycle" 5 "Pedestrian" 6 "Error" 7 "Not available" ;
VAL_ 2399089037 ClassMostProbConf_L_01 254 "Error" 255 "Not available" ;
VAL_ 2399089037 ClassSecMostProb_L_01 0 "Unknown" 1 "Car" 2 "Motorbike" 3 "Truck" 4 "Bicycle" 5 "Pedestrian" 6 "Error" 7 "Not available" ;
VAL_ 2399089037 ClassSecMostProbConf_L_01 254 "Error" 255 "Not available" ;
VAL_ 2399089037 MaintenanceState_L_01 0 "Not active" 1 "Newly created" 2 "Measured" 3 "Predicted" 6 "Error" 7 "Not available" ;
VAL_ 2399089037 YawRate_L_01 65024 "Error" 65280 "Not available" ;
VAL_ 2399089037 Occlusion_L_01 0 "Undefined" 1 "Occluded" 2 "On edge" 3 "Visible" 6 "Error" 7 "Not available" ;
VAL_ 2399089037 TrackingId_L_01 254 "Error" 255 "Not available" ;
VAL_ 2399089037 ReferencePoint_L_01 0 "Front left" 1 "Front" 2 "Front right" 3 "Right" 4 "Rear right" 5 "Rear" 6 "Rear left" 7 "Left" 8 "Unknown" 14 "Error" 15 "Not available" ;
VAL_ 2399089037 RadarCrossSection_L_01 2046 "Error" 2047 "Not available" ;
VAL_ 2399089037 AgeSinceCreated_L_01 1022 "Error" 1023 "Not available" ;
VAL_ 2399089037 LonPosition_L_02 8160 "Error" 8176 "Not available" ;
VAL_ 2399089037 LonPositionStd_L_02 1022 "Error" 1023 "Not available" ;
VAL_ 2399089037 LatPosition_L_02 8160 "Error" 8176 "Not available" ;
VAL_ 2399089037 LatPositionStd_L_02 1022 "Error" 1023 "Not available" ;
VAL_ 2399089037 LonGndVel_L_02 8160 "Error" 8176 "Not available" ;
VAL_ 2399089037 LonGndVelStd_L_02 1022 "Error" 1023 "Not available" ;
VAL_ 2399089037 LatGndVel_L_02 8160 "Error" 8176 "Not available" ;
VAL_ 2399089037 LatGndVelStd_L_02 1022 "Error" 1023 "Not available" ;
VAL_ 2399089037 ExistenceProbability_L_02 254 "Error" 255 "Not available" ;
VAL_ 2399089037 Width_L_02 254 "Error" 255 "Not available" ;
VAL_ 2399089037 Length_L_02 1022 "Error" 1023 "Not available" ;
VAL_ 2399089037 HeadingAngle_L_02 254 "Error" 255 "Not available" ;
VAL_ 2399089037 DynamicProperty_L_02 0 "Invalid object" 1 "Stationary" 2 "Stopped" 3 "Moving" 6 "Error" 7 "Not available" ;
VAL_ 2399089037 ClassMostProb_L_02 0 "Unknown" 1 "Car" 2 "Motorbike" 3 "Truck" 4 "Bicycle" 5 "Pedestrian" 6 "Error" 7 "Not available" ;
VAL_ 2399089037 ClassMostProbConf_L_02 254 "Error" 255 "Not available" ;
VAL_ 2399089037 ClassSecMostProb_L_02 0 "Unknown" 1 "Car" 2 "Motorbike" 3 "Truck" 4 "Bicycle" 5 "Pedestrian" 6 "Error" 7 "Not available" ;
VAL_ 2399089037 ClassSecMostProbConf_L_02 254 "Error" 255 "Not available" ;
VAL_ 2399089037 MaintenanceState_L_02 0 "Not active" 1 "Newly created" 2 "Measured" 3 "Predicted" 6 "Error" 7 "Not available" ;
VAL_ 2399089037 YawRate_L_02 65024 "Error" 65280 "Not available" ;
VAL_ 2399089037 Occlusion_L_02 0 "Undefined" 1 "Occluded" 2 "On edge" 3 "Visible" 6 "Error" 7 "Not available" ;
VAL_ 2399089037 TrackingId_L_02 254 "Error" 255 "Not available" ;
VAL_ 2399089037 ReferencePoint_L_02 0 "Front left" 1 "Front" 2 "Front right" 3 "Right" 4 "Rear right" 5 "Rear" 6 "Rear left" 7 "Left" 8 "Unknown" 14 "Error" 15 "Not available" ;
VAL_ 2399089037 RadarCrossSection_L_02 2046 "Error" 2047 "Not available" ;
VAL_ 2399089037 AgeSinceCreated_L_02 1022 "Error" 1023 "Not available" ;
VAL_ 2399089293 BatchId_SRRObj_L_02 6 "Error" 7 "Not available" ;
VAL_ 2399089293 LonPosition_L_03 8160 "Error" 8176 "Not available" ;
VAL_ 2399089293 LonPositionStd_L_03 1022 "Error" 1023 "Not available" ;
VAL_ 2399089293 LatPosition_L_03 8160 "Error" 8176 "Not available" ;
VAL_ 2399089293 LatPositionStd_L_03 1022 "Error" 1023 "Not available" ;
VAL_ 2399089293 LonGndVel_L_03 8160 "Error" 8176 "Not available" ;
VAL_ 2399089293 LonGndVelStd_L_03 1022 "Error" 1023 "Not available" ;
VAL_ 2399089293 LatGndVel_L_03 8160 "Error" 8176 "Not available" ;
VAL_ 2399089293 LatGndVelStd_L_03 1022 "Error" 1023 "Not available" ;
VAL_ 2399089293 ExistenceProbability_L_03 254 "Error" 255 "Not available" ;
VAL_ 2399089293 Width_L_03 254 "Error" 255 "Not available" ;
VAL_ 2399089293 Length_L_03 1022 "Error" 1023 "Not available" ;
VAL_ 2399089293 HeadingAngle_L_03 254 "Error" 255 "Not available" ;
VAL_ 2399089293 DynamicProperty_L_03 0 "Invalid object" 1 "Stationary" 2 "Stopped" 3 "Moving" 6 "Error" 7 "Not available" ;
VAL_ 2399089293 ClassMostProb_L_03 0 "Unknown" 1 "Car" 2 "Motorbike" 3 "Truck" 4 "Bicycle" 5 "Pedestrian" 6 "Error" 7 "Not available" ;
VAL_ 2399089293 ClassMostProbConf_L_03 254 "Error" 255 "Not available" ;
VAL_ 2399089293 ClassSecMostProb_L_03 0 "Unknown" 1 "Car" 2 "Motorbike" 3 "Truck" 4 "Bicycle" 5 "Pedestrian" 6 "Error" 7 "Not available" ;
VAL_ 2399089293 ClassSecMostProbConf_L_03 254 "Error" 255 "Not available" ;
VAL_ 2399089293 MaintenanceState_L_03 0 "Not active" 1 "Newly created" 2 "Measured" 3 "Predicted" 6 "Error" 7 "Not available" ;
VAL_ 2399089293 YawRate_L_03 65024 "Error" 65280 "Not available" ;
VAL_ 2399089293 Occlusion_L_03 0 "Undefined" 1 "Occluded" 2 "On edge" 3 "Visible" 6 "Error" 7 "Not available" ;
VAL_ 2399089293 TrackingId_L_03 254 "Error" 255 "Not available" ;
VAL_ 2399089293 ReferencePoint_L_03 0 "Front left" 1 "Front" 2 "Front right" 3 "Right" 4 "Rear right" 5 "Rear" 6 "Rear left" 7 "Left" 8 "Unknown" 14 "Error" 15 "Not available" ;
VAL_ 2399089293 RadarCrossSection_L_03 2046 "Error" 2047 "Not available" ;
VAL_ 2399089293 AgeSinceCreated_L_03 1022 "Error" 1023 "Not available" ;
VAL_ 2399089293 LonPosition_L_04 8160 "Error" 8176 "Not available" ;
VAL_ 2399089293 LonPositionStd_L_04 1022 "Error" 1023 "Not available" ;
VAL_ 2399089293 LatPosition_L_04 8160 "Error" 8176 "Not available" ;
VAL_ 2399089293 LatPositionStd_L_04 1022 "Error" 1023 "Not available" ;
VAL_ 2399089293 LonGndVel_L_04 8160 "Error" 8176 "Not available" ;
VAL_ 2399089293 LonGndVelStd_L_04 1022 "Error" 1023 "Not available" ;
VAL_ 2399089293 LatGndVel_L_04 8160 "Error" 8176 "Not available" ;
VAL_ 2399089293 LatGndVelStd_L_04 1022 "Error" 1023 "Not available" ;
VAL_ 2399089293 ExistenceProbability_L_04 254 "Error" 255 "Not available" ;
VAL_ 2399089293 Width_L_04 254 "Error" 255 "Not available" ;
VAL_ 2399089293 Length_L_04 1022 "Error" 1023 "Not available" ;
VAL_ 2399089293 HeadingAngle_L_04 254 "Error" 255 "Not available" ;
VAL_ 2399089293 DynamicProperty_L_04 0 "Invalid object" 1 "Stationary" 2 "Stopped" 3 "Moving" 6 "Error" 7 "Not available" ;
VAL_ 2399089293 ClassMostProb_L_04 0 "Unknown" 1 "Car" 2 "Motorbike" 3 "Truck" 4 "Bicycle" 5 "Pedestrian" 6 "Error" 7 "Not available" ;
VAL_ 2399089293 ClassMostProbConf_L_04 254 "Error" 255 "Not available" ;
VAL_ 2399089293 ClassSecMostProb_L_04 0 "Unknown" 1 "Car" 2 "Motorbike" 3 "Truck" 4 "Bicycle" 5 "Pedestrian" 6 "Error" 7 "Not available" ;
VAL_ 2399089293 ClassSecMostProbConf_L_04 254 "Error" 255 "Not available" ;
VAL_ 2399089293 MaintenanceState_L_04 0 "Not active" 1 "Newly created" 2 "Measured" 3 "Predicted" 6 "Error" 7 "Not available" ;
VAL_ 2399089293 YawRate_L_04 65024 "Error" 65280 "Not available" ;
VAL_ 2399089293 Occlusion_L_04 0 "Undefined" 1 "Occluded" 2 "On edge" 3 "Visible" 6 "Error" 7 "Not available" ;
VAL_ 2399089293 TrackingId_L_04 254 "Error" 255 "Not available" ;
VAL_ 2399089293 ReferencePoint_L_04 0 "Front left" 1 "Front" 2 "Front right" 3 "Right" 4 "Rear right" 5 "Rear" 6 "Rear left" 7 "Left" 8 "Unknown" 14 "Error" 15 "Not available" ;
VAL_ 2399089293 RadarCrossSection_L_04 2046 "Error" 2047 "Not available" ;
VAL_ 2399089293 AgeSinceCreated_L_04 1022 "Error" 1023 "Not available" ;
VAL_ 2399089549 BatchId_SRRObj_L_03 6 "Error" 7 "Not available" ;
VAL_ 2399089549 LonPosition_L_05 8160 "Error" 8176 "Not available" ;
VAL_ 2399089549 LonPositionStd_L_05 1022 "Error" 1023 "Not available" ;
VAL_ 2399089549 LatPosition_L_05 8160 "Error" 8176 "Not available" ;
VAL_ 2399089549 LatPositionStd_L_05 1022 "Error" 1023 "Not available" ;
VAL_ 2399089549 LonGndVel_L_05 8160 "Error" 8176 "Not available" ;
VAL_ 2399089549 LonGndVelStd_L_05 1022 "Error" 1023 "Not available" ;
VAL_ 2399089549 LatGndVel_L_05 8160 "Error" 8176 "Not available" ;
VAL_ 2399089549 LatGndVelStd_L_05 1022 "Error" 1023 "Not available" ;
VAL_ 2399089549 ExistenceProbability_L_05 254 "Error" 255 "Not available" ;
VAL_ 2399089549 Width_L_05 254 "Error" 255 "Not available" ;
VAL_ 2399089549 Length_L_05 1022 "Error" 1023 "Not available" ;
VAL_ 2399089549 HeadingAngle_L_05 254 "Error" 255 "Not available" ;
VAL_ 2399089549 DynamicProperty_L_05 0 "Invalid object" 1 "Stationary" 2 "Stopped" 3 "Moving" 6 "Error" 7 "Not available" ;
VAL_ 2399089549 ClassMostProb_L_05 0 "Unknown" 1 "Car" 2 "Motorbike" 3 "Truck" 4 "Bicycle" 5 "Pedestrian" 6 "Error" 7 "Not available" ;
VAL_ 2399089549 ClassMostProbConf_L_05 254 "Error" 255 "Not available" ;
VAL_ 2399089549 ClassSecMostProb_L_05 0 "Unknown" 1 "Car" 2 "Motorbike" 3 "Truck" 4 "Bicycle" 5 "Pedestrian" 6 "Error" 7 "Not available" ;
VAL_ 2399089549 ClassSecMostProbConf_L_05 254 "Error" 255 "Not available" ;
VAL_ 2399089549 MaintenanceState_L_05 0 "Not active" 1 "Newly created" 2 "Measured" 3 "Predicted" 6 "Error" 7 "Not available" ;
VAL_ 2399089549 YawRate_L_05 65024 "Error" 65280 "Not available" ;
VAL_ 2399089549 Occlusion_L_05 0 "Undefined" 1 "Occluded" 2 "On edge" 3 "Visible" 6 "Error" 7 "Not available" ;
VAL_ 2399089549 TrackingId_L_05 254 "Error" 255 "Not available" ;
VAL_ 2399089549 ReferencePoint_L_05 0 "Front left" 1 "Front" 2 "Front right" 3 "Right" 4 "Rear right" 5 "Rear" 6 "Rear left" 7 "Left" 8 "Unknown" 14 "Error" 15 "Not available" ;
VAL_ 2399089549 RadarCrossSection_L_05 2046 "Error" 2047 "Not available" ;
VAL_ 2399089549 AgeSinceCreated_L_05 1022 "Error" 1023 "Not available" ;
VAL_ 2399089549 LonPosition_L_06 8160 "Error" 8176 "Not available" ;
VAL_ 2399089549 LonPositionStd_L_06 1022 "Error" 1023 "Not available" ;
VAL_ 2399089549 LatPosition_L_06 8160 "Error" 8176 "Not available" ;
VAL_ 2399089549 LatPositionStd_L_06 1022 "Error" 1023 "Not available" ;
VAL_ 2399089549 LonGndVel_L_06 8160 "Error" 8176 "Not available" ;
VAL_ 2399089549 LonGndVelStd_L_06 1022 "Error" 1023 "Not available" ;
VAL_ 2399089549 LatGndVel_L_06 8160 "Error" 8176 "Not available" ;
VAL_ 2399089549 LatGndVelStd_L_06 1022 "Error" 1023 "Not available" ;
VAL_ 2399089549 ExistenceProbability_L_06 254 "Error" 255 "Not available" ;
VAL_ 2399089549 Width_L_06 254 "Error" 255 "Not available" ;
VAL_ 2399089549 Length_L_06 1022 "Error" 1023 "Not available" ;
VAL_ 2399089549 HeadingAngle_L_06 254 "Error" 255 "Not available" ;
VAL_ 2399089549 DynamicProperty_L_06 0 "Invalid object" 1 "Stationary" 2 "Stopped" 3 "Moving" 6 "Error" 7 "Not available" ;
VAL_ 2399089549 ClassMostProb_L_06 0 "Unknown" 1 "Car" 2 "Motorbike" 3 "Truck" 4 "Bicycle" 5 "Pedestrian" 6 "Error" 7 "Not available" ;
VAL_ 2399089549 ClassMostProbConf_L_06 254 "Error" 255 "Not available" ;
VAL_ 2399089549 ClassSecMostProb_L_06 0 "Unknown" 1 "Car" 2 "Motorbike" 3 "Truck" 4 "Bicycle" 5 "Pedestrian" 6 "Error" 7 "Not available" ;
VAL_ 2399089549 ClassSecMostProbConf_L_06 254 "Error" 255 "Not available" ;
VAL_ 2399089549 MaintenanceState_L_06 0 "Not active" 1 "Newly created" 2 "Measured" 3 "Predicted" 6 "Error" 7 "Not available" ;
VAL_ 2399089549 YawRate_L_06 65024 "Error" 65280 "Not available" ;
VAL_ 2399089549 Occlusion_L_06 0 "Undefined" 1 "Occluded" 2 "On edge" 3 "Visible" 6 "Error" 7 "Not available" ;
VAL_ 2399089549 TrackingId_L_06 254 "Error" 255 "Not available" ;
VAL_ 2399089549 ReferencePoint_L_06 0 "Front left" 1 "Front" 2 "Front right" 3 "Right" 4 "Rear right" 5 "Rear" 6 "Rear left" 7 "Left" 8 "Unknown" 14 "Error" 15 "Not available" ;
VAL_ 2399089549 RadarCrossSection_L_06 2046 "Error" 2047 "Not available" ;
VAL_ 2399089549 AgeSinceCreated_L_06 1022 "Error" 1023 "Not available" ;
VAL_ 2399089805 BatchId_SRRObj_L_04 6 "Error" 7 "Not available" ;
VAL_ 2399089805 LonPosition_L_07 8160 "Error" 8176 "Not available" ;
VAL_ 2399089805 LonPositionStd_L_07 1022 "Error" 1023 "Not available" ;
VAL_ 2399089805 LatPosition_L_07 8160 "Error" 8176 "Not available" ;
VAL_ 2399089805 LatPositionStd_L_07 1022 "Error" 1023 "Not available" ;
VAL_ 2399089805 LonGndVel_L_07 8160 "Error" 8176 "Not available" ;
VAL_ 2399089805 LonGndVelStd_L_07 1022 "Error" 1023 "Not available" ;
VAL_ 2399089805 LatGndVel_L_07 8160 "Error" 8176 "Not available" ;
VAL_ 2399089805 LatGndVelStd_L_07 1022 "Error" 1023 "Not available" ;
VAL_ 2399089805 ExistenceProbability_L_07 254 "Error" 255 "Not available" ;
VAL_ 2399089805 Width_L_07 254 "Error" 255 "Not available" ;
VAL_ 2399089805 Length_L_07 1022 "Error" 1023 "Not available" ;
VAL_ 2399089805 HeadingAngle_L_07 254 "Error" 255 "Not available" ;
VAL_ 2399089805 DynamicProperty_L_07 0 "Invalid object" 1 "Stationary" 2 "Stopped" 3 "Moving" 6 "Error" 7 "Not available" ;
VAL_ 2399089805 ClassMostProb_L_07 0 "Unknown" 1 "Car" 2 "Motorbike" 3 "Truck" 4 "Bicycle" 5 "Pedestrian" 6 "Error" 7 "Not available" ;
VAL_ 2399089805 ClassMostProbConf_L_07 254 "Error" 255 "Not available" ;
VAL_ 2399089805 ClassSecMostProb_L_07 0 "Unknown" 1 "Car" 2 "Motorbike" 3 "Truck" 4 "Bicycle" 5 "Pedestrian" 6 "Error" 7 "Not available" ;
VAL_ 2399089805 ClassSecMostProbConf_L_07 254 "Error" 255 "Not available" ;
VAL_ 2399089805 MaintenanceState_L_07 0 "Not active" 1 "Newly created" 2 "Measured" 3 "Predicted" 6 "Error" 7 "Not available" ;
VAL_ 2399089805 YawRate_L_07 65024 "Error" 65280 "Not available" ;
VAL_ 2399089805 Occlusion_L_07 0 "Undefined" 1 "Occluded" 2 "On edge" 3 "Visible" 6 "Error" 7 "Not available" ;
VAL_ 2399089805 TrackingId_L_07 254 "Error" 255 "Not available" ;
VAL_ 2399089805 ReferencePoint_L_07 0 "Front left" 1 "Front" 2 "Front right" 3 "Right" 4 "Rear right" 5 "Rear" 6 "Rear left" 7 "Left" 8 "Unknown" 14 "Error" 15 "Not available" ;
VAL_ 2399089805 RadarCrossSection_L_07 2046 "Error" 2047 "Not available" ;
VAL_ 2399089805 AgeSinceCreated_L_07 1022 "Error" 1023 "Not available" ;
VAL_ 2399089805 LonPosition_L_08 8160 "Error" 8176 "Not available" ;
VAL_ 2399089805 LonPositionStd_L_08 1022 "Error" 1023 "Not available" ;
VAL_ 2399089805 LatPosition_L_08 8160 "Error" 8176 "Not available" ;
VAL_ 2399089805 LatPositionStd_L_08 1022 "Error" 1023 "Not available" ;
VAL_ 2399089805 LonGndVel_L_08 8160 "Error" 8176 "Not available" ;
VAL_ 2399089805 LonGndVelStd_L_08 1022 "Error" 1023 "Not available" ;
VAL_ 2399089805 LatGndVel_L_08 8160 "Error" 8176 "Not available" ;
VAL_ 2399089805 LatGndVelStd_L_08 1022 "Error" 1023 "Not available" ;
VAL_ 2399089805 ExistenceProbability_L_08 254 "Error" 255 "Not available" ;
VAL_ 2399089805 Width_L_08 254 "Error" 255 "Not available" ;
VAL_ 2399089805 Length_L_08 1022 "Error" 1023 "Not available" ;
VAL_ 2399089805 HeadingAngle_L_08 254 "Error" 255 "Not available" ;
VAL_ 2399089805 DynamicProperty_L_08 0 "Invalid object" 1 "Stationary" 2 "Stopped" 3 "Moving" 6 "Error" 7 "Not available" ;
VAL_ 2399089805 ClassMostProb_L_08 0 "Unknown" 1 "Car" 2 "Motorbike" 3 "Truck" 4 "Bicycle" 5 "Pedestrian" 6 "Error" 7 "Not available" ;
VAL_ 2399089805 ClassMostProbConf_L_08 254 "Error" 255 "Not available" ;
VAL_ 2399089805 ClassSecMostProb_L_08 0 "Unknown" 1 "Car" 2 "Motorbike" 3 "Truck" 4 "Bicycle" 5 "Pedestrian" 6 "Error" 7 "Not available" ;
VAL_ 2399089805 ClassSecMostProbConf_L_08 254 "Error" 255 "Not available" ;
VAL_ 2399089805 MaintenanceState_L_08 0 "Not active" 1 "Newly created" 2 "Measured" 3 "Predicted" 6 "Error" 7 "Not available" ;
VAL_ 2399089805 YawRate_L_08 65024 "Error" 65280 "Not available" ;
VAL_ 2399089805 Occlusion_L_08 0 "Undefined" 1 "Occluded" 2 "On edge" 3 "Visible" 6 "Error" 7 "Not available" ;
VAL_ 2399089805 TrackingId_L_08 254 "Error" 255 "Not available" ;
VAL_ 2399089805 ReferencePoint_L_08 0 "Front left" 1 "Front" 2 "Front right" 3 "Right" 4 "Rear right" 5 "Rear" 6 "Rear left" 7 "Left" 8 "Unknown" 14 "Error" 15 "Not available" ;
VAL_ 2399089805 RadarCrossSection_L_08 2046 "Error" 2047 "Not available" ;
VAL_ 2399089805 AgeSinceCreated_L_08 1022 "Error" 1023 "Not available" ;
VAL_ 2399090061 BatchId_SRRObj_L_05 6 "Error" 7 "Not available" ;
VAL_ 2399090061 LonPosition_L_09 8160 "Error" 8176 "Not available" ;
VAL_ 2399090061 LonPositionStd_L_09 1022 "Error" 1023 "Not available" ;
VAL_ 2399090061 LatPosition_L_09 8160 "Error" 8176 "Not available" ;
VAL_ 2399090061 LatPositionStd_L_09 1022 "Error" 1023 "Not available" ;
VAL_ 2399090061 LonGndVel_L_09 8160 "Error" 8176 "Not available" ;
VAL_ 2399090061 LonGndVelStd_L_09 1022 "Error" 1023 "Not available" ;
VAL_ 2399090061 LatGndVel_L_09 8160 "Error" 8176 "Not available" ;
VAL_ 2399090061 LatGndVelStd_L_09 1022 "Error" 1023 "Not available" ;
VAL_ 2399090061 ExistenceProbability_L_09 254 "Error" 255 "Not available" ;
VAL_ 2399090061 Width_L_09 254 "Error" 255 "Not available" ;
VAL_ 2399090061 Length_L_09 1022 "Error" 1023 "Not available" ;
VAL_ 2399090061 HeadingAngle_L_09 254 "Error" 255 "Not available" ;
VAL_ 2399090061 DynamicProperty_L_09 0 "Invalid object" 1 "Stationary" 2 "Stopped" 3 "Moving" 6 "Error" 7 "Not available" ;
VAL_ 2399090061 ClassMostProb_L_09 0 "Unknown" 1 "Car" 2 "Motorbike" 3 "Truck" 4 "Bicycle" 5 "Pedestrian" 6 "Error" 7 "Not available" ;
VAL_ 2399090061 ClassMostProbConf_L_09 254 "Error" 255 "Not available" ;
VAL_ 2399090061 ClassSecMostProb_L_09 0 "Unknown" 1 "Car" 2 "Motorbike" 3 "Truck" 4 "Bicycle" 5 "Pedestrian" 6 "Error" 7 "Not available" ;
VAL_ 2399090061 ClassSecMostProbConf_L_09 254 "Error" 255 "Not available" ;
VAL_ 2399090061 MaintenanceState_L_09 0 "Not active" 1 "Newly created" 2 "Measured" 3 "Predicted" 6 "Error" 7 "Not available" ;
VAL_ 2399090061 YawRate_L_09 65024 "Error" 65280 "Not available" ;
VAL_ 2399090061 Occlusion_L_09 0 "Undefined" 1 "Occluded" 2 "On edge" 3 "Visible" 6 "Error" 7 "Not available" ;
VAL_ 2399090061 TrackingId_L_09 254 "Error" 255 "Not available" ;
VAL_ 2399090061 ReferencePoint_L_09 0 "Front left" 1 "Front" 2 "Front right" 3 "Right" 4 "Rear right" 5 "Rear" 6 "Rear left" 7 "Left" 8 "Unknown" 14 "Error" 15 "Not available" ;
VAL_ 2399090061 RadarCrossSection_L_09 2046 "Error" 2047 "Not available" ;
VAL_ 2399090061 AgeSinceCreated_L_09 1022 "Error" 1023 "Not available" ;
VAL_ 2399090061 LonPosition_L_10 8160 "Error" 8176 "Not available" ;
VAL_ 2399090061 LonPositionStd_L_10 1022 "Error" 1023 "Not available" ;
VAL_ 2399090061 LatPosition_L_10 8160 "Error" 8176 "Not available" ;
VAL_ 2399090061 LatPositionStd_L_10 1022 "Error" 1023 "Not available" ;
VAL_ 2399090061 LonGndVel_L_10 8160 "Error" 8176 "Not available" ;
VAL_ 2399090061 LonGndVelStd_L_10 1022 "Error" 1023 "Not available" ;
VAL_ 2399090061 LatGndVel_L_10 8160 "Error" 8176 "Not available" ;
VAL_ 2399090061 LatGndVelStd_L_10 1022 "Error" 1023 "Not available" ;
VAL_ 2399090061 ExistenceProbability_L_10 254 "Error" 255 "Not available" ;
VAL_ 2399090061 Width_L_10 254 "Error" 255 "Not available" ;
VAL_ 2399090061 Length_L_10 1022 "Error" 1023 "Not available" ;
VAL_ 2399090061 HeadingAngle_L_10 254 "Error" 255 "Not available" ;
VAL_ 2399090061 DynamicProperty_L_10 0 "Invalid object" 1 "Stationary" 2 "Stopped" 3 "Moving" 6 "Error" 7 "Not available" ;
VAL_ 2399090061 ClassMostProb_L_10 0 "Unknown" 1 "Car" 2 "Motorbike" 3 "Truck" 4 "Bicycle" 5 "Pedestrian" 6 "Error" 7 "Not available" ;
VAL_ 2399090061 ClassMostProbConf_L_10 254 "Error" 255 "Not available" ;
VAL_ 2399090061 ClassSecMostProb_L_10 0 "Unknown" 1 "Car" 2 "Motorbike" 3 "Truck" 4 "Bicycle" 5 "Pedestrian" 6 "Error" 7 "Not available" ;
VAL_ 2399090061 ClassSecMostProbConf_L_10 254 "Error" 255 "Not available" ;
VAL_ 2399090061 MaintenanceState_L_10 0 "Not active" 1 "Newly created" 2 "Measured" 3 "Predicted" 6 "Error" 7 "Not available" ;
VAL_ 2399090061 YawRate_L_10 65024 "Error" 65280 "Not available" ;
VAL_ 2399090061 Occlusion_L_10 0 "Undefined" 1 "Occluded" 2 "On edge" 3 "Visible" 6 "Error" 7 "Not available" ;
VAL_ 2399090061 TrackingId_L_10 254 "Error" 255 "Not available" ;
VAL_ 2399090061 ReferencePoint_L_10 0 "Front left" 1 "Front" 2 "Front right" 3 "Right" 4 "Rear right" 5 "Rear" 6 "Rear left" 7 "Left" 8 "Unknown" 14 "Error" 15 "Not available" ;
VAL_ 2399090061 RadarCrossSection_L_10 2046 "Error" 2047 "Not available" ;
VAL_ 2399090061 AgeSinceCreated_L_10 1022 "Error" 1023 "Not available" ;
VAL_ 2399090317 BatchId_SRRObj_L_06 6 "Error" 7 "Not available" ;
VAL_ 2399090317 LonPosition_L_11 8160 "Error" 8176 "Not available" ;
VAL_ 2399090317 LonPositionStd_L_11 1022 "Error" 1023 "Not available" ;
VAL_ 2399090317 LatPosition_L_11 8160 "Error" 8176 "Not available" ;
VAL_ 2399090317 LatPositionStd_L_11 1022 "Error" 1023 "Not available" ;
VAL_ 2399090317 LonGndVel_L_11 8160 "Error" 8176 "Not available" ;
VAL_ 2399090317 LonGndVelStd_L_11 1022 "Error" 1023 "Not available" ;
VAL_ 2399090317 LatGndVel_L_11 8160 "Error" 8176 "Not available" ;
VAL_ 2399090317 LatGndVelStd_L_11 1022 "Error" 1023 "Not available" ;
VAL_ 2399090317 ExistenceProbability_L_11 254 "Error" 255 "Not available" ;
VAL_ 2399090317 Width_L_11 254 "Error" 255 "Not available" ;
VAL_ 2399090317 Length_L_11 1022 "Error" 1023 "Not available" ;
VAL_ 2399090317 HeadingAngle_L_11 254 "Error" 255 "Not available" ;
VAL_ 2399090317 DynamicProperty_L_11 0 "Invalid object" 1 "Stationary" 2 "Stopped" 3 "Moving" 6 "Error" 7 "Not available" ;
VAL_ 2399090317 ClassMostProb_L_11 0 "Unknown" 1 "Car" 2 "Motorbike" 3 "Truck" 4 "Bicycle" 5 "Pedestrian" 6 "Error" 7 "Not available" ;
VAL_ 2399090317 ClassMostProbConf_L_11 254 "Error" 255 "Not available" ;
VAL_ 2399090317 ClassSecMostProb_L_11 0 "Unknown" 1 "Car" 2 "Motorbike" 3 "Truck" 4 "Bicycle" 5 "Pedestrian" 6 "Error" 7 "Not available" ;
VAL_ 2399090317 ClassSecMostProbConf_L_11 254 "Error" 255 "Not available" ;
VAL_ 2399090317 MaintenanceState_L_11 0 "Not active" 1 "Newly created" 2 "Measured" 3 "Predicted" 6 "Error" 7 "Not available" ;
VAL_ 2399090317 YawRate_L_11 65024 "Error" 65280 "Not available" ;
VAL_ 2399090317 Occlusion_L_11 0 "Undefined" 1 "Occluded" 2 "On edge" 3 "Visible" 6 "Error" 7 "Not available" ;
VAL_ 2399090317 TrackingId_L_11 254 "Error" 255 "Not available" ;
VAL_ 2399090317 ReferencePoint_L_11 0 "Front left" 1 "Front" 2 "Front right" 3 "Right" 4 "Rear right" 5 "Rear" 6 "Rear left" 7 "Left" 8 "Unknown" 14 "Error" 15 "Not available" ;
VAL_ 2399090317 RadarCrossSection_L_11 2046 "Error" 2047 "Not available" ;
VAL_ 2399090317 AgeSinceCreated_L_11 1022 "Error" 1023 "Not available" ;
VAL_ 2399090317 LonPosition_L_12 8160 "Error" 8176 "Not available" ;
VAL_ 2399090317 LonPositionStd_L_12 1022 "Error" 1023 "Not available" ;
VAL_ 2399090317 LatPosition_L_12 8160 "Error" 8176 "Not available" ;
VAL_ 2399090317 LatPositionStd_L_12 1022 "Error" 1023 "Not available" ;
VAL_ 2399090317 LonGndVel_L_12 8160 "Error" 8176 "Not available" ;
VAL_ 2399090317 LonGndVelStd_L_12 1022 "Error" 1023 "Not available" ;
VAL_ 2399090317 LatGndVel_L_12 8160 "Error" 8176 "Not available" ;
VAL_ 2399090317 LatGndVelStd_L_12 1022 "Error" 1023 "Not available" ;
VAL_ 2399090317 ExistenceProbability_L_12 254 "Error" 255 "Not available" ;
VAL_ 2399090317 Width_L_12 254 "Error" 255 "Not available" ;
VAL_ 2399090317 Length_L_12 1022 "Error" 1023 "Not available" ;
VAL_ 2399090317 HeadingAngle_L_12 254 "Error" 255 "Not available" ;
VAL_ 2399090317 DynamicProperty_L_12 0 "Invalid object" 1 "Stationary" 2 "Stopped" 3 "Moving" 6 "Error" 7 "Not available" ;
VAL_ 2399090317 ClassMostProb_L_12 0 "Unknown" 1 "Car" 2 "Motorbike" 3 "Truck" 4 "Bicycle" 5 "Pedestrian" 6 "Error" 7 "Not available" ;
VAL_ 2399090317 ClassMostProbConf_L_12 254 "Error" 255 "Not available" ;
VAL_ 2399090317 ClassSecMostProb_L_12 0 "Unknown" 1 "Car" 2 "Motorbike" 3 "Truck" 4 "Bicycle" 5 "Pedestrian" 6 "Error" 7 "Not available" ;
VAL_ 2399090317 ClassSecMostProbConf_L_12 254 "Error" 255 "Not available" ;
VAL_ 2399090317 MaintenanceState_L_12 0 "Not active" 1 "Newly created" 2 "Measured" 3 "Predicted" 6 "Error" 7 "Not available" ;
VAL_ 2399090317 YawRate_L_12 65024 "Error" 65280 "Not available" ;
VAL_ 2399090317 Occlusion_L_12 0 "Undefined" 1 "Occluded" 2 "On edge" 3 "Visible" 6 "Error" 7 "Not available" ;
VAL_ 2399090317 TrackingId_L_12 254 "Error" 255 "Not available" ;
VAL_ 2399090317 ReferencePoint_L_12 0 "Front left" 1 "Front" 2 "Front right" 3 "Right" 4 "Rear right" 5 "Rear" 6 "Rear left" 7 "Left" 8 "Unknown" 14 "Error" 15 "Not available" ;
VAL_ 2399090317 RadarCrossSection_L_12 2046 "Error" 2047 "Not available" ;
VAL_ 2399090317 AgeSinceCreated_L_12 1022 "Error" 1023 "Not available" ;
VAL_ 2399090573 BatchId_SRRObj_L_07 6 "Error" 7 "Not available" ;
VAL_ 2399090573 LonPosition_L_13 8160 "Error" 8176 "Not available" ;
VAL_ 2399090573 LonPositionStd_L_13 1022 "Error" 1023 "Not available" ;
VAL_ 2399090573 LatPosition_L_13 8160 "Error" 8176 "Not available" ;
VAL_ 2399090573 LatPositionStd_L_13 1022 "Error" 1023 "Not available" ;
VAL_ 2399090573 LonGndVel_L_13 8160 "Error" 8176 "Not available" ;
VAL_ 2399090573 LonGndVelStd_L_13 1022 "Error" 1023 "Not available" ;
VAL_ 2399090573 LatGndVel_L_13 8160 "Error" 8176 "Not available" ;
VAL_ 2399090573 LatGndVelStd_L_13 1022 "Error" 1023 "Not available" ;
VAL_ 2399090573 ExistenceProbability_L_13 254 "Error" 255 "Not available" ;
VAL_ 2399090573 Width_L_13 254 "Error" 255 "Not available" ;
VAL_ 2399090573 Length_L_13 1022 "Error" 1023 "Not available" ;
VAL_ 2399090573 HeadingAngle_L_13 254 "Error" 255 "Not available" ;
VAL_ 2399090573 DynamicProperty_L_13 0 "Invalid object" 1 "Stationary" 2 "Stopped" 3 "Moving" 6 "Error" 7 "Not available" ;
VAL_ 2399090573 ClassMostProb_L_13 0 "Unknown" 1 "Car" 2 "Motorbike" 3 "Truck" 4 "Bicycle" 5 "Pedestrian" 6 "Error" 7 "Not available" ;
VAL_ 2399090573 ClassMostProbConf_L_13 254 "Error" 255 "Not available" ;
VAL_ 2399090573 ClassSecMostProb_L_13 0 "Unknown" 1 "Car" 2 "Motorbike" 3 "Truck" 4 "Bicycle" 5 "Pedestrian" 6 "Error" 7 "Not available" ;
VAL_ 2399090573 ClassSecMostProbConf_L_13 254 "Error" 255 "Not available" ;
VAL_ 2399090573 MaintenanceState_L_13 0 "Not active" 1 "Newly created" 2 "Measured" 3 "Predicted" 6 "Error" 7 "Not available" ;
VAL_ 2399090573 YawRate_L_13 65024 "Error" 65280 "Not available" ;
VAL_ 2399090573 Occlusion_L_13 0 "Undefined" 1 "Occluded" 2 "On edge" 3 "Visible" 6 "Error" 7 "Not available" ;
VAL_ 2399090573 TrackingId_L_13 254 "Error" 255 "Not available" ;
VAL_ 2399090573 ReferencePoint_L_13 0 "Front left" 1 "Front" 2 "Front right" 3 "Right" 4 "Rear right" 5 "Rear" 6 "Rear left" 7 "Left" 8 "Unknown" 14 "Error" 15 "Not available" ;
VAL_ 2399090573 RadarCrossSection_L_13 2046 "Error" 2047 "Not available" ;
VAL_ 2399090573 AgeSinceCreated_L_13 1022 "Error" 1023 "Not available" ;
VAL_ 2399090573 LonPosition_L_14 8160 "Error" 8176 "Not available" ;
VAL_ 2399090573 LonPositionStd_L_14 1022 "Error" 1023 "Not available" ;
VAL_ 2399090573 LatPosition_L_14 8160 "Error" 8176 "Not available" ;
VAL_ 2399090573 LatPositionStd_L_14 1022 "Error" 1023 "Not available" ;
VAL_ 2399090573 LonGndVel_L_14 8160 "Error" 8176 "Not available" ;
VAL_ 2399090573 LonGndVelStd_L_14 1022 "Error" 1023 "Not available" ;
VAL_ 2399090573 LatGndVel_L_14 8160 "Error" 8176 "Not available" ;
VAL_ 2399090573 LatGndVelStd_L_14 1022 "Error" 1023 "Not available" ;
VAL_ 2399090573 ExistenceProbability_L_14 254 "Error" 255 "Not available" ;
VAL_ 2399090573 Width_L_14 254 "Error" 255 "Not available" ;
VAL_ 2399090573 Length_L_14 1022 "Error" 1023 "Not available" ;
VAL_ 2399090573 HeadingAngle_L_14 254 "Error" 255 "Not available" ;
VAL_ 2399090573 DynamicProperty_L_14 0 "Invalid object" 1 "Stationary" 2 "Stopped" 3 "Moving" 6 "Error" 7 "Not available" ;
VAL_ 2399090573 ClassMostProb_L_14 0 "Unknown" 1 "Car" 2 "Motorbike" 3 "Truck" 4 "Bicycle" 5 "Pedestrian" 6 "Error" 7 "Not available" ;
VAL_ 2399090573 ClassMostProbConf_L_14 254 "Error" 255 "Not available" ;
VAL_ 2399090573 ClassSecMostProb_L_14 0 "Unknown" 1 "Car" 2 "Motorbike" 3 "Truck" 4 "Bicycle" 5 "Pedestrian" 6 "Error" 7 "Not available" ;
VAL_ 2399090573 ClassSecMostProbConf_L_14 254 "Error" 255 "Not available" ;
VAL_ 2399090573 MaintenanceState_L_14 0 "Not active" 1 "Newly created" 2 "Measured" 3 "Predicted" 6 "Error" 7 "Not available" ;
VAL_ 2399090573 YawRate_L_14 65024 "Error" 65280 "Not available" ;
VAL_ 2399090573 Occlusion_L_14 0 "Undefined" 1 "Occluded" 2 "On edge" 3 "Visible" 6 "Error" 7 "Not available" ;
VAL_ 2399090573 TrackingId_L_14 254 "Error" 255 "Not available" ;
VAL_ 2399090573 ReferencePoint_L_14 0 "Front left" 1 "Front" 2 "Front right" 3 "Right" 4 "Rear right" 5 "Rear" 6 "Rear left" 7 "Left" 8 "Unknown" 14 "Error" 15 "Not available" ;
VAL_ 2399090573 RadarCrossSection_L_14 2046 "Error" 2047 "Not available" ;
VAL_ 2399090573 AgeSinceCreated_L_14 1022 "Error" 1023 "Not available" ;
VAL_ 2399090829 BatchId_SRRObj_L_08 6 "Error" 7 "Not available" ;
VAL_ 2399090829 LonPosition_L_15 8160 "Error" 8176 "Not available" ;
VAL_ 2399090829 LonPositionStd_L_15 1022 "Error" 1023 "Not available" ;
VAL_ 2399090829 LatPosition_L_15 8160 "Error" 8176 "Not available" ;
VAL_ 2399090829 LatPositionStd_L_15 1022 "Error" 1023 "Not available" ;
VAL_ 2399090829 LonGndVel_L_15 8160 "Error" 8176 "Not available" ;
VAL_ 2399090829 LonGndVelStd_L_15 1022 "Error" 1023 "Not available" ;
VAL_ 2399090829 LatGndVel_L_15 8160 "Error" 8176 "Not available" ;
VAL_ 2399090829 LatGndVelStd_L_15 1022 "Error" 1023 "Not available" ;
VAL_ 2399090829 ExistenceProbability_L_15 254 "Error" 255 "Not available" ;
VAL_ 2399090829 Width_L_15 254 "Error" 255 "Not available" ;
VAL_ 2399090829 Length_L_15 1022 "Error" 1023 "Not available" ;
VAL_ 2399090829 HeadingAngle_L_15 254 "Error" 255 "Not available" ;
VAL_ 2399090829 DynamicProperty_L_15 0 "Invalid object" 1 "Stationary" 2 "Stopped" 3 "Moving" 6 "Error" 7 "Not available" ;
VAL_ 2399090829 ClassMostProb_L_15 0 "Unknown" 1 "Car" 2 "Motorbike" 3 "Truck" 4 "Bicycle" 5 "Pedestrian" 6 "Error" 7 "Not available" ;
VAL_ 2399090829 ClassMostProbConf_L_15 254 "Error" 255 "Not available" ;
VAL_ 2399090829 ClassSecMostProb_L_15 0 "Unknown" 1 "Car" 2 "Motorbike" 3 "Truck" 4 "Bicycle" 5 "Pedestrian" 6 "Error" 7 "Not available" ;
VAL_ 2399090829 ClassSecMostProbConf_L_15 254 "Error" 255 "Not available" ;
VAL_ 2399090829 MaintenanceState_L_15 0 "Not active" 1 "Newly created" 2 "Measured" 3 "Predicted" 6 "Error" 7 "Not available" ;
VAL_ 2399090829 YawRate_L_15 65024 "Error" 65280 "Not available" ;
VAL_ 2399090829 Occlusion_L_15 0 "Undefined" 1 "Occluded" 2 "On edge" 3 "Visible" 6 "Error" 7 "Not available" ;
VAL_ 2399090829 TrackingId_L_15 254 "Error" 255 "Not available" ;
VAL_ 2399090829 ReferencePoint_L_15 0 "Front left" 1 "Front" 2 "Front right" 3 "Right" 4 "Rear right" 5 "Rear" 6 "Rear left" 7 "Left" 8 "Unknown" 14 "Error" 15 "Not available" ;
VAL_ 2399090829 RadarCrossSection_L_15 2046 "Error" 2047 "Not available" ;
VAL_ 2399090829 AgeSinceCreated_L_15 1022 "Error" 1023 "Not available" ;
VAL_ 2399090829 LonPosition_L_16 8160 "Error" 8176 "Not available" ;
VAL_ 2399090829 LonPositionStd_L_16 1022 "Error" 1023 "Not available" ;
VAL_ 2399090829 LatPosition_L_16 8160 "Error" 8176 "Not available" ;
VAL_ 2399090829 LatPositionStd_L_16 1022 "Error" 1023 "Not available" ;
VAL_ 2399090829 LonGndVel_L_16 8160 "Error" 8176 "Not available" ;
VAL_ 2399090829 LonGndVelStd_L_16 1022 "Error" 1023 "Not available" ;
VAL_ 2399090829 LatGndVel_L_16 8160 "Error" 8176 "Not available" ;
VAL_ 2399090829 LatGndVelStd_L_16 1022 "Error" 1023 "Not available" ;
VAL_ 2399090829 ExistenceProbability_L_16 254 "Error" 255 "Not available" ;
VAL_ 2399090829 Width_L_16 254 "Error" 255 "Not available" ;
VAL_ 2399090829 Length_L_16 1022 "Error" 1023 "Not available" ;
VAL_ 2399090829 HeadingAngle_L_16 254 "Error" 255 "Not available" ;
VAL_ 2399090829 DynamicProperty_L_16 0 "Invalid object" 1 "Stationary" 2 "Stopped" 3 "Moving" 6 "Error" 7 "Not available" ;
VAL_ 2399090829 ClassMostProb_L_16 0 "Unknown" 1 "Car" 2 "Motorbike" 3 "Truck" 4 "Bicycle" 5 "Pedestrian" 6 "Error" 7 "Not available" ;
VAL_ 2399090829 ClassMostProbConf_L_16 254 "Error" 255 "Not available" ;
VAL_ 2399090829 ClassSecMostProb_L_16 0 "Unknown" 1 "Car" 2 "Motorbike" 3 "Truck" 4 "Bicycle" 5 "Pedestrian" 6 "Error" 7 "Not available" ;
VAL_ 2399090829 ClassSecMostProbConf_L_16 254 "Error" 255 "Not available" ;
VAL_ 2399090829 MaintenanceState_L_16 0 "Not active" 1 "Newly created" 2 "Measured" 3 "Predicted" 6 "Error" 7 "Not available" ;
VAL_ 2399090829 YawRate_L_16 65024 "Error" 65280 "Not available" ;
VAL_ 2399090829 Occlusion_L_16 0 "Undefined" 1 "Occluded" 2 "On edge" 3 "Visible" 6 "Error" 7 "Not available" ;
VAL_ 2399090829 TrackingId_L_16 254 "Error" 255 "Not available" ;
VAL_ 2399090829 ReferencePoint_L_16 0 "Front left" 1 "Front" 2 "Front right" 3 "Right" 4 "Rear right" 5 "Rear" 6 "Rear left" 7 "Left" 8 "Unknown" 14 "Error" 15 "Not available" ;
VAL_ 2399090829 RadarCrossSection_L_16 2046 "Error" 2047 "Not available" ;
VAL_ 2399090829 AgeSinceCreated_L_16 1022 "Error" 1023 "Not available" ;
